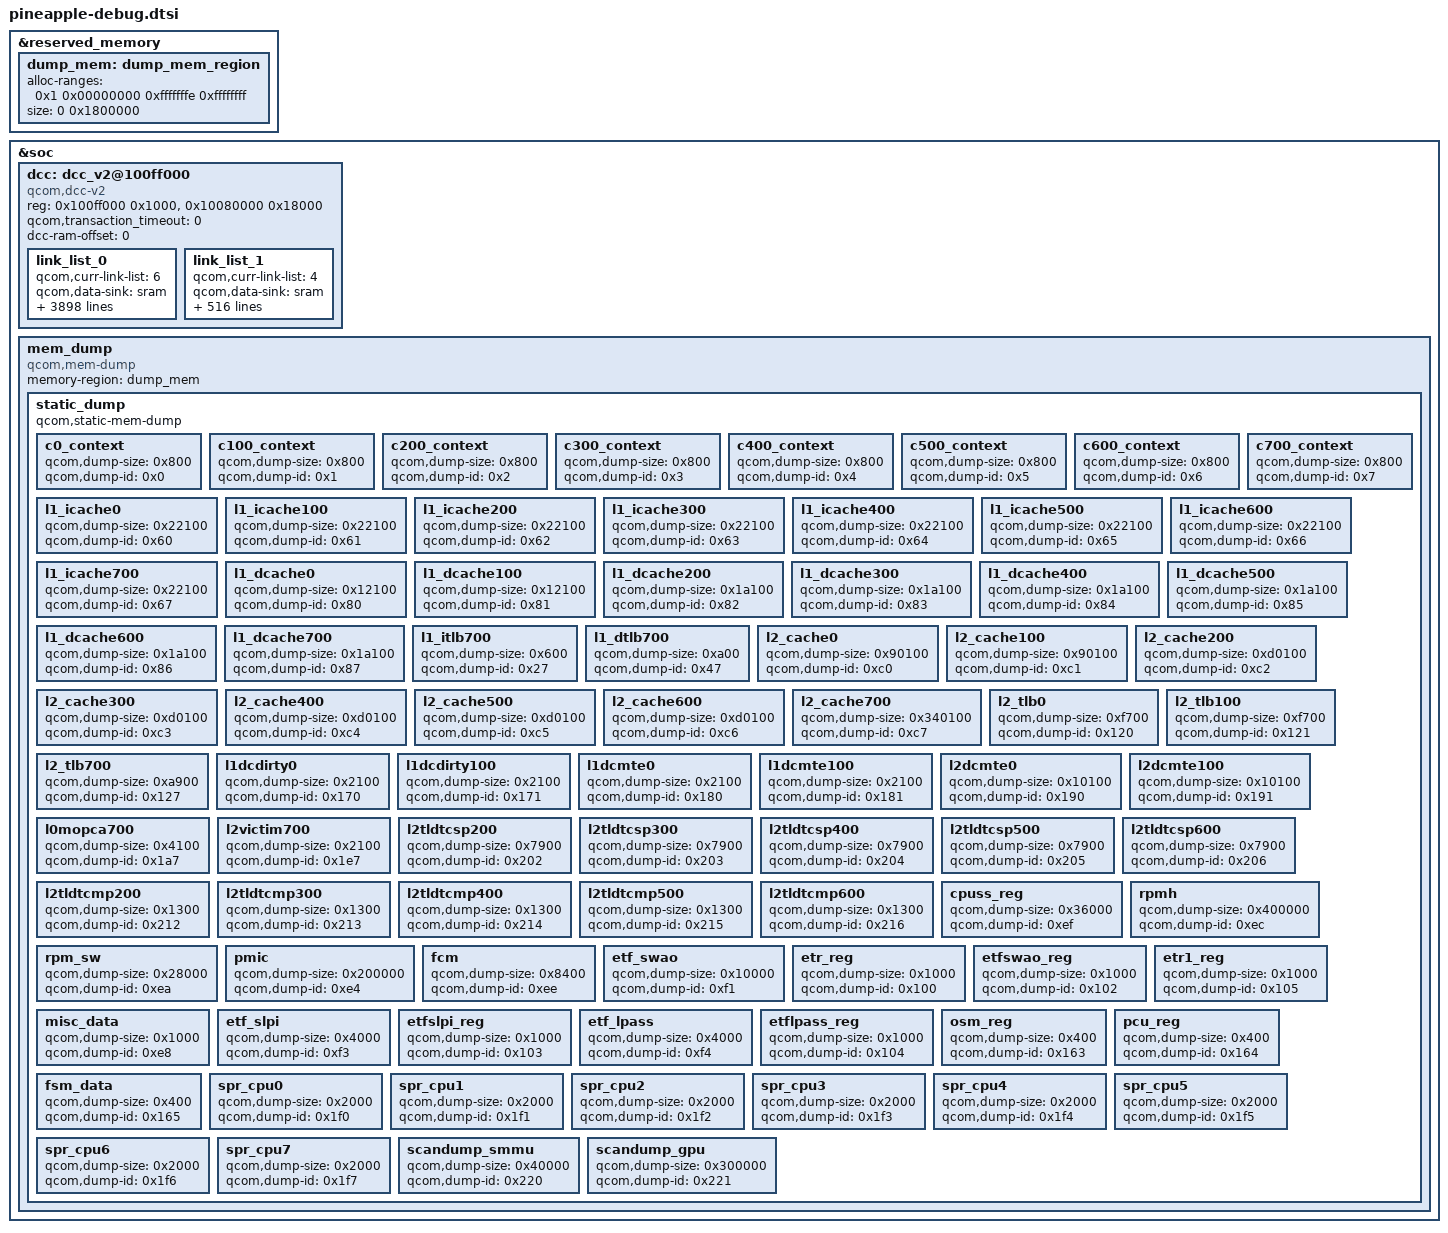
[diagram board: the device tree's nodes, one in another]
// SPDX-License-Identifier: BSD-3-Clause
/*
 * Copyright (c) 2022-2024 Qualcomm Innovation Center, Inc. All rights reserved.
 */

#include <dt-bindings/soc/qcom,dcc_v2.h>

&reserved_memory {
	#address-cells = <2>;
	#size-cells = <2>;
	ranges;

	dump_mem: dump_mem_region {
		alloc-ranges = <0x1 0x00000000 0xfffffffe 0xffffffff>;
		size = <0 0x1800000>;
	};
};

&soc {
	dcc: dcc_v2@100ff000 {
		compatible = "qcom,dcc-v2";
		reg = <0x100ff000 0x1000>,
		      <0x10080000 0x18000>;

		qcom,transaction_timeout = <0>;

		reg-names = "dcc-base", "dcc-ram-base";
		dcc-ram-offset = <0>;

		link_list_0 {
			qcom,curr-link-list = <6>;
			qcom,data-sink = "sram";
			qcom,link-list = <DCC_READ 0x68C0404 2 0>,
				<DCC_READ 0x68C0208 3 0>,
				<DCC_READ 0x68C0228 3 0>,
				<DCC_READ 0x68C0248 3 0>,
				<DCC_READ 0x68C0268 3 0>,
				<DCC_READ 0x68C040C 1 0>,
				<DCC_READ 0x68C0110 2 0>,
				<DCC_READ 0x68C011C 1 0>,
				<DCC_READ 0x7200404 2 0>,
				<DCC_READ 0x7200208 3 0>,
				<DCC_READ 0x7200228 3 0>,
				<DCC_READ 0x7200248 3 0>,
				<DCC_READ 0x7200268 3 0>,
				<DCC_READ 0x720040C 1 0>,
				<DCC_READ 0x7200110 2 0>,
				<DCC_READ 0x720011C 1 0>,
				<DCC_READ 0x7201c30 1 0>,
				<DCC_READ 0x7201ed0 1 0>,
				<DCC_READ 0x7202170 1 0>,
				<DCC_READ 0x7202410 1 0>,
				<DCC_READ 0x72026b0 1 0>,
				<DCC_READ 0x7202950 1 0>,
				<DCC_READ 0x7202bf0 1 0>,
				<DCC_READ 0x7202e90 1 0>,
				<DCC_READ 0x7203130 1 0>,
				<DCC_READ 0x72033d0 1 0>,
				<DCC_READ 0x7203670 1 0>,
				<DCC_READ 0x7201c48 1 0>,
				<DCC_READ 0x7201c60 1 0>,
				<DCC_READ 0x7201c78 1 0>,
				<DCC_READ 0x7201c90 1 0>,
				<DCC_READ 0x7201ca8 1 0>,
				<DCC_READ 0x7201cc0 1 0>,
				<DCC_READ 0x7201cd8 1 0>,
				<DCC_READ 0x7201cf0 1 0>,
				<DCC_READ 0x7201d08 1 0>,
				<DCC_READ 0x7201d20 1 0>,
				<DCC_READ 0x7201d38 1 0>,
				<DCC_READ 0x7201d50 1 0>,
				<DCC_READ 0x7201d68 1 0>,
				<DCC_READ 0x7201d80 1 0>,
				<DCC_READ 0x7201d98 1 0>,
				<DCC_READ 0x7201db0 1 0>,
				<DCC_READ 0x7201ee8 1 0>,
				<DCC_READ 0x7201f00 1 0>,
				<DCC_READ 0x7201f18 1 0>,
				<DCC_READ 0x7201f30 1 0>,
				<DCC_READ 0x7201f48 1 0>,
				<DCC_READ 0x7201f60 1 0>,
				<DCC_READ 0x7201f78 1 0>,
				<DCC_READ 0x7201f90 1 0>,
				<DCC_READ 0x7201fa8 1 0>,
				<DCC_READ 0x7201fc0 1 0>,
				<DCC_READ 0x7201fd8 1 0>,
				<DCC_READ 0x7201ff0 1 0>,
				<DCC_READ 0x7202008 1 0>,
				<DCC_READ 0x7202020 1 0>,
				<DCC_READ 0x7202038 1 0>,
				<DCC_READ 0x7202050 1 0>,
				<DCC_READ 0x7202188 1 0>,
				<DCC_READ 0x72021a0 1 0>,
				<DCC_READ 0x72021b8 1 0>,
				<DCC_READ 0x72021d0 1 0>,
				<DCC_READ 0x72021e8 1 0>,
				<DCC_READ 0x7202200 1 0>,
				<DCC_READ 0x7202218 1 0>,
				<DCC_READ 0x7202230 1 0>,
				<DCC_READ 0x7202248 1 0>,
				<DCC_READ 0x7202260 1 0>,
				<DCC_READ 0x7202278 1 0>,
				<DCC_READ 0x7202290 1 0>,
				<DCC_READ 0x72022a8 1 0>,
				<DCC_READ 0x72022c0 1 0>,
				<DCC_READ 0x72022d8 1 0>,
				<DCC_READ 0x72022f0 1 0>,
				<DCC_READ 0x7202428 1 0>,
				<DCC_READ 0x7202440 1 0>,
				<DCC_READ 0x7202458 1 0>,
				<DCC_READ 0x7202470 1 0>,
				<DCC_READ 0x7202488 1 0>,
				<DCC_READ 0x72024a0 1 0>,
				<DCC_READ 0x72024b8 1 0>,
				<DCC_READ 0x72024d0 1 0>,
				<DCC_READ 0x72024e8 1 0>,
				<DCC_READ 0x7202500 1 0>,
				<DCC_READ 0x7202518 1 0>,
				<DCC_READ 0x7202530 1 0>,
				<DCC_READ 0x7202548 1 0>,
				<DCC_READ 0x7202560 1 0>,
				<DCC_READ 0x7202578 1 0>,
				<DCC_READ 0x7202590 1 0>,
				<DCC_READ 0x72026c8 1 0>,
				<DCC_READ 0x72026e0 1 0>,
				<DCC_READ 0x72026f8 1 0>,
				<DCC_READ 0x7202710 1 0>,
				<DCC_READ 0x7202728 1 0>,
				<DCC_READ 0x7202740 1 0>,
				<DCC_READ 0x7202758 1 0>,
				<DCC_READ 0x7202770 1 0>,
				<DCC_READ 0x7202788 1 0>,
				<DCC_READ 0x72027a0 1 0>,
				<DCC_READ 0x72027b8 1 0>,
				<DCC_READ 0x72027d0 1 0>,
				<DCC_READ 0x72027e8 1 0>,
				<DCC_READ 0x7202800 1 0>,
				<DCC_READ 0x7202818 1 0>,
				<DCC_READ 0x7202830 1 0>,
				<DCC_READ 0x7202968 1 0>,
				<DCC_READ 0x7202980 1 0>,
				<DCC_READ 0x7202998 1 0>,
				<DCC_READ 0x72029b0 1 0>,
				<DCC_READ 0x72029c8 1 0>,
				<DCC_READ 0x72029e0 1 0>,
				<DCC_READ 0x72029f8 1 0>,
				<DCC_READ 0x7202a10 1 0>,
				<DCC_READ 0x7202a28 1 0>,
				<DCC_READ 0x7202a40 1 0>,
				<DCC_READ 0x7202a58 1 0>,
				<DCC_READ 0x7202a70 1 0>,
				<DCC_READ 0x7202a88 1 0>,
				<DCC_READ 0x7202aa0 1 0>,
				<DCC_READ 0x7202ab8 1 0>,
				<DCC_READ 0x7202ad0 1 0>,
				<DCC_READ 0x7202c08 1 0>,
				<DCC_READ 0x7202c20 1 0>,
				<DCC_READ 0x7202c38 1 0>,
				<DCC_READ 0x7202c50 1 0>,
				<DCC_READ 0x7202c68 1 0>,
				<DCC_READ 0x7202c80 1 0>,
				<DCC_READ 0x7202c98 1 0>,
				<DCC_READ 0x7202cb0 1 0>,
				<DCC_READ 0x7202cc8 1 0>,
				<DCC_READ 0x7202ce0 1 0>,
				<DCC_READ 0x7202cf8 1 0>,
				<DCC_READ 0x7202d10 1 0>,
				<DCC_READ 0x7202d28 1 0>,
				<DCC_READ 0x7202d40 1 0>,
				<DCC_READ 0x7202d58 1 0>,
				<DCC_READ 0x7202d70 1 0>,
				<DCC_READ 0x7202ea8 1 0>,
				<DCC_READ 0x7202ec0 1 0>,
				<DCC_READ 0x7202ed8 1 0>,
				<DCC_READ 0x7202ef0 1 0>,
				<DCC_READ 0x7202f08 1 0>,
				<DCC_READ 0x7202f20 1 0>,
				<DCC_READ 0x7202f38 1 0>,
				<DCC_READ 0x7202f50 1 0>,
				<DCC_READ 0x7202f68 1 0>,
				<DCC_READ 0x7202f80 1 0>,
				<DCC_READ 0x7202f98 1 0>,
				<DCC_READ 0x7202fb0 1 0>,
				<DCC_READ 0x7202fc8 1 0>,
				<DCC_READ 0x7202fe0 1 0>,
				<DCC_READ 0x7202ff8 1 0>,
				<DCC_READ 0x7203010 1 0>,
				<DCC_READ 0x7203148 1 0>,
				<DCC_READ 0x7203160 1 0>,
				<DCC_READ 0x7203178 1 0>,
				<DCC_READ 0x7203190 1 0>,
				<DCC_READ 0x72031a8 1 0>,
				<DCC_READ 0x72031c0 1 0>,
				<DCC_READ 0x72031d8 1 0>,
				<DCC_READ 0x72031f0 1 0>,
				<DCC_READ 0x7203208 1 0>,
				<DCC_READ 0x7203220 1 0>,
				<DCC_READ 0x7203238 1 0>,
				<DCC_READ 0x7203250 1 0>,
				<DCC_READ 0x7203268 1 0>,
				<DCC_READ 0x7203280 1 0>,
				<DCC_READ 0x7203298 1 0>,
				<DCC_READ 0x72032b0 1 0>,
				<DCC_READ 0x72033e8 1 0>,
				<DCC_READ 0x7203400 1 0>,
				<DCC_READ 0x7203418 1 0>,
				<DCC_READ 0x7203430 1 0>,
				<DCC_READ 0x7203448 1 0>,
				<DCC_READ 0x7203460 1 0>,
				<DCC_READ 0x7203478 1 0>,
				<DCC_READ 0x7203490 1 0>,
				<DCC_READ 0x72034a8 1 0>,
				<DCC_READ 0x72034c0 1 0>,
				<DCC_READ 0x72034d8 1 0>,
				<DCC_READ 0x72034f0 1 0>,
				<DCC_READ 0x7203508 1 0>,
				<DCC_READ 0x7203520 1 0>,
				<DCC_READ 0x7203538 1 0>,
				<DCC_READ 0x7203550 1 0>,
				<DCC_READ 0x7203688 1 0>,
				<DCC_READ 0x72036a0 1 0>,
				<DCC_READ 0x72036b8 1 0>,
				<DCC_READ 0x72036d0 1 0>,
				<DCC_READ 0x72036e8 1 0>,
				<DCC_READ 0x7203700 1 0>,
				<DCC_READ 0x7203718 1 0>,
				<DCC_READ 0x7203730 1 0>,
				<DCC_READ 0x7203748 1 0>,
				<DCC_READ 0x7203760 1 0>,
				<DCC_READ 0x7203778 1 0>,
				<DCC_READ 0x7203790 1 0>,
				<DCC_READ 0x72037a8 1 0>,
				<DCC_READ 0x72037c0 1 0>,
				<DCC_READ 0x72037d8 1 0>,
				<DCC_READ 0x72037f0 1 0>,
				<DCC_READ 0x323C0404 2 0>,
				<DCC_READ 0x323C0208 3 0>,
				<DCC_READ 0x323C0228 3 0>,
				<DCC_READ 0x323C0248 3 0>,
				<DCC_READ 0x323C0268 3 0>,
				<DCC_READ 0x323C040C 1 0>,
				<DCC_READ 0x323C0110 2 0>,
				<DCC_READ 0x323C011C 1 0>,
				<DCC_READ 0x320A4404 2 0>,
				<DCC_READ 0x320A4208 3 0>,
				<DCC_READ 0x320A4228 3 0>,
				<DCC_READ 0x320A4248 3 0>,
				<DCC_READ 0x320A4268 3 0>,
				<DCC_READ 0x320A440C 1 0>,
				<DCC_READ 0x320A4110 2 0>,
				<DCC_READ 0x320A411C 1 0>,
				<DCC_READ 0x320A4D30 1 0>,
				<DCC_READ 0x320A4Fd0 1 0>,
				<DCC_READ 0x320A5270 1 0>,
				<DCC_READ 0x320A5510 1 0>,
				<DCC_READ 0x320A57B0 1 0>,
				<DCC_READ 0x320A5A50 1 0>,
				<DCC_READ 0x320A5CF0 1 0>,
				<DCC_READ 0x320A5F90 1 0>,
				<DCC_READ 0x320a4d48 1 0>,
				<DCC_READ 0x320a4d60 1 0>,
				<DCC_READ 0x320a4d78 1 0>,
				<DCC_READ 0x320a4d90 1 0>,
				<DCC_READ 0x320a4da8 1 0>,
				<DCC_READ 0x320a4dc0 1 0>,
				<DCC_READ 0x320a4dd8 1 0>,
				<DCC_READ 0x320a4df0 1 0>,
				<DCC_READ 0x320a4e08 1 0>,
				<DCC_READ 0x320a4e20 1 0>,
				<DCC_READ 0x320a4e38 1 0>,
				<DCC_READ 0x320a4e50 1 0>,
				<DCC_READ 0x320a4e68 1 0>,
				<DCC_READ 0x320a4e80 1 0>,
				<DCC_READ 0x320a4e98 1 0>,
				<DCC_READ 0x320a4eb0 1 0>,
				<DCC_READ 0x320a4fe8 1 0>,
				<DCC_READ 0x320a5000 1 0>,
				<DCC_READ 0x320a5018 1 0>,
				<DCC_READ 0x320a5030 1 0>,
				<DCC_READ 0x320a5048 1 0>,
				<DCC_READ 0x320a5060 1 0>,
				<DCC_READ 0x320a5078 1 0>,
				<DCC_READ 0x320a5090 1 0>,
				<DCC_READ 0x320a50a8 1 0>,
				<DCC_READ 0x320a50c0 1 0>,
				<DCC_READ 0x320a50d8 1 0>,
				<DCC_READ 0x320a50f0 1 0>,
				<DCC_READ 0x320a5108 1 0>,
				<DCC_READ 0x320a5120 1 0>,
				<DCC_READ 0x320a5138 1 0>,
				<DCC_READ 0x320a5150 1 0>,
				<DCC_READ 0x320a5288 1 0>,
				<DCC_READ 0x320a52a0 1 0>,
				<DCC_READ 0x320a52b8 1 0>,
				<DCC_READ 0x320a52d0 1 0>,
				<DCC_READ 0x320a52e8 1 0>,
				<DCC_READ 0x320a5300 1 0>,
				<DCC_READ 0x320a5318 1 0>,
				<DCC_READ 0x320a5330 1 0>,
				<DCC_READ 0x320a5348 1 0>,
				<DCC_READ 0x320a5360 1 0>,
				<DCC_READ 0x320a5378 1 0>,
				<DCC_READ 0x320a5390 1 0>,
				<DCC_READ 0x320a53a8 1 0>,
				<DCC_READ 0x320a53c0 1 0>,
				<DCC_READ 0x320a53d8 1 0>,
				<DCC_READ 0x320a53f0 1 0>,
				<DCC_READ 0x320a5528 1 0>,
				<DCC_READ 0x320a5540 1 0>,
				<DCC_READ 0x320a5558 1 0>,
				<DCC_READ 0x320a5570 1 0>,
				<DCC_READ 0x320a5588 1 0>,
				<DCC_READ 0x320a55a0 1 0>,
				<DCC_READ 0x320a55b8 1 0>,
				<DCC_READ 0x320a55d0 1 0>,
				<DCC_READ 0x320a55e8 1 0>,
				<DCC_READ 0x320a5600 1 0>,
				<DCC_READ 0x320a5618 1 0>,
				<DCC_READ 0x320a5630 1 0>,
				<DCC_READ 0x320a5648 1 0>,
				<DCC_READ 0x320a5660 1 0>,
				<DCC_READ 0x320a5678 1 0>,
				<DCC_READ 0x320a5690 1 0>,
				<DCC_READ 0x320a57c8 1 0>,
				<DCC_READ 0x320a57e0 1 0>,
				<DCC_READ 0x320a57f8 1 0>,
				<DCC_READ 0x320a5810 1 0>,
				<DCC_READ 0x320a5828 1 0>,
				<DCC_READ 0x320a5840 1 0>,
				<DCC_READ 0x320a5858 1 0>,
				<DCC_READ 0x320a5870 1 0>,
				<DCC_READ 0x320a5888 1 0>,
				<DCC_READ 0x320a58a0 1 0>,
				<DCC_READ 0x320a58b8 1 0>,
				<DCC_READ 0x320a58d0 1 0>,
				<DCC_READ 0x320a58e8 1 0>,
				<DCC_READ 0x320a5900 1 0>,
				<DCC_READ 0x320a5918 1 0>,
				<DCC_READ 0x320a5930 1 0>,
				<DCC_READ 0x320a5a68 1 0>,
				<DCC_READ 0x320a5a80 1 0>,
				<DCC_READ 0x320a5a98 1 0>,
				<DCC_READ 0x320a5ab0 1 0>,
				<DCC_READ 0x320a5ac8 1 0>,
				<DCC_READ 0x320a5ae0 1 0>,
				<DCC_READ 0x320a5af8 1 0>,
				<DCC_READ 0x320a5b10 1 0>,
				<DCC_READ 0x320a5b28 1 0>,
				<DCC_READ 0x320a5b40 1 0>,
				<DCC_READ 0x320a5b58 1 0>,
				<DCC_READ 0x320a5b70 1 0>,
				<DCC_READ 0x320a5b88 1 0>,
				<DCC_READ 0x320a5ba0 1 0>,
				<DCC_READ 0x320a5bb8 1 0>,
				<DCC_READ 0x320a5bd0 1 0>,
				<DCC_READ 0x320a5d08 1 0>,
				<DCC_READ 0x320a5d20 1 0>,
				<DCC_READ 0x320a5d38 1 0>,
				<DCC_READ 0x320a5d50 1 0>,
				<DCC_READ 0x320a5d68 1 0>,
				<DCC_READ 0x320a5d80 1 0>,
				<DCC_READ 0x320a5d98 1 0>,
				<DCC_READ 0x320a5db0 1 0>,
				<DCC_READ 0x320a5dc8 1 0>,
				<DCC_READ 0x320a5de0 1 0>,
				<DCC_READ 0x320a5df8 1 0>,
				<DCC_READ 0x320a5e10 1 0>,
				<DCC_READ 0x320a5e28 1 0>,
				<DCC_READ 0x320a5e40 1 0>,
				<DCC_READ 0x320a5e58 1 0>,
				<DCC_READ 0x320a5e70 1 0>,
				<DCC_READ 0x320a5fa8 1 0>,
				<DCC_READ 0x320a5fc0 1 0>,
				<DCC_READ 0x320a5fd8 1 0>,
				<DCC_READ 0x320a5ff0 1 0>,
				<DCC_READ 0x320a6008 1 0>,
				<DCC_READ 0x320a6020 1 0>,
				<DCC_READ 0x320a6038 1 0>,
				<DCC_READ 0x320a6050 1 0>,
				<DCC_READ 0x320a6068 1 0>,
				<DCC_READ 0x320a6080 1 0>,
				<DCC_READ 0x320a6098 1 0>,
				<DCC_READ 0x320a60b0 1 0>,
				<DCC_READ 0x320a60c8 1 0>,
				<DCC_READ 0x320a60e0 1 0>,
				<DCC_READ 0x320a60f8 1 0>,
				<DCC_READ 0x4082028 1 0>,
				<DCC_READ 0x4140404 2 0>,
				<DCC_READ 0x4140208 3 0>,
				<DCC_READ 0x4140228 3 0>,
				<DCC_READ 0x4140248 3 0>,
				<DCC_READ 0x4140268 3 0>,
				<DCC_READ 0x414040C 1 0>,
				<DCC_READ 0x4140110 2 0>,
				<DCC_READ 0x414011C 1 0>,
				<DCC_READ 0x4200404 2 0>,
				<DCC_READ 0x4200208 3 0>,
				<DCC_READ 0x4200228 3 0>,
				<DCC_READ 0x4200248 3 0>,
				<DCC_READ 0x4200268 3 0>,
				<DCC_READ 0x420040C 1 0>,
				<DCC_READ 0x4200110 2 0>,
				<DCC_READ 0x420011C 1 0>,
				<DCC_READ 0x4200d30 1 0>,
				<DCC_READ 0x4200fd0 1 0>,
				<DCC_READ 0x4201270 1 0>,
				<DCC_READ 0x4201510 1 0>,
				<DCC_READ 0x42017b0 1 0>,
				<DCC_READ 0x4201a50 1 0>,
				<DCC_READ 0x4201cf0 1 0>,
				<DCC_READ 0x4201f90 1 0>,
				<DCC_READ 0x4202230 1 0>,
				<DCC_READ 0x42024d0 1 0>,
				<DCC_READ 0x4202770 1 0>,
				<DCC_READ 0x4202a10 1 0>,
				<DCC_READ 0x4202cb0 1 0>,
				<DCC_READ 0x4202f50 1 0>,
				<DCC_READ 0x4200d48 1 0>,
				<DCC_READ 0x4200d60 1 0>,
				<DCC_READ 0x4200d78 1 0>,
				<DCC_READ 0x4200d90 1 0>,
				<DCC_READ 0x4200da8 1 0>,
				<DCC_READ 0x4200dc0 1 0>,
				<DCC_READ 0x4200dd8 1 0>,
				<DCC_READ 0x4200df0 1 0>,
				<DCC_READ 0x4200e08 1 0>,
				<DCC_READ 0x4200e20 1 0>,
				<DCC_READ 0x4200e38 1 0>,
				<DCC_READ 0x4200e50 1 0>,
				<DCC_READ 0x4200e68 1 0>,
				<DCC_READ 0x4200e80 1 0>,
				<DCC_READ 0x4200e98 1 0>,
				<DCC_READ 0x4200eb0 1 0>,
				<DCC_READ 0x4200fe8 1 0>,
				<DCC_READ 0x4201000 1 0>,
				<DCC_READ 0x4201018 1 0>,
				<DCC_READ 0x4201030 1 0>,
				<DCC_READ 0x4201048 1 0>,
				<DCC_READ 0x4201060 1 0>,
				<DCC_READ 0x4201078 1 0>,
				<DCC_READ 0x4201090 1 0>,
				<DCC_READ 0x42010a8 1 0>,
				<DCC_READ 0x42010c0 1 0>,
				<DCC_READ 0x42010d8 1 0>,
				<DCC_READ 0x42010f0 1 0>,
				<DCC_READ 0x4201108 1 0>,
				<DCC_READ 0x4201120 1 0>,
				<DCC_READ 0x4201138 1 0>,
				<DCC_READ 0x4201150 1 0>,
				<DCC_READ 0x4201288 1 0>,
				<DCC_READ 0x42012a0 1 0>,
				<DCC_READ 0x42012b8 1 0>,
				<DCC_READ 0x42012d0 1 0>,
				<DCC_READ 0x42012e8 1 0>,
				<DCC_READ 0x4201300 1 0>,
				<DCC_READ 0x4201318 1 0>,
				<DCC_READ 0x4201330 1 0>,
				<DCC_READ 0x4201348 1 0>,
				<DCC_READ 0x4201360 1 0>,
				<DCC_READ 0x4201378 1 0>,
				<DCC_READ 0x4201390 1 0>,
				<DCC_READ 0x42013a8 1 0>,
				<DCC_READ 0x42013c0 1 0>,
				<DCC_READ 0x42013d8 1 0>,
				<DCC_READ 0x42013f0 1 0>,
				<DCC_READ 0x4201528 1 0>,
				<DCC_READ 0x4201540 1 0>,
				<DCC_READ 0x4201558 1 0>,
				<DCC_READ 0x4201570 1 0>,
				<DCC_READ 0x4201588 1 0>,
				<DCC_READ 0x42015a0 1 0>,
				<DCC_READ 0x42015b8 1 0>,
				<DCC_READ 0x42015d0 1 0>,
				<DCC_READ 0x42015e8 1 0>,
				<DCC_READ 0x4201600 1 0>,
				<DCC_READ 0x4201618 1 0>,
				<DCC_READ 0x4201630 1 0>,
				<DCC_READ 0x4201648 1 0>,
				<DCC_READ 0x4201660 1 0>,
				<DCC_READ 0x4201678 1 0>,
				<DCC_READ 0x4201690 1 0>,
				<DCC_READ 0x42017c8 1 0>,
				<DCC_READ 0x42017e0 1 0>,
				<DCC_READ 0x42017f8 1 0>,
				<DCC_READ 0x4201810 1 0>,
				<DCC_READ 0x4201828 1 0>,
				<DCC_READ 0x4201840 1 0>,
				<DCC_READ 0x4201858 1 0>,
				<DCC_READ 0x4201870 1 0>,
				<DCC_READ 0x4201888 1 0>,
				<DCC_READ 0x42018a0 1 0>,
				<DCC_READ 0x42018b8 1 0>,
				<DCC_READ 0x42018d0 1 0>,
				<DCC_READ 0x42018e8 1 0>,
				<DCC_READ 0x4201900 1 0>,
				<DCC_READ 0x4201918 1 0>,
				<DCC_READ 0x4201930 1 0>,
				<DCC_READ 0x4201a68 1 0>,
				<DCC_READ 0x4201a80 1 0>,
				<DCC_READ 0x4201a98 1 0>,
				<DCC_READ 0x4201ab0 1 0>,
				<DCC_READ 0x4201ac8 1 0>,
				<DCC_READ 0x4201ae0 1 0>,
				<DCC_READ 0x4201af8 1 0>,
				<DCC_READ 0x4201b10 1 0>,
				<DCC_READ 0x4201b28 1 0>,
				<DCC_READ 0x4201b40 1 0>,
				<DCC_READ 0x4201b58 1 0>,
				<DCC_READ 0x4201b70 1 0>,
				<DCC_READ 0x4201b88 1 0>,
				<DCC_READ 0x4201ba0 1 0>,
				<DCC_READ 0x4201bb8 1 0>,
				<DCC_READ 0x4201bd0 1 0>,
				<DCC_READ 0x4201d08 1 0>,
				<DCC_READ 0x4201d20 1 0>,
				<DCC_READ 0x4201d38 1 0>,
				<DCC_READ 0x4201d50 1 0>,
				<DCC_READ 0x4201d68 1 0>,
				<DCC_READ 0x4201d80 1 0>,
				<DCC_READ 0x4201d98 1 0>,
				<DCC_READ 0x4201db0 1 0>,
				<DCC_READ 0x4201dc8 1 0>,
				<DCC_READ 0x4201de0 1 0>,
				<DCC_READ 0x4201df8 1 0>,
				<DCC_READ 0x4201e10 1 0>,
				<DCC_READ 0x4201e28 1 0>,
				<DCC_READ 0x4201e40 1 0>,
				<DCC_READ 0x4201e58 1 0>,
				<DCC_READ 0x4201e70 1 0>,
				<DCC_READ 0x4201fa8 1 0>,
				<DCC_READ 0x4201fc0 1 0>,
				<DCC_READ 0x4201fd8 1 0>,
				<DCC_READ 0x4201ff0 1 0>,
				<DCC_READ 0x4202008 1 0>,
				<DCC_READ 0x4202020 1 0>,
				<DCC_READ 0x4202038 1 0>,
				<DCC_READ 0x4202050 1 0>,
				<DCC_READ 0x4202068 1 0>,
				<DCC_READ 0x4202080 1 0>,
				<DCC_READ 0x4202098 1 0>,
				<DCC_READ 0x42020b0 1 0>,
				<DCC_READ 0x42020c8 1 0>,
				<DCC_READ 0x42020e0 1 0>,
				<DCC_READ 0x42020f8 1 0>,
				<DCC_READ 0x4202110 1 0>,
				<DCC_READ 0x4202248 1 0>,
				<DCC_READ 0x4202260 1 0>,
				<DCC_READ 0x4202278 1 0>,
				<DCC_READ 0x4202290 1 0>,
				<DCC_READ 0x42022a8 1 0>,
				<DCC_READ 0x42022c0 1 0>,
				<DCC_READ 0x42022d8 1 0>,
				<DCC_READ 0x42022f0 1 0>,
				<DCC_READ 0x4202308 1 0>,
				<DCC_READ 0x4202320 1 0>,
				<DCC_READ 0x4202338 1 0>,
				<DCC_READ 0x4202350 1 0>,
				<DCC_READ 0x4202368 1 0>,
				<DCC_READ 0x4202380 1 0>,
				<DCC_READ 0x4202398 1 0>,
				<DCC_READ 0x42023b0 1 0>,
				<DCC_READ 0x42024e8 1 0>,
				<DCC_READ 0x4202500 1 0>,
				<DCC_READ 0x4202518 1 0>,
				<DCC_READ 0x4202530 1 0>,
				<DCC_READ 0x4202548 1 0>,
				<DCC_READ 0x4202560 1 0>,
				<DCC_READ 0x4202578 1 0>,
				<DCC_READ 0x4202590 1 0>,
				<DCC_READ 0x42025a8 1 0>,
				<DCC_READ 0x42025c0 1 0>,
				<DCC_READ 0x42025d8 1 0>,
				<DCC_READ 0x42025f0 1 0>,
				<DCC_READ 0x4202608 1 0>,
				<DCC_READ 0x4202620 1 0>,
				<DCC_READ 0x4202638 1 0>,
				<DCC_READ 0x4202650 1 0>,
				<DCC_READ 0x4202788 1 0>,
				<DCC_READ 0x42027a0 1 0>,
				<DCC_READ 0x42027b8 1 0>,
				<DCC_READ 0x42027d0 1 0>,
				<DCC_READ 0x42027e8 1 0>,
				<DCC_READ 0x4202800 1 0>,
				<DCC_READ 0x4202818 1 0>,
				<DCC_READ 0x4202830 1 0>,
				<DCC_READ 0x4202848 1 0>,
				<DCC_READ 0x4202860 1 0>,
				<DCC_READ 0x4202878 1 0>,
				<DCC_READ 0x4202890 1 0>,
				<DCC_READ 0x42028a8 1 0>,
				<DCC_READ 0x42028c0 1 0>,
				<DCC_READ 0x42028d8 1 0>,
				<DCC_READ 0x42028f0 1 0>,
				<DCC_READ 0x4202a28 1 0>,
				<DCC_READ 0x4202a40 1 0>,
				<DCC_READ 0x4202a58 1 0>,
				<DCC_READ 0x4202a70 1 0>,
				<DCC_READ 0x4202a88 1 0>,
				<DCC_READ 0x4202aa0 1 0>,
				<DCC_READ 0x4202ab8 1 0>,
				<DCC_READ 0x4202ad0 1 0>,
				<DCC_READ 0x4202ae8 1 0>,
				<DCC_READ 0x4202b00 1 0>,
				<DCC_READ 0x4202b18 1 0>,
				<DCC_READ 0x4202b30 1 0>,
				<DCC_READ 0x4202b48 1 0>,
				<DCC_READ 0x4202b60 1 0>,
				<DCC_READ 0x4202b78 1 0>,
				<DCC_READ 0x4202b90 1 0>,
				<DCC_READ 0x4202cc8 1 0>,
				<DCC_READ 0x4202ce0 1 0>,
				<DCC_READ 0x4202cf8 1 0>,
				<DCC_READ 0x4202d10 1 0>,
				<DCC_READ 0x4202d28 1 0>,
				<DCC_READ 0x4202d40 1 0>,
				<DCC_READ 0x4202d58 1 0>,
				<DCC_READ 0x4202d70 1 0>,
				<DCC_READ 0x4202d88 1 0>,
				<DCC_READ 0x4202da0 1 0>,
				<DCC_READ 0x4202db8 1 0>,
				<DCC_READ 0x4202dd0 1 0>,
				<DCC_READ 0x4202de8 1 0>,
				<DCC_READ 0x4202e00 1 0>,
				<DCC_READ 0x4202e18 1 0>,
				<DCC_READ 0x4202e30 1 0>,
				<DCC_READ 0x4202f68 1 0>,
				<DCC_READ 0x4202f80 1 0>,
				<DCC_READ 0x4202f98 1 0>,
				<DCC_READ 0x4202fb0 1 0>,
				<DCC_READ 0x4202fc8 1 0>,
				<DCC_READ 0x4202fe0 1 0>,
				<DCC_READ 0x4202ff8 1 0>,
				<DCC_READ 0x4203010 1 0>,
				<DCC_READ 0x4203028 1 0>,
				<DCC_READ 0x4203040 1 0>,
				<DCC_READ 0x4203058 1 0>,
				<DCC_READ 0x4203070 1 0>,
				<DCC_READ 0x4203088 1 0>,
				<DCC_READ 0x42030a0 1 0>,
				<DCC_READ 0x42030b8 1 0>,
				<DCC_READ 0x42030d0 1 0>,
				<DCC_READ 0x6E0A100 1 0>,
				<DCC_READ 0x6E0A0AC 1 0>,
				<DCC_READ 0x6E0A0B0 1 0>,
				<DCC_READ 0x6E21104 1 0>,
				<DCC_READ 0x6E21108 1 0>,
				<DCC_READ 0x6E212AC 1 0>,
				<DCC_READ 0x6E212B0 1 0>,
				<DCC_READ 0x6E21300 1 0>,
				<DCC_READ 0x6E0A000 1 0>,
				<DCC_READ 0x7402048 1 0>,
				<DCC_READ 0x7402040 1 0>,
				<DCC_READ 0x25a01000 6 0>,
				<DCC_READ 0x25a00000 6 0>,
				<DCC_READ 0x25a03000 6 0>,
				<DCC_READ 0x25a04000 6 0>,
				<DCC_READ 0x25a02000 6 0>,
				<DCC_READ 0x25a05000 6 0>,
				<DCC_READ 0x25a06000 6 0>,
				<DCC_READ 0x25a07000 6 0>,
				<DCC_READ 0x25a08000 6 0>,
				<DCC_READ 0x25a09000 6 0>,
				<DCC_READ 0x25a0a000 6 0>,
				<DCC_READ 0x25a0b000 6 0>,
				<DCC_READ 0x25a0c000 6 0>,
				<DCC_READ 0x25a0d000 6 0>,
				<DCC_READ 0x25a0e000 6 0>,
				<DCC_READ 0x25a0f000 6 0>,
				<DCC_READ 0x25a10000 6 0>,
				<DCC_READ 0x25a11000 6 0>,
				<DCC_READ 0x25a12000 6 0>,
				<DCC_READ 0x25a13000 6 0>,
				<DCC_READ 0x25a14000 6 0>,
				<DCC_READ 0x25a15000 6 0>,
				<DCC_READ 0x25a16000 6 0>,
				<DCC_READ 0x25a17000 6 0>,
				<DCC_READ 0x25a18000 6 0>,
				<DCC_READ 0x25a19000 6 0>,
				<DCC_READ 0x25a1a000 6 0>,
				<DCC_READ 0x25a1b000 6 0>,
				<DCC_READ 0x25a1c000 6 0>,
				<DCC_READ 0x25a1d000 6 0>,
				<DCC_READ 0x25a1e000 6 0>,
				<DCC_READ 0x25a1f000 6 0>,
				<DCC_READ 0x25001000 6 0>,
				<DCC_READ 0x25000000 6 0>,
				<DCC_READ 0x25003000 6 0>,
				<DCC_READ 0x25004000 6 0>,
				<DCC_READ 0x25002000 6 0>,
				<DCC_READ 0x25005000 6 0>,
				<DCC_READ 0x25006000 6 0>,
				<DCC_READ 0x25007000 6 0>,
				<DCC_READ 0x25008000 6 0>,
				<DCC_READ 0x25009000 6 0>,
				<DCC_READ 0x2500a000 6 0>,
				<DCC_READ 0x2500b000 6 0>,
				<DCC_READ 0x2500c000 6 0>,
				<DCC_READ 0x2500d000 6 0>,
				<DCC_READ 0x2500e000 6 0>,
				<DCC_READ 0x2500f000 6 0>,
				<DCC_READ 0x25010000 6 0>,
				<DCC_READ 0x25011000 6 0>,
				<DCC_READ 0x25012000 6 0>,
				<DCC_READ 0x25013000 6 0>,
				<DCC_READ 0x25014000 6 0>,
				<DCC_READ 0x25015000 6 0>,
				<DCC_READ 0x25016000 6 0>,
				<DCC_READ 0x25017000 6 0>,
				<DCC_READ 0x25018000 6 0>,
				<DCC_READ 0x25019000 6 0>,
				<DCC_READ 0x2501a000 6 0>,
				<DCC_READ 0x2501b000 6 0>,
				<DCC_READ 0x2501c000 6 0>,
				<DCC_READ 0x2501d000 6 0>,
				<DCC_READ 0x2501e000 6 0>,
				<DCC_READ 0x2501f000 6 0>,
				<DCC_READ 0x25201000 6 0>,
				<DCC_READ 0x25200000 6 0>,
				<DCC_READ 0x25203000 6 0>,
				<DCC_READ 0x25204000 6 0>,
				<DCC_READ 0x25202000 6 0>,
				<DCC_READ 0x25205000 6 0>,
				<DCC_READ 0x25206000 6 0>,
				<DCC_READ 0x25207000 6 0>,
				<DCC_READ 0x25208000 6 0>,
				<DCC_READ 0x25209000 6 0>,
				<DCC_READ 0x2520a000 6 0>,
				<DCC_READ 0x2520b000 6 0>,
				<DCC_READ 0x2520c000 6 0>,
				<DCC_READ 0x2520d000 6 0>,
				<DCC_READ 0x2520e000 6 0>,
				<DCC_READ 0x2520f000 6 0>,
				<DCC_READ 0x25210000 6 0>,
				<DCC_READ 0x25211000 6 0>,
				<DCC_READ 0x25212000 6 0>,
				<DCC_READ 0x25213000 6 0>,
				<DCC_READ 0x25214000 6 0>,
				<DCC_READ 0x25215000 6 0>,
				<DCC_READ 0x25216000 6 0>,
				<DCC_READ 0x25217000 6 0>,
				<DCC_READ 0x25218000 6 0>,
				<DCC_READ 0x25219000 6 0>,
				<DCC_READ 0x2521a000 6 0>,
				<DCC_READ 0x2521b000 6 0>,
				<DCC_READ 0x2521c000 6 0>,
				<DCC_READ 0x2521d000 6 0>,
				<DCC_READ 0x2521e000 6 0>,
				<DCC_READ 0x2521f000 6 0>,
				<DCC_READ 0x25401000 6 0>,
				<DCC_READ 0x25400000 6 0>,
				<DCC_READ 0x25403000 6 0>,
				<DCC_READ 0x25404000 6 0>,
				<DCC_READ 0x25402000 6 0>,
				<DCC_READ 0x25405000 6 0>,
				<DCC_READ 0x25406000 6 0>,
				<DCC_READ 0x25407000 6 0>,
				<DCC_READ 0x25408000 6 0>,
				<DCC_READ 0x25409000 6 0>,
				<DCC_READ 0x2540a000 6 0>,
				<DCC_READ 0x2540b000 6 0>,
				<DCC_READ 0x2540c000 6 0>,
				<DCC_READ 0x2540d000 6 0>,
				<DCC_READ 0x2540e000 6 0>,
				<DCC_READ 0x2540f000 6 0>,
				<DCC_READ 0x25410000 6 0>,
				<DCC_READ 0x25411000 6 0>,
				<DCC_READ 0x25412000 6 0>,
				<DCC_READ 0x25413000 6 0>,
				<DCC_READ 0x25414000 6 0>,
				<DCC_READ 0x25415000 6 0>,
				<DCC_READ 0x25416000 6 0>,
				<DCC_READ 0x25417000 6 0>,
				<DCC_READ 0x25418000 6 0>,
				<DCC_READ 0x25419000 6 0>,
				<DCC_READ 0x2541a000 6 0>,
				<DCC_READ 0x2541b000 6 0>,
				<DCC_READ 0x2541c000 6 0>,
				<DCC_READ 0x2541d000 6 0>,
				<DCC_READ 0x2541e000 6 0>,
				<DCC_READ 0x2541f000 6 0>,
				<DCC_READ 0x25601000 6 0>,
				<DCC_READ 0x25600000 6 0>,
				<DCC_READ 0x25603000 6 0>,
				<DCC_READ 0x25604000 6 0>,
				<DCC_READ 0x25602000 6 0>,
				<DCC_READ 0x25605000 6 0>,
				<DCC_READ 0x25606000 6 0>,
				<DCC_READ 0x25607000 6 0>,
				<DCC_READ 0x25608000 6 0>,
				<DCC_READ 0x25609000 6 0>,
				<DCC_READ 0x2560a000 6 0>,
				<DCC_READ 0x2560b000 6 0>,
				<DCC_READ 0x2560c000 6 0>,
				<DCC_READ 0x2560d000 6 0>,
				<DCC_READ 0x2560e000 6 0>,
				<DCC_READ 0x2560f000 6 0>,
				<DCC_READ 0x25610000 6 0>,
				<DCC_READ 0x25611000 6 0>,
				<DCC_READ 0x25612000 6 0>,
				<DCC_READ 0x25613000 6 0>,
				<DCC_READ 0x25614000 6 0>,
				<DCC_READ 0x25615000 6 0>,
				<DCC_READ 0x25616000 6 0>,
				<DCC_READ 0x25617000 6 0>,
				<DCC_READ 0x25618000 6 0>,
				<DCC_READ 0x25619000 6 0>,
				<DCC_READ 0x2561a000 6 0>,
				<DCC_READ 0x2561b000 6 0>,
				<DCC_READ 0x2561c000 6 0>,
				<DCC_READ 0x2561d000 6 0>,
				<DCC_READ 0x2561e000 6 0>,
				<DCC_READ 0x2561f000 6 0>,
				<DCC_READ 0x25822870 4 0>,
				<DCC_READ 0x25A22870 4 0>,
				<DCC_READ 0x25823000 3 0>,
				<DCC_READ 0x2582320C 21 0>,
				<DCC_READ 0x25A23000 3 0>,
				<DCC_READ 0x25A2320C 21 0>,
				<DCC_READ 0x25023000 3 0>,
				<DCC_READ 0x2502320C 21 0>,
				<DCC_READ 0x25223000 3 0>,
				<DCC_READ 0x2522320C 21 0>,
				<DCC_READ 0x25423000 3 0>,
				<DCC_READ 0x2542320C 21 0>,
				<DCC_READ 0x25623000 3 0>,
				<DCC_READ 0x2562320C 21 0>,
				<DCC_READ 0x2587601C 3 0>,
				<DCC_READ 0x25A7601C 3 0>,
				<DCC_READ 0x2587603C 2 0>,
				<DCC_READ 0x25A7603C 2 0>,
				<DCC_READ 0x25876058 2 0>,
				<DCC_READ 0x25A76058 2 0>,
				<DCC_READ 0x25021000 64 0>,
				<DCC_READ 0x25421000 64 0>,
				<DCC_READ 0x25221000 64 0>,
				<DCC_READ 0x25621000 64 0>,
				<DCC_READ 0x1780005C 1 0>,
				<DCC_READ 0x1781005C 1 0>,
				<DCC_READ 0x1782005C 1 0>,
				<DCC_READ 0x1783005C 1 0>,
				<DCC_READ 0x1784005C 1 0>,
				<DCC_READ 0x1785005C 1 0>,
				<DCC_READ 0x1786005C 1 0>,
				<DCC_READ 0x1787005C 1 0>,
				<DCC_READ 0x1740003C 1 0>,
				<DCC_READ 0x17600238 1 0>,
				<DCC_READ 0x17600240 11 0>,
				<DCC_READ 0x17600530 1 0>,
				<DCC_READ 0x1760051C 1 0>,
				<DCC_READ 0x17600524 1 0>,
				<DCC_READ 0x1760052C 1 0>,
				<DCC_READ 0x17600518 1 0>,
				<DCC_READ 0x17600520 1 0>,
				<DCC_READ 0x17600528 1 0>,
				<DCC_READ 0x17600404 3 0>,
				<DCC_READ 0x1760041C 3 0>,
				<DCC_READ 0x17600434 1 0>,
				<DCC_READ 0x1760043C 1 0>,
				<DCC_READ 0x17600440 1 0>,
				<DCC_READ 0x17400438 1 0>,
				<DCC_READ 0x17600044 1 0>,
				<DCC_READ 0x17600500 1 0>,
				<DCC_READ 0x17600504 5 0>,
				<DCC_READ 0x17900908 1 0>,
				<DCC_READ 0x17900C18 1 0>,
				<DCC_READ 0x17901908 1 0>,
				<DCC_READ 0x17901C18 1 0>,
				<DCC_READ 0x17902908 1 0>,
				<DCC_READ 0x17902C18 1 0>,
				<DCC_READ 0x17B90810 1 0>,
				<DCC_READ 0x17B90C50 1 0>,
				<DCC_READ 0x17B90814 1 0>,
				<DCC_READ 0x17B90C54 1 0>,
				<DCC_READ 0x17B90818 1 0>,
				<DCC_READ 0x17B90C58 1 0>,
				<DCC_READ 0x17B93A04 2 0>,
				<DCC_READ 0x17B94810 1 0>,
				<DCC_READ 0x17B94814 1 0>,
				<DCC_READ 0x17B94818 1 0>,
				<DCC_READ 0x17B97A04 1 0>,
				<DCC_READ 0x17BA0810 1 0>,
				<DCC_READ 0x17BA0C50 1 0>,
				<DCC_READ 0x17BA0814 1 0>,
				<DCC_READ 0x17BA0C54 1 0>,
				<DCC_READ 0x17BA0818 1 0>,
				<DCC_READ 0x17BA0C58 1 0>,
				<DCC_READ 0x17BA3A04 2 0>,
				<DCC_READ 0x17B93000 80 0>,
				<DCC_READ 0x17B97000 40 0>,
				<DCC_READ 0x17BA3000 80 0>,
				<DCC_READ 0x0C201244 1 0>,
				<DCC_READ 0x0C202244 1 0>,
				<DCC_READ 0x17B02000 1 0>,
				<DCC_READ 0x17B00000 1 0>,
				<DCC_READ 0x17A94030 1 0>,
				<DCC_READ 0x17A9408C 1 0>,
				<DCC_WRITE 0x17A9409C 0x78 0>,
				<DCC_WRITE 0x17A9409C 0x0 0>,
				<DCC_WRITE 0x17A94048 0x1 0>,
				<DCC_WRITE 0x17A94090 0x0 0>,
				<DCC_WRITE 0x17A94090 0x25 0>,
				<DCC_READ 0x17A94098 1 0>,
				<DCC_WRITE 0x17A94048 0x1D 0>,
				<DCC_WRITE 0x17A94090 0x0 0>,
				<DCC_WRITE 0x17A94090 0x25 0>,
				<DCC_READ 0x17A94098 1 0>,
				<DCC_READ 0x17A90030 1 0>,
				<DCC_READ 0x17A9008C 1 0>,
				<DCC_WRITE 0x17A9009C 0x78 0>,
				<DCC_WRITE 0x17A9009C 0x0 0>,
				<DCC_WRITE 0x17A90048 0x1 0>,
				<DCC_WRITE 0x17A90090 0x0 0>,
				<DCC_WRITE 0x17A90090 0x25 0>,
				<DCC_READ 0x17A90098 1 0>,
				<DCC_WRITE 0x17A90048 0x1D 0>,
				<DCC_WRITE 0x17A90090 0x0 0>,
				<DCC_WRITE 0x17A90090 0x25 0>,
				<DCC_READ 0x17A90098 1 0>,
				<DCC_READ 0x17A92030 1 0>,
				<DCC_READ 0x17A9208C 1 0>,
				<DCC_WRITE 0x17A9209C 0x78 0>,
				<DCC_WRITE 0x17A9209C 0x0 0>,
				<DCC_WRITE 0x17A92048 0x1 0>,
				<DCC_WRITE 0x17A92090 0x0 0>,
				<DCC_WRITE 0x17A92090 0x25 0>,
				<DCC_READ 0x17A92098 1 0>,
				<DCC_WRITE 0x17A92048 0x1D 0>,
				<DCC_WRITE 0x17A92090 0x0 0>,
				<DCC_WRITE 0x17A92090 0x25 0>,
				<DCC_READ 0x17A92098 1 0>,
				<DCC_READ 0x17A96030 1 0>,
				<DCC_READ 0x17A9608C 1 0>,
				<DCC_WRITE 0x17A9609C 0x78 0>,
				<DCC_WRITE 0x17A9609C 0x0 0>,
				<DCC_WRITE 0x17A96048 0x1 0>,
				<DCC_WRITE 0x17A96090 0x0 0>,
				<DCC_WRITE 0x17A96090 0x25 0>,
				<DCC_READ 0x17A96098 1 0>,
				<DCC_WRITE 0x17A96048 0x1D 0>,
				<DCC_WRITE 0x17A96090 0x0 0>,
				<DCC_WRITE 0x17A96090 0x25 0>,
				<DCC_READ 0x17A96098 1 0>,
				<DCC_READ 0x17D98024 1 0>,
				<DCC_READ 0x13822000 1 1>,
				<DCC_READ 0x221C20A4 1 0>,
				<DCC_READ 0x01FC8000 1 0>,
				<DCC_READ 0x17400038 1 0>,
				<DCC_READ 0x17D91020 1 0>,
				<DCC_READ 0x17D92020 1 0>,
				<DCC_READ 0x17D93020 1 0>,
				<DCC_READ 0x17D94020 1 0>,
				<DCC_READ 0x17D90020 1 0>,
				<DCC_READ 0x17D9134C 1 0>,
				<DCC_READ 0x17D9234C 1 0>,
				<DCC_READ 0x17D9334C 1 0>,
				<DCC_READ 0x17D9434C 1 0>,
				<DCC_READ 0x17D9034C 1 0>,
				<DCC_READ 0x17D91300 1 0>,
				<DCC_READ 0x17D92300 1 0>,
				<DCC_READ 0x17D93300 1 0>,
				<DCC_READ 0x17D94300 1 0>,
				<DCC_READ 0x17D90300 1 0>,
				<DCC_READ 0x24183040 1 0>,
				<DCC_READ 0x24183048 1 0>,
				<DCC_READ 0x24102010 1 0>,
				<DCC_READ 0x24102020 6 0>,
				<DCC_READ 0x24102410 1 0>,
				<DCC_READ 0x24102420 6 0>,
				<DCC_READ 0x24142010 1 0>,
				<DCC_READ 0x24142020 6 0>,
				<DCC_READ 0x24142410 1 0>,
				<DCC_READ 0x24142420 6 0>,
				<DCC_READ 0x24182010 1 0>,
				<DCC_READ 0x24182020 6 0>,
				<DCC_READ 0x24182410 1 0>,
				<DCC_READ 0x24182420 6 0>,
				<DCC_READ 0x24100810 1 0>,
				<DCC_READ 0x24100838 1 0>,
				<DCC_READ 0x24100830 2 0>,
				<DCC_READ 0x24100830 2 0>,
				<DCC_READ 0x24100830 2 0>,
				<DCC_READ 0x24100830 2 0>,
				<DCC_READ 0x24100838 1 0>,
				<DCC_READ 0x24100830 2 0>,
				<DCC_READ 0x24100830 2 0>,
				<DCC_READ 0x24100830 2 0>,
				<DCC_READ 0x24100830 2 0>,
				<DCC_READ 0x24100838 1 0>,
				<DCC_READ 0x24100830 2 0>,
				<DCC_READ 0x24100830 2 0>,
				<DCC_READ 0x24100830 2 0>,
				<DCC_READ 0x24100830 2 0>,
				<DCC_READ 0x24100838 1 0>,
				<DCC_READ 0x24100830 2 0>,
				<DCC_READ 0x24100830 2 0>,
				<DCC_READ 0x24100830 2 0>,
				<DCC_READ 0x24100830 2 0>,
				<DCC_READ 0x24100808 2 0>,
				<DCC_READ 0x24100C10 1 0>,
				<DCC_READ 0x24100C38 1 0>,
				<DCC_READ 0x24100C30 2 0>,
				<DCC_READ 0x24100C30 2 0>,
				<DCC_READ 0x24100C30 2 0>,
				<DCC_READ 0x24100C30 2 0>,
				<DCC_READ 0x24100C38 1 0>,
				<DCC_READ 0x24100C30 2 0>,
				<DCC_READ 0x24100C30 2 0>,
				<DCC_READ 0x24100C30 2 0>,
				<DCC_READ 0x24100C30 2 0>,
				<DCC_READ 0x24100C38 1 0>,
				<DCC_READ 0x24100C30 2 0>,
				<DCC_READ 0x24100C30 2 0>,
				<DCC_READ 0x24100C30 2 0>,
				<DCC_READ 0x24100C30 2 0>,
				<DCC_READ 0x24100C38 1 0>,
				<DCC_READ 0x24100C30 2 0>,
				<DCC_READ 0x24100C30 2 0>,
				<DCC_READ 0x24100C30 2 0>,
				<DCC_READ 0x24100C30 2 0>,
				<DCC_READ 0x24100C08 2 0>,
				<DCC_READ 0x24140810 1 0>,
				<DCC_READ 0x24140838 1 0>,
				<DCC_READ 0x24140830 2 0>,
				<DCC_READ 0x24140830 2 0>,
				<DCC_READ 0x24140830 2 0>,
				<DCC_READ 0x24140830 2 0>,
				<DCC_READ 0x24140838 1 0>,
				<DCC_READ 0x24140830 2 0>,
				<DCC_READ 0x24140830 2 0>,
				<DCC_READ 0x24140830 2 0>,
				<DCC_READ 0x24140830 2 0>,
				<DCC_READ 0x24140838 1 0>,
				<DCC_READ 0x24140830 2 0>,
				<DCC_READ 0x24140830 2 0>,
				<DCC_READ 0x24140830 2 0>,
				<DCC_READ 0x24140830 2 0>,
				<DCC_READ 0x24140838 1 0>,
				<DCC_READ 0x24140830 2 0>,
				<DCC_READ 0x24140830 2 0>,
				<DCC_READ 0x24140830 2 0>,
				<DCC_READ 0x24140830 2 0>,
				<DCC_READ 0x24140808 2 0>,
				<DCC_READ 0x24140C10 1 0>,
				<DCC_READ 0x24140C38 1 0>,
				<DCC_READ 0x24140C30 2 0>,
				<DCC_READ 0x24140C30 2 0>,
				<DCC_READ 0x24140C30 2 0>,
				<DCC_READ 0x24140C30 2 0>,
				<DCC_READ 0x24140C38 1 0>,
				<DCC_READ 0x24140C30 2 0>,
				<DCC_READ 0x24140C30 2 0>,
				<DCC_READ 0x24140C30 2 0>,
				<DCC_READ 0x24140C30 2 0>,
				<DCC_READ 0x24140C38 1 0>,
				<DCC_READ 0x24140C30 2 0>,
				<DCC_READ 0x24140C30 2 0>,
				<DCC_READ 0x24140C30 2 0>,
				<DCC_READ 0x24140C30 2 0>,
				<DCC_READ 0x24140C38 1 0>,
				<DCC_READ 0x24140C30 2 0>,
				<DCC_READ 0x24140C30 2 0>,
				<DCC_READ 0x24140C30 2 0>,
				<DCC_READ 0x24140C30 2 0>,
				<DCC_READ 0x24140C08 2 0>,
				<DCC_READ 0x24180010 1 0>,
				<DCC_READ 0x24180038 1 0>,
				<DCC_READ 0x24180030 2 0>,
				<DCC_READ 0x24180030 2 0>,
				<DCC_READ 0x24180030 2 0>,
				<DCC_READ 0x24180030 2 0>,
				<DCC_READ 0x24180038 1 0>,
				<DCC_READ 0x24180030 2 0>,
				<DCC_READ 0x24180030 2 0>,
				<DCC_READ 0x24180030 2 0>,
				<DCC_READ 0x24180030 2 0>,
				<DCC_READ 0x24180038 1 0>,
				<DCC_READ 0x24180030 2 0>,
				<DCC_READ 0x24180030 2 0>,
				<DCC_READ 0x24180030 2 0>,
				<DCC_READ 0x24180030 2 0>,
				<DCC_READ 0x24180038 1 0>,
				<DCC_READ 0x24180030 2 0>,
				<DCC_READ 0x24180030 2 0>,
				<DCC_READ 0x24180030 2 0>,
				<DCC_READ 0x24180030 2 0>,
				<DCC_READ 0x24180008 2 0>,
				<DCC_READ 0x24180410 1 0>,
				<DCC_READ 0x24180438 1 0>,
				<DCC_READ 0x24180430 2 0>,
				<DCC_READ 0x24180430 2 0>,
				<DCC_READ 0x24180430 2 0>,
				<DCC_READ 0x24180430 2 0>,
				<DCC_READ 0x24180438 1 0>,
				<DCC_READ 0x24180430 2 0>,
				<DCC_READ 0x24180430 2 0>,
				<DCC_READ 0x24180430 2 0>,
				<DCC_READ 0x24180430 2 0>,
				<DCC_READ 0x24180438 1 0>,
				<DCC_READ 0x24180430 2 0>,
				<DCC_READ 0x24180430 2 0>,
				<DCC_READ 0x24180430 2 0>,
				<DCC_READ 0x24180430 2 0>,
				<DCC_READ 0x24180438 1 0>,
				<DCC_READ 0x24180430 2 0>,
				<DCC_READ 0x24180430 2 0>,
				<DCC_READ 0x24180430 2 0>,
				<DCC_READ 0x24180430 2 0>,
				<DCC_READ 0x24180408 2 0>,
				<DCC_READ 0x24101018 1 0>,
				<DCC_READ 0x24101008 1 0>,
				<DCC_READ 0x24101010 2 0>,
				<DCC_READ 0x24101010 2 0>,
				<DCC_READ 0x24101010 2 0>,
				<DCC_READ 0x24101010 2 0>,
				<DCC_READ 0x24101098 1 0>,
				<DCC_READ 0x24101088 1 0>,
				<DCC_READ 0x24101090 2 0>,
				<DCC_READ 0x24101090 2 0>,
				<DCC_READ 0x24101090 2 0>,
				<DCC_READ 0x24101090 2 0>,
				<DCC_READ 0x24101090 2 0>,
				<DCC_READ 0x24141018 1 0>,
				<DCC_READ 0x24141008 1 0>,
				<DCC_READ 0x24141010 2 0>,
				<DCC_READ 0x24141010 2 0>,
				<DCC_READ 0x24141010 2 0>,
				<DCC_READ 0x24141010 2 0>,
				<DCC_READ 0x24141098 1 0>,
				<DCC_READ 0x24141088 1 0>,
				<DCC_READ 0x24141090 2 0>,
				<DCC_READ 0x24141090 2 0>,
				<DCC_READ 0x24141090 2 0>,
				<DCC_READ 0x24141090 2 0>,
				<DCC_READ 0x24141090 2 0>,
				<DCC_READ 0x24181018 1 0>,
				<DCC_READ 0x24181008 1 0>,
				<DCC_READ 0x24181010 2 0>,
				<DCC_READ 0x24181010 2 0>,
				<DCC_READ 0x24181010 2 0>,
				<DCC_READ 0x24181098 1 0>,
				<DCC_READ 0x24181088 1 0>,
				<DCC_READ 0x24181090 2 0>,
				<DCC_READ 0x24181090 2 0>,
				<DCC_READ 0x24181090 2 0>,
				<DCC_READ 0x24181090 2 0>,
				<DCC_READ 0x24181090 2 0>,
				<DCC_READ 0x24181090 2 0>,
				<DCC_READ 0x24181090 2 0>,
				<DCC_READ 0x24181090 2 0>,
				<DCC_READ 0x24181090 2 0>,
				<DCC_READ 0x24181090 2 0>,
				<DCC_READ 0x24181090 2 0>,
				<DCC_READ 0x24181090 2 0>,
				<DCC_READ 0x17800010 1 0>,
				<DCC_READ 0x17800024 1 0>,
				<DCC_READ 0x17800038 1 0>,
				<DCC_READ 0x1780003C 1 0>,
				<DCC_READ 0x17800040 1 0>,
				<DCC_READ 0x17800044 1 0>,
				<DCC_READ 0x17800048 1 0>,
				<DCC_READ 0x1780004C 1 0>,
				<DCC_READ 0x17800058 1 0>,
				<DCC_READ 0x1780005C 1 0>,
				<DCC_READ 0x17800060 1 0>,
				<DCC_READ 0x17800064 1 0>,
				<DCC_READ 0x1780006C 1 0>,
				<DCC_READ 0x178000F0 1 0>,
				<DCC_READ 0x178000F4 1 0>,
				<DCC_READ 0x17810010 1 0>,
				<DCC_READ 0x17810024 1 0>,
				<DCC_READ 0x17810038 1 0>,
				<DCC_READ 0x1781003C 1 0>,
				<DCC_READ 0x17810040 1 0>,
				<DCC_READ 0x17810044 1 0>,
				<DCC_READ 0x17810048 1 0>,
				<DCC_READ 0x1781004C 1 0>,
				<DCC_READ 0x17810058 1 0>,
				<DCC_READ 0x1781005C 1 0>,
				<DCC_READ 0x17810060 1 0>,
				<DCC_READ 0x17810064 1 0>,
				<DCC_READ 0x1781006C 1 0>,
				<DCC_READ 0x178100F0 1 0>,
				<DCC_READ 0x178100F4 1 0>,
				<DCC_READ 0x17820010 1 0>,
				<DCC_READ 0x17820024 1 0>,
				<DCC_READ 0x17820038 1 0>,
				<DCC_READ 0x1782003C 1 0>,
				<DCC_READ 0x17820040 1 0>,
				<DCC_READ 0x17820044 1 0>,
				<DCC_READ 0x17820048 1 0>,
				<DCC_READ 0x1782004C 1 0>,
				<DCC_READ 0x17820058 1 0>,
				<DCC_READ 0x1782005C 1 0>,
				<DCC_READ 0x17820060 1 0>,
				<DCC_READ 0x17820064 1 0>,
				<DCC_READ 0x178200F0 1 0>,
				<DCC_READ 0x178200F4 1 0>,
				<DCC_READ 0x17830010 1 0>,
				<DCC_READ 0x17830024 1 0>,
				<DCC_READ 0x17830038 1 0>,
				<DCC_READ 0x1783003C 1 0>,
				<DCC_READ 0x17830040 1 0>,
				<DCC_READ 0x17830044 1 0>,
				<DCC_READ 0x17830048 1 0>,
				<DCC_READ 0x1783004C 1 0>,
				<DCC_READ 0x17830058 1 0>,
				<DCC_READ 0x1783005C 1 0>,
				<DCC_READ 0x17830060 1 0>,
				<DCC_READ 0x17830064 1 0>,
				<DCC_READ 0x178300F0 1 0>,
				<DCC_READ 0x178300F4 1 0>,
				<DCC_READ 0x17840010 1 0>,
				<DCC_READ 0x17840024 1 0>,
				<DCC_READ 0x17840038 1 0>,
				<DCC_READ 0x1784003C 1 0>,
				<DCC_READ 0x17840040 1 0>,
				<DCC_READ 0x17840044 1 0>,
				<DCC_READ 0x17840048 1 0>,
				<DCC_READ 0x1784004C 1 0>,
				<DCC_READ 0x17840058 1 0>,
				<DCC_READ 0x1784005C 1 0>,
				<DCC_READ 0x17840060 1 0>,
				<DCC_READ 0x17840064 1 0>,
				<DCC_READ 0x178400F0 1 0>,
				<DCC_READ 0x178400F4 1 0>,
				<DCC_READ 0x17850010 1 0>,
				<DCC_READ 0x17850024 1 0>,
				<DCC_READ 0x17850038 1 0>,
				<DCC_READ 0x1785003C 1 0>,
				<DCC_READ 0x17850040 1 0>,
				<DCC_READ 0x17850044 1 0>,
				<DCC_READ 0x17850048 1 0>,
				<DCC_READ 0x1785004C 1 0>,
				<DCC_READ 0x17850058 1 0>,
				<DCC_READ 0x1785005C 1 0>,
				<DCC_READ 0x17850060 1 0>,
				<DCC_READ 0x17850064 1 0>,
				<DCC_READ 0x178500F0 1 0>,
				<DCC_READ 0x178500F4 1 0>,
				<DCC_READ 0x17860010 1 0>,
				<DCC_READ 0x17860024 1 0>,
				<DCC_READ 0x17860038 1 0>,
				<DCC_READ 0x1786003C 1 0>,
				<DCC_READ 0x17860040 1 0>,
				<DCC_READ 0x17860044 1 0>,
				<DCC_READ 0x17860048 1 0>,
				<DCC_READ 0x1786004C 1 0>,
				<DCC_READ 0x17860058 1 0>,
				<DCC_READ 0x1786005C 1 0>,
				<DCC_READ 0x17860060 1 0>,
				<DCC_READ 0x17860064 1 0>,
				<DCC_READ 0x178600F0 1 0>,
				<DCC_READ 0x178600F4 1 0>,
				<DCC_READ 0x17870010 1 0>,
				<DCC_READ 0x17870024 1 0>,
				<DCC_READ 0x17870038 1 0>,
				<DCC_READ 0x1787003C 1 0>,
				<DCC_READ 0x17870040 1 0>,
				<DCC_READ 0x17870044 1 0>,
				<DCC_READ 0x17870048 1 0>,
				<DCC_READ 0x1787004C 1 0>,
				<DCC_READ 0x17870058 1 0>,
				<DCC_READ 0x1787005C 1 0>,
				<DCC_READ 0x17870060 1 0>,
				<DCC_READ 0x17870064 1 0>,
				<DCC_READ 0x178700F0 1 0>,
				<DCC_READ 0x178700F4 1 0>,
				<DCC_READ 0x178A0010 1 0>,
				<DCC_READ 0x178A0024 1 0>,
				<DCC_READ 0x178A0038 1 0>,
				<DCC_READ 0x178A003C 1 0>,
				<DCC_READ 0x178A0040 1 0>,
				<DCC_READ 0x178A0044 1 0>,
				<DCC_READ 0x178A0048 1 0>,
				<DCC_READ 0x178A004C 1 0>,
				<DCC_READ 0x178A006C 1 0>,
				<DCC_READ 0x178A0070 1 0>,
				<DCC_READ 0x178A0074 1 0>,
				<DCC_READ 0x178A0078 1 0>,
				<DCC_READ 0x178A007C 1 0>,
				<DCC_READ 0x178A0084 1 0>,
				<DCC_READ 0x178A00F4 1 0>,
				<DCC_READ 0x178A00F8 1 0>,
				<DCC_READ 0x178A00FC 1 0>,
				<DCC_READ 0x178A0100 1 0>,
				<DCC_READ 0x178A0104 1 0>,
				<DCC_READ 0x178A0118 1 0>,
				<DCC_READ 0x178A011C 1 0>,
				<DCC_READ 0x178A0120 1 0>,
				<DCC_READ 0x178A0124 1 0>,
				<DCC_READ 0x178A0128 1 0>,
				<DCC_READ 0x178A012C 1 0>,
				<DCC_READ 0x178A0130 1 0>,
				<DCC_READ 0x178A0134 1 0>,
				<DCC_READ 0x178A0138 1 0>,
				<DCC_READ 0x178A0158 1 0>,
				<DCC_READ 0x178A015C 1 0>,
				<DCC_READ 0x178A0160 1 0>,
				<DCC_READ 0x178A0164 1 0>,
				<DCC_READ 0x178A0168 1 0>,
				<DCC_READ 0x178A0170 1 0>,
				<DCC_READ 0x178A0174 1 0>,
				<DCC_READ 0x178A0188 1 0>,
				<DCC_READ 0x178A018C 1 0>,
				<DCC_READ 0x178A0190 1 0>,
				<DCC_READ 0x178A0194 1 0>,
				<DCC_READ 0x178A0198 1 0>,
				<DCC_READ 0x178A01AC 1 0>,
				<DCC_READ 0x178A01B0 1 0>,
				<DCC_READ 0x178A01B4 1 0>,
				<DCC_READ 0x178A01B8 1 0>,
				<DCC_READ 0x178A01BC 1 0>,
				<DCC_READ 0x178A01C0 1 0>,
				<DCC_READ 0x178A01C8 1 0>,
				<DCC_READ 0x17880010 1 0>,
				<DCC_READ 0x17880024 1 0>,
				<DCC_READ 0x17880038 1 0>,
				<DCC_READ 0x1788003C 1 0>,
				<DCC_READ 0x17880040 1 0>,
				<DCC_READ 0x17880044 1 0>,
				<DCC_READ 0x17880048 1 0>,
				<DCC_READ 0x1788004C 1 0>,
				<DCC_READ 0x17890010 1 0>,
				<DCC_READ 0x17890024 1 0>,
				<DCC_READ 0x17890038 1 0>,
				<DCC_READ 0x1789003C 1 0>,
				<DCC_READ 0x17890040 1 0>,
				<DCC_READ 0x17890044 1 0>,
				<DCC_READ 0x17890048 1 0>,
				<DCC_READ 0x1789004C 1 0>,
				<DCC_READ 0x178A0290 1 0>,
				<DCC_READ 0x178A0204 1 0>,
				<DCC_READ 0x178A0244 1 0>,
				<DCC_READ 0x17E30000 1 0>,
				<DCC_READ 0x17E30008 1 0>,
				<DCC_READ 0x17E30010 1 0>,
				<DCC_READ 0x17E80000 1 0>,
				<DCC_READ 0x17E80008 1 0>,
				<DCC_READ 0x17E80010 1 0>,
				<DCC_READ 0x17F80000 1 0>,
				<DCC_READ 0x17F80008 1 0>,
				<DCC_READ 0x17F80010 1 0>,
				<DCC_READ 0x18080000 1 0>,
				<DCC_READ 0x18080008 1 0>,
				<DCC_READ 0x18080010 1 0>,
				<DCC_READ 0x18180000 1 0>,
				<DCC_READ 0x18180008 1 0>,
				<DCC_READ 0x18180010 1 0>,
				<DCC_READ 0x18280000 1 0>,
				<DCC_READ 0x18280008 1 0>,
				<DCC_READ 0x18280010 1 0>,
				<DCC_READ 0x18380000 1 0>,
				<DCC_READ 0x18380008 1 0>,
				<DCC_READ 0x18380010 1 0>,
				<DCC_READ 0x18480000 1 0>,
				<DCC_READ 0x18480008 1 0>,
				<DCC_READ 0x18480010 1 0>,
				<DCC_READ 0x18580000 1 0>,
				<DCC_READ 0x18580008 1 0>,
				<DCC_READ 0x18580010 1 0>,
				<DCC_READ 0x2407701c 1 0>,
				<DCC_READ 0x24077030 1 0>,
				<DCC_READ 0x2408005c 1 0>,
				<DCC_READ 0x240800c8 1 0>,
				<DCC_READ 0x240800d4 1 0>,
				<DCC_READ 0x240800e0 1 0>,
				<DCC_READ 0x240800ec 1 0>,
				<DCC_READ 0x240800f8 1 0>,
				<DCC_READ 0x240801b4 1 0>,
				<DCC_READ 0x240a8120 1 0>,
				<DCC_READ 0x240a8124 1 0>,
				<DCC_READ 0x240a8128 1 0>,
				<DCC_READ 0x240a812c 1 0>,
				<DCC_READ 0x240a8130 1 0>,
				<DCC_READ 0x240a8144 1 0>,
				<DCC_READ 0x240a8148 1 0>,
				<DCC_READ 0x240a81d0 1 0>,
				<DCC_READ 0x240a81d4 1 0>,
				<DCC_READ 0x240a81d8 1 0>,
				<DCC_READ 0x240a81dc 1 0>,
				<DCC_READ 0x240a81f0 1 0>,
				<DCC_READ 0x240a81fc 1 0>,
				<DCC_READ 0x240a8208 1 0>,
				<DCC_READ 0x240a8214 1 0>,
				<DCC_READ 0x240a8264 1 0>,
				<DCC_READ 0x240a8284 1 0>,
				<DCC_READ 0x240a82fc 1 0>,
				<DCC_READ 0x240a8860 1 0>,
				<DCC_READ 0x240a8864 1 0>,
				<DCC_READ 0x240a8868 1 0>,
				<DCC_READ 0x240ba28c 1 0>,
				<DCC_READ 0x240ba294 1 0>,
				<DCC_READ 0x240ba29c 1 0>,
				<DCC_READ 0x24185100 1 0>,
				<DCC_READ 0x24185104 1 0>,
				<DCC_READ 0x24185108 1 0>,
				<DCC_READ 0x2418510c 1 0>,
				<DCC_READ 0x24187100 1 0>,
				<DCC_READ 0x2418c100 1 0>,
				<DCC_READ 0x24401e64 1 0>,
				<DCC_READ 0x24401ea0 1 0>,
				<DCC_READ 0x24403e64 1 0>,
				<DCC_READ 0x24403ea0 1 0>,
				<DCC_READ 0x2440527c 1 0>,
				<DCC_READ 0x24405290 1 0>,
				<DCC_READ 0x244054ec 1 0>,
				<DCC_READ 0x244054f4 1 0>,
				<DCC_READ 0x24405514 1 0>,
				<DCC_READ 0x2440551c 1 0>,
				<DCC_READ 0x24405524 1 0>,
				<DCC_READ 0x24405548 1 0>,
				<DCC_READ 0x24405550 1 0>,
				<DCC_READ 0x24405558 1 0>,
				<DCC_READ 0x244055b8 1 0>,
				<DCC_READ 0x244055c0 1 0>,
				<DCC_READ 0x244055ec 1 0>,
				<DCC_READ 0x24405870 1 0>,
				<DCC_READ 0x244058a0 1 0>,
				<DCC_READ 0x244058a8 1 0>,
				<DCC_READ 0x244058b0 1 0>,
				<DCC_READ 0x244058b8 1 0>,
				<DCC_READ 0x244058d8 1 0>,
				<DCC_READ 0x244058dc 1 0>,
				<DCC_READ 0x244058f4 1 0>,
				<DCC_READ 0x244058fc 1 0>,
				<DCC_READ 0x24405920 1 0>,
				<DCC_READ 0x24405928 1 0>,
				<DCC_READ 0x24405944 1 0>,
				<DCC_READ 0x24406604 1 0>,
				<DCC_READ 0x2440660c 1 0>,
				<DCC_READ 0x24440310 1 0>,
				<DCC_READ 0x24440400 1 0>,
				<DCC_READ 0x24440404 1 0>,
				<DCC_READ 0x24440410 1 0>,
				<DCC_READ 0x24440414 1 0>,
				<DCC_READ 0x24440418 1 0>,
				<DCC_READ 0x24440428 1 0>,
				<DCC_READ 0x24440430 1 0>,
				<DCC_READ 0x24440440 1 0>,
				<DCC_READ 0x24440448 1 0>,
				<DCC_READ 0x244404a0 1 0>,
				<DCC_READ 0x244404b0 1 0>,
				<DCC_READ 0x244404b4 1 0>,
				<DCC_READ 0x244404b8 1 0>,
				<DCC_READ 0x244404d0 1 0>,
				<DCC_READ 0x244404d4 1 0>,
				<DCC_READ 0x2444341c 1 0>,
				<DCC_READ 0x24445804 1 0>,
				<DCC_READ 0x2444590c 1 0>,
				<DCC_READ 0x24445a14 1 0>,
				<DCC_READ 0x24445c1c 1 0>,
				<DCC_READ 0x24445c38 1 0>,
				<DCC_READ 0x24449100 1 0>,
				<DCC_READ 0x24449110 1 0>,
				<DCC_READ 0x24449120 1 0>,
				<DCC_READ 0x24449180 1 0>,
				<DCC_READ 0x24449184 1 0>,
				<DCC_READ 0x24460618 1 0>,
				<DCC_READ 0x24460684 1 0>,
				<DCC_READ 0x2446068c 1 0>,
				<DCC_READ 0x24481e64 1 0>,
				<DCC_READ 0x24481ea0 1 0>,
				<DCC_READ 0x24483e64 1 0>,
				<DCC_READ 0x24483ea0 1 0>,
				<DCC_READ 0x2448527c 1 0>,
				<DCC_READ 0x24485290 1 0>,
				<DCC_READ 0x244854ec 1 0>,
				<DCC_READ 0x244854f4 1 0>,
				<DCC_READ 0x24485514 1 0>,
				<DCC_READ 0x2448551c 1 0>,
				<DCC_READ 0x24485524 1 0>,
				<DCC_READ 0x24485548 1 0>,
				<DCC_READ 0x24485550 1 0>,
				<DCC_READ 0x24485558 1 0>,
				<DCC_READ 0x244855b8 1 0>,
				<DCC_READ 0x244855c0 1 0>,
				<DCC_READ 0x244855ec 1 0>,
				<DCC_READ 0x24485870 1 0>,
				<DCC_READ 0x244858a0 1 0>,
				<DCC_READ 0x244858a8 1 0>,
				<DCC_READ 0x244858b0 1 0>,
				<DCC_READ 0x244858b8 1 0>,
				<DCC_READ 0x244858d8 1 0>,
				<DCC_READ 0x244858dc 1 0>,
				<DCC_READ 0x244858f4 1 0>,
				<DCC_READ 0x244858fc 1 0>,
				<DCC_READ 0x24485920 1 0>,
				<DCC_READ 0x24485928 1 0>,
				<DCC_READ 0x24485944 1 0>,
				<DCC_READ 0x24486604 1 0>,
				<DCC_READ 0x2448660c 1 0>,
				<DCC_READ 0x244c0310 1 0>,
				<DCC_READ 0x244c0400 1 0>,
				<DCC_READ 0x244c0404 1 0>,
				<DCC_READ 0x244c0410 1 0>,
				<DCC_READ 0x244c0414 1 0>,
				<DCC_READ 0x244c0418 1 0>,
				<DCC_READ 0x244c0428 1 0>,
				<DCC_READ 0x244c0430 1 0>,
				<DCC_READ 0x244c0440 1 0>,
				<DCC_READ 0x244c0448 1 0>,
				<DCC_READ 0x244c04a0 1 0>,
				<DCC_READ 0x244c04b0 1 0>,
				<DCC_READ 0x244c04b4 1 0>,
				<DCC_READ 0x244c04b8 1 0>,
				<DCC_READ 0x244c04d0 1 0>,
				<DCC_READ 0x244c04d4 1 0>,
				<DCC_READ 0x244c341c 1 0>,
				<DCC_READ 0x244c5804 1 0>,
				<DCC_READ 0x244c590c 1 0>,
				<DCC_READ 0x244c5a14 1 0>,
				<DCC_READ 0x244c5c1c 1 0>,
				<DCC_READ 0x244c5c38 1 0>,
				<DCC_READ 0x244c9100 1 0>,
				<DCC_READ 0x244c9110 1 0>,
				<DCC_READ 0x244c9120 1 0>,
				<DCC_READ 0x244c9180 1 0>,
				<DCC_READ 0x244c9184 1 0>,
				<DCC_READ 0x244e0618 1 0>,
				<DCC_READ 0x244e0684 1 0>,
				<DCC_READ 0x244e068c 1 0>,
				<DCC_READ 0x24601e64 1 0>,
				<DCC_READ 0x24601ea0 1 0>,
				<DCC_READ 0x24603e64 1 0>,
				<DCC_READ 0x24603ea0 1 0>,
				<DCC_READ 0x2460527c 1 0>,
				<DCC_READ 0x24605290 1 0>,
				<DCC_READ 0x246054ec 1 0>,
				<DCC_READ 0x246054f4 1 0>,
				<DCC_READ 0x24605514 1 0>,
				<DCC_READ 0x2460551c 1 0>,
				<DCC_READ 0x24605524 1 0>,
				<DCC_READ 0x24605548 1 0>,
				<DCC_READ 0x24605550 1 0>,
				<DCC_READ 0x24605558 1 0>,
				<DCC_READ 0x246055b8 1 0>,
				<DCC_READ 0x246055c0 1 0>,
				<DCC_READ 0x246055ec 1 0>,
				<DCC_READ 0x24605870 1 0>,
				<DCC_READ 0x246058a0 1 0>,
				<DCC_READ 0x246058a8 1 0>,
				<DCC_READ 0x246058b0 1 0>,
				<DCC_READ 0x246058b8 1 0>,
				<DCC_READ 0x246058d8 1 0>,
				<DCC_READ 0x246058dc 1 0>,
				<DCC_READ 0x246058f4 1 0>,
				<DCC_READ 0x246058fc 1 0>,
				<DCC_READ 0x24605920 1 0>,
				<DCC_READ 0x24605928 1 0>,
				<DCC_READ 0x24605944 1 0>,
				<DCC_READ 0x24606604 1 0>,
				<DCC_READ 0x2460660c 1 0>,
				<DCC_READ 0x24640310 1 0>,
				<DCC_READ 0x24640400 1 0>,
				<DCC_READ 0x24640404 1 0>,
				<DCC_READ 0x24640410 1 0>,
				<DCC_READ 0x24640414 1 0>,
				<DCC_READ 0x24640418 1 0>,
				<DCC_READ 0x24640428 1 0>,
				<DCC_READ 0x24640430 1 0>,
				<DCC_READ 0x24640440 1 0>,
				<DCC_READ 0x24640448 1 0>,
				<DCC_READ 0x246404a0 1 0>,
				<DCC_READ 0x246404b0 1 0>,
				<DCC_READ 0x246404b4 1 0>,
				<DCC_READ 0x246404b8 1 0>,
				<DCC_READ 0x246404d0 1 0>,
				<DCC_READ 0x246404d4 1 0>,
				<DCC_READ 0x2464341c 1 0>,
				<DCC_READ 0x24645804 1 0>,
				<DCC_READ 0x2464590c 1 0>,
				<DCC_READ 0x24645a14 1 0>,
				<DCC_READ 0x24645c1c 1 0>,
				<DCC_READ 0x24645c38 1 0>,
				<DCC_READ 0x24649100 1 0>,
				<DCC_READ 0x24649110 1 0>,
				<DCC_READ 0x24649120 1 0>,
				<DCC_READ 0x24649180 1 0>,
				<DCC_READ 0x24649184 1 0>,
				<DCC_READ 0x24660618 1 0>,
				<DCC_READ 0x24660684 1 0>,
				<DCC_READ 0x2466068c 1 0>,
				<DCC_READ 0x24681e64 1 0>,
				<DCC_READ 0x24681ea0 1 0>,
				<DCC_READ 0x24683e64 1 0>,
				<DCC_READ 0x24683ea0 1 0>,
				<DCC_READ 0x2468527c 1 0>,
				<DCC_READ 0x24685290 1 0>,
				<DCC_READ 0x246854ec 1 0>,
				<DCC_READ 0x246854f4 1 0>,
				<DCC_READ 0x24685514 1 0>,
				<DCC_READ 0x2468551c 1 0>,
				<DCC_READ 0x24685524 1 0>,
				<DCC_READ 0x24685548 1 0>,
				<DCC_READ 0x24685550 1 0>,
				<DCC_READ 0x24685558 1 0>,
				<DCC_READ 0x246855b8 1 0>,
				<DCC_READ 0x246855c0 1 0>,
				<DCC_READ 0x246855ec 1 0>,
				<DCC_READ 0x24685870 1 0>,
				<DCC_READ 0x246858a0 1 0>,
				<DCC_READ 0x246858a8 1 0>,
				<DCC_READ 0x246858b0 1 0>,
				<DCC_READ 0x246858b8 1 0>,
				<DCC_READ 0x246858d8 1 0>,
				<DCC_READ 0x246858dc 1 0>,
				<DCC_READ 0x246858f4 1 0>,
				<DCC_READ 0x246858fc 1 0>,
				<DCC_READ 0x24685920 1 0>,
				<DCC_READ 0x24685928 1 0>,
				<DCC_READ 0x24685944 1 0>,
				<DCC_READ 0x24686604 1 0>,
				<DCC_READ 0x2468660c 1 0>,
				<DCC_READ 0x246c0310 1 0>,
				<DCC_READ 0x246c0400 1 0>,
				<DCC_READ 0x246c0404 1 0>,
				<DCC_READ 0x246c0410 1 0>,
				<DCC_READ 0x246c0414 1 0>,
				<DCC_READ 0x246c0418 1 0>,
				<DCC_READ 0x246c0428 1 0>,
				<DCC_READ 0x246c0430 1 0>,
				<DCC_READ 0x246c0440 1 0>,
				<DCC_READ 0x246c0448 1 0>,
				<DCC_READ 0x246c04a0 1 0>,
				<DCC_READ 0x246c04b0 1 0>,
				<DCC_READ 0x246c04b4 1 0>,
				<DCC_READ 0x246c04b8 1 0>,
				<DCC_READ 0x246c04d0 1 0>,
				<DCC_READ 0x246c04d4 1 0>,
				<DCC_READ 0x246c341c 1 0>,
				<DCC_READ 0x246c5804 1 0>,
				<DCC_READ 0x246c590c 1 0>,
				<DCC_READ 0x246c5a14 1 0>,
				<DCC_READ 0x246c5c1c 1 0>,
				<DCC_READ 0x246c5c38 1 0>,
				<DCC_READ 0x246c9100 1 0>,
				<DCC_READ 0x246c9110 1 0>,
				<DCC_READ 0x246c9120 1 0>,
				<DCC_READ 0x246c9180 1 0>,
				<DCC_READ 0x246c9184 1 0>,
				<DCC_READ 0x246e0618 1 0>,
				<DCC_READ 0x246e0684 1 0>,
				<DCC_READ 0x246e068c 1 0>,
				<DCC_READ 0x24840310 1 0>,
				<DCC_READ 0x24840400 1 0>,
				<DCC_READ 0x24840404 1 0>,
				<DCC_READ 0x24840410 1 0>,
				<DCC_READ 0x24840414 1 0>,
				<DCC_READ 0x24840418 1 0>,
				<DCC_READ 0x24840428 1 0>,
				<DCC_READ 0x24840430 1 0>,
				<DCC_READ 0x24840440 1 0>,
				<DCC_READ 0x24840448 1 0>,
				<DCC_READ 0x248404a0 1 0>,
				<DCC_READ 0x248404b0 1 0>,
				<DCC_READ 0x248404b4 1 0>,
				<DCC_READ 0x248404b8 1 0>,
				<DCC_READ 0x248404d0 1 0>,
				<DCC_READ 0x248404d4 1 0>,
				<DCC_READ 0x2484341c 1 0>,
				<DCC_READ 0x24845804 1 0>,
				<DCC_READ 0x2484590c 1 0>,
				<DCC_READ 0x24845a14 1 0>,
				<DCC_READ 0x24845c1c 1 0>,
				<DCC_READ 0x24845c38 1 0>,
				<DCC_READ 0x24849100 1 0>,
				<DCC_READ 0x24849110 1 0>,
				<DCC_READ 0x24849120 1 0>,
				<DCC_READ 0x24849180 1 0>,
				<DCC_READ 0x24849184 1 0>,
				<DCC_READ 0x24860618 1 0>,
				<DCC_READ 0x24860684 1 0>,
				<DCC_READ 0x2486068c 1 0>,
				<DCC_READ 0x248c0310 1 0>,
				<DCC_READ 0x248c0400 1 0>,
				<DCC_READ 0x248c0404 1 0>,
				<DCC_READ 0x248c0410 1 0>,
				<DCC_READ 0x248c0414 1 0>,
				<DCC_READ 0x248c0418 1 0>,
				<DCC_READ 0x248c0428 1 0>,
				<DCC_READ 0x248c0430 1 0>,
				<DCC_READ 0x248c0440 1 0>,
				<DCC_READ 0x248c0448 1 0>,
				<DCC_READ 0x248c04a0 1 0>,
				<DCC_READ 0x248c04b0 1 0>,
				<DCC_READ 0x248c04b4 1 0>,
				<DCC_READ 0x248c04b8 1 0>,
				<DCC_READ 0x248c04d0 1 0>,
				<DCC_READ 0x248c04d4 1 0>,
				<DCC_READ 0x248c341c 1 0>,
				<DCC_READ 0x248c5804 1 0>,
				<DCC_READ 0x248c590c 1 0>,
				<DCC_READ 0x248c5a14 1 0>,
				<DCC_READ 0x248c5c1c 1 0>,
				<DCC_READ 0x248c5c38 1 0>,
				<DCC_READ 0x248c9100 1 0>,
				<DCC_READ 0x248c9110 1 0>,
				<DCC_READ 0x248c9120 1 0>,
				<DCC_READ 0x248c9180 1 0>,
				<DCC_READ 0x248c9184 1 0>,
				<DCC_READ 0x248e0618 1 0>,
				<DCC_READ 0x248e0684 1 0>,
				<DCC_READ 0x248e068c 1 0>,
				<DCC_READ 0x25020348 1 0>,
				<DCC_READ 0x25020480 1 0>,
				<DCC_READ 0x25022400 1 0>,
				<DCC_READ 0x25023220 1 0>,
				<DCC_READ 0x25023224 1 0>,
				<DCC_READ 0x25023228 1 0>,
				<DCC_READ 0x2502322c 1 0>,
				<DCC_READ 0x25023258 1 0>,
				<DCC_READ 0x2502325c 1 0>,
				<DCC_READ 0x25023308 1 0>,
				<DCC_READ 0x25023318 1 0>,
				<DCC_READ 0x25038100 1 0>,
				<DCC_READ 0x2503c030 1 0>,
				<DCC_READ 0x25042044 1 0>,
				<DCC_READ 0x25042048 1 0>,
				<DCC_READ 0x2504204c 1 0>,
				<DCC_READ 0x250420b0 1 0>,
				<DCC_READ 0x25042104 1 0>,
				<DCC_READ 0x25042114 1 0>,
				<DCC_READ 0x25048004 1 0>,
				<DCC_READ 0x25048008 1 0>,
				<DCC_READ 0x2504800c 1 0>,
				<DCC_READ 0x25048010 1 0>,
				<DCC_READ 0x25048014 1 0>,
				<DCC_READ 0x2504c030 1 0>,
				<DCC_READ 0x25050020 1 0>,
				<DCC_READ 0x2506004c 1 0>,
				<DCC_READ 0x25060050 1 0>,
				<DCC_READ 0x25060054 1 0>,
				<DCC_READ 0x25060058 1 0>,
				<DCC_READ 0x2506005c 1 0>,
				<DCC_READ 0x25060060 1 0>,
				<DCC_READ 0x25060064 1 0>,
				<DCC_READ 0x25060068 1 0>,
				<DCC_READ 0x25220348 1 0>,
				<DCC_READ 0x25220480 1 0>,
				<DCC_READ 0x25222400 1 0>,
				<DCC_READ 0x25223220 1 0>,
				<DCC_READ 0x25223224 1 0>,
				<DCC_READ 0x25223228 1 0>,
				<DCC_READ 0x2522322c 1 0>,
				<DCC_READ 0x25223258 1 0>,
				<DCC_READ 0x2522325c 1 0>,
				<DCC_READ 0x25223308 1 0>,
				<DCC_READ 0x25223318 1 0>,
				<DCC_READ 0x25238100 1 0>,
				<DCC_READ 0x2523c030 1 0>,
				<DCC_READ 0x25242044 1 0>,
				<DCC_READ 0x25242048 1 0>,
				<DCC_READ 0x2524204c 1 0>,
				<DCC_READ 0x252420b0 1 0>,
				<DCC_READ 0x25242104 1 0>,
				<DCC_READ 0x25242114 1 0>,
				<DCC_READ 0x25248004 1 0>,
				<DCC_READ 0x25248008 1 0>,
				<DCC_READ 0x2524800c 1 0>,
				<DCC_READ 0x25248010 1 0>,
				<DCC_READ 0x25248014 1 0>,
				<DCC_READ 0x2524c030 1 0>,
				<DCC_READ 0x25250020 1 0>,
				<DCC_READ 0x2526004c 1 0>,
				<DCC_READ 0x25260050 1 0>,
				<DCC_READ 0x25260054 1 0>,
				<DCC_READ 0x25260058 1 0>,
				<DCC_READ 0x2526005c 1 0>,
				<DCC_READ 0x25260060 1 0>,
				<DCC_READ 0x25260064 1 0>,
				<DCC_READ 0x25260068 1 0>,
				<DCC_READ 0x25420348 1 0>,
				<DCC_READ 0x25420480 1 0>,
				<DCC_READ 0x25422400 1 0>,
				<DCC_READ 0x25423220 1 0>,
				<DCC_READ 0x25423224 1 0>,
				<DCC_READ 0x25423228 1 0>,
				<DCC_READ 0x2542322c 1 0>,
				<DCC_READ 0x25423258 1 0>,
				<DCC_READ 0x2542325c 1 0>,
				<DCC_READ 0x25423308 1 0>,
				<DCC_READ 0x25423318 1 0>,
				<DCC_READ 0x25438100 1 0>,
				<DCC_READ 0x2543c030 1 0>,
				<DCC_READ 0x25442044 1 0>,
				<DCC_READ 0x25442048 1 0>,
				<DCC_READ 0x2544204c 1 0>,
				<DCC_READ 0x254420b0 1 0>,
				<DCC_READ 0x25442104 1 0>,
				<DCC_READ 0x25442114 1 0>,
				<DCC_READ 0x25448004 1 0>,
				<DCC_READ 0x25448008 1 0>,
				<DCC_READ 0x2544800c 1 0>,
				<DCC_READ 0x25448010 1 0>,
				<DCC_READ 0x25448014 1 0>,
				<DCC_READ 0x2544c030 1 0>,
				<DCC_READ 0x25450020 1 0>,
				<DCC_READ 0x2546004c 1 0>,
				<DCC_READ 0x25460050 1 0>,
				<DCC_READ 0x25460054 1 0>,
				<DCC_READ 0x25460058 1 0>,
				<DCC_READ 0x2546005c 1 0>,
				<DCC_READ 0x25460060 1 0>,
				<DCC_READ 0x25460064 1 0>,
				<DCC_READ 0x25460068 1 0>,
				<DCC_READ 0x25620348 1 0>,
				<DCC_READ 0x25620480 1 0>,
				<DCC_READ 0x25622400 1 0>,
				<DCC_READ 0x25623220 1 0>,
				<DCC_READ 0x25623224 1 0>,
				<DCC_READ 0x25623228 1 0>,
				<DCC_READ 0x2562322c 1 0>,
				<DCC_READ 0x25623258 1 0>,
				<DCC_READ 0x2562325c 1 0>,
				<DCC_READ 0x25623308 1 0>,
				<DCC_READ 0x25623318 1 0>,
				<DCC_READ 0x25638100 1 0>,
				<DCC_READ 0x2563c030 1 0>,
				<DCC_READ 0x25642044 1 0>,
				<DCC_READ 0x25642048 1 0>,
				<DCC_READ 0x2564204c 1 0>,
				<DCC_READ 0x256420b0 1 0>,
				<DCC_READ 0x25642104 1 0>,
				<DCC_READ 0x25642114 1 0>,
				<DCC_READ 0x25648004 1 0>,
				<DCC_READ 0x25648008 1 0>,
				<DCC_READ 0x2564800c 1 0>,
				<DCC_READ 0x25648010 1 0>,
				<DCC_READ 0x25648014 1 0>,
				<DCC_READ 0x2564c030 1 0>,
				<DCC_READ 0x25650020 1 0>,
				<DCC_READ 0x2566004c 1 0>,
				<DCC_READ 0x25660050 1 0>,
				<DCC_READ 0x25660054 1 0>,
				<DCC_READ 0x25660058 1 0>,
				<DCC_READ 0x2566005c 1 0>,
				<DCC_READ 0x25660060 1 0>,
				<DCC_READ 0x25660064 1 0>,
				<DCC_READ 0x25660068 1 0>,
				<DCC_READ 0x25820348 1 0>,
				<DCC_READ 0x25820480 1 0>,
				<DCC_READ 0x25822400 1 0>,
				<DCC_READ 0x25823220 1 0>,
				<DCC_READ 0x25823224 1 0>,
				<DCC_READ 0x25823228 1 0>,
				<DCC_READ 0x2582322c 1 0>,
				<DCC_READ 0x25823258 1 0>,
				<DCC_READ 0x2582325c 1 0>,
				<DCC_READ 0x25823308 1 0>,
				<DCC_READ 0x25823318 1 0>,
				<DCC_READ 0x25838100 1 0>,
				<DCC_READ 0x2583c030 1 0>,
				<DCC_READ 0x25842044 1 0>,
				<DCC_READ 0x25842048 1 0>,
				<DCC_READ 0x2584204c 1 0>,
				<DCC_READ 0x258420b0 1 0>,
				<DCC_READ 0x25842104 1 0>,
				<DCC_READ 0x25842114 1 0>,
				<DCC_READ 0x25848004 1 0>,
				<DCC_READ 0x25848008 1 0>,
				<DCC_READ 0x2584800c 1 0>,
				<DCC_READ 0x25848010 1 0>,
				<DCC_READ 0x25848014 1 0>,
				<DCC_READ 0x2584c030 1 0>,
				<DCC_READ 0x25850020 1 0>,
				<DCC_READ 0x2586004c 1 0>,
				<DCC_READ 0x25860050 1 0>,
				<DCC_READ 0x25860054 1 0>,
				<DCC_READ 0x25860058 1 0>,
				<DCC_READ 0x2586005c 1 0>,
				<DCC_READ 0x25860060 1 0>,
				<DCC_READ 0x25860064 1 0>,
				<DCC_READ 0x25860068 1 0>,
				<DCC_READ 0x25a20348 1 0>,
				<DCC_READ 0x25a20480 1 0>,
				<DCC_READ 0x25a22400 1 0>,
				<DCC_READ 0x25a23220 1 0>,
				<DCC_READ 0x25a23224 1 0>,
				<DCC_READ 0x25a23228 1 0>,
				<DCC_READ 0x25a2322c 1 0>,
				<DCC_READ 0x25a23258 1 0>,
				<DCC_READ 0x25a2325c 1 0>,
				<DCC_READ 0x25a23308 1 0>,
				<DCC_READ 0x25a23318 1 0>,
				<DCC_READ 0x25a38100 1 0>,
				<DCC_READ 0x25a3c030 1 0>,
				<DCC_READ 0x25a42044 1 0>,
				<DCC_READ 0x25a42048 1 0>,
				<DCC_READ 0x25a4204c 1 0>,
				<DCC_READ 0x25a420b0 1 0>,
				<DCC_READ 0x25a42104 1 0>,
				<DCC_READ 0x25a42114 1 0>,
				<DCC_READ 0x25a48004 1 0>,
				<DCC_READ 0x25a48008 1 0>,
				<DCC_READ 0x25a4800c 1 0>,
				<DCC_READ 0x25a48010 1 0>,
				<DCC_READ 0x25a48014 1 0>,
				<DCC_READ 0x25a4c030 1 0>,
				<DCC_READ 0x25a50020 1 0>,
				<DCC_READ 0x25a6004c 1 0>,
				<DCC_READ 0x25a60050 1 0>,
				<DCC_READ 0x25a60054 1 0>,
				<DCC_READ 0x25a60058 1 0>,
				<DCC_READ 0x25a6005c 1 0>,
				<DCC_READ 0x25a60060 1 0>,
				<DCC_READ 0x25a60064 1 0>,
				<DCC_READ 0x25a60068 1 0>,
				<DCC_READ 0x25a01004 1 0>,
				<DCC_READ 0x25a00004 1 0>,
				<DCC_READ 0x25a03004 1 0>,
				<DCC_READ 0x25a04004 1 0>,
				<DCC_READ 0x25a02004 1 0>,
				<DCC_READ 0x25a05004 1 0>,
				<DCC_READ 0x25a06004 1 0>,
				<DCC_READ 0x25a07004 1 0>,
				<DCC_READ 0x25a08004 1 0>,
				<DCC_READ 0x25a09004 1 0>,
				<DCC_READ 0x25a0a004 1 0>,
				<DCC_READ 0x25a0b004 1 0>,
				<DCC_READ 0x25a0c004 1 0>,
				<DCC_READ 0x25a0d004 1 0>,
				<DCC_READ 0x25a0e004 1 0>,
				<DCC_READ 0x25a0f004 1 0>,
				<DCC_READ 0x25a10004 1 0>,
				<DCC_READ 0x25a11004 1 0>,
				<DCC_READ 0x25a12004 1 0>,
				<DCC_READ 0x25a13004 1 0>,
				<DCC_READ 0x25a14004 1 0>,
				<DCC_READ 0x25a15004 1 0>,
				<DCC_READ 0x25a16004 1 0>,
				<DCC_READ 0x25a17004 1 0>,
				<DCC_READ 0x25a18004 1 0>,
				<DCC_READ 0x25a19004 1 0>,
				<DCC_READ 0x25a1a004 1 0>,
				<DCC_READ 0x25a1b004 1 0>,
				<DCC_READ 0x25a1c004 1 0>,
				<DCC_READ 0x25a1d004 1 0>,
				<DCC_READ 0x25a1e004 1 0>,
				<DCC_READ 0x25a1f004 1 0>,
				<DCC_READ 0x25001004 1 0>,
				<DCC_READ 0x25000004 1 0>,
				<DCC_READ 0x25003004 1 0>,
				<DCC_READ 0x25004004 1 0>,
				<DCC_READ 0x25002004 1 0>,
				<DCC_READ 0x25005004 1 0>,
				<DCC_READ 0x25006004 1 0>,
				<DCC_READ 0x25007004 1 0>,
				<DCC_READ 0x25008004 1 0>,
				<DCC_READ 0x25009004 1 0>,
				<DCC_READ 0x2500a004 1 0>,
				<DCC_READ 0x2500b004 1 0>,
				<DCC_READ 0x2500c004 1 0>,
				<DCC_READ 0x2500d004 1 0>,
				<DCC_READ 0x2500e004 1 0>,
				<DCC_READ 0x2500f004 1 0>,
				<DCC_READ 0x25010004 1 0>,
				<DCC_READ 0x25011004 1 0>,
				<DCC_READ 0x25012004 1 0>,
				<DCC_READ 0x25013004 1 0>,
				<DCC_READ 0x25014004 1 0>,
				<DCC_READ 0x25015004 1 0>,
				<DCC_READ 0x25016004 1 0>,
				<DCC_READ 0x25017004 1 0>,
				<DCC_READ 0x25018004 1 0>,
				<DCC_READ 0x25019004 1 0>,
				<DCC_READ 0x2501a004 1 0>,
				<DCC_READ 0x2501b004 1 0>,
				<DCC_READ 0x2501c004 1 0>,
				<DCC_READ 0x2501d004 1 0>,
				<DCC_READ 0x2501e004 1 0>,
				<DCC_READ 0x2501f004 1 0>,
				<DCC_READ 0x25201004 1 0>,
				<DCC_READ 0x25200004 1 0>,
				<DCC_READ 0x25203004 1 0>,
				<DCC_READ 0x25204004 1 0>,
				<DCC_READ 0x25202004 1 0>,
				<DCC_READ 0x25205004 1 0>,
				<DCC_READ 0x25206004 1 0>,
				<DCC_READ 0x25207004 1 0>,
				<DCC_READ 0x25208004 1 0>,
				<DCC_READ 0x25209004 1 0>,
				<DCC_READ 0x2520a004 1 0>,
				<DCC_READ 0x2520b004 1 0>,
				<DCC_READ 0x2520c004 1 0>,
				<DCC_READ 0x2520d004 1 0>,
				<DCC_READ 0x2520e004 1 0>,
				<DCC_READ 0x2520f004 1 0>,
				<DCC_READ 0x25210004 1 0>,
				<DCC_READ 0x25211004 1 0>,
				<DCC_READ 0x25212004 1 0>,
				<DCC_READ 0x25213004 1 0>,
				<DCC_READ 0x25214004 1 0>,
				<DCC_READ 0x25215004 1 0>,
				<DCC_READ 0x25216004 1 0>,
				<DCC_READ 0x25217004 1 0>,
				<DCC_READ 0x25218004 1 0>,
				<DCC_READ 0x25219004 1 0>,
				<DCC_READ 0x2521a004 1 0>,
				<DCC_READ 0x2521b004 1 0>,
				<DCC_READ 0x2521c004 1 0>,
				<DCC_READ 0x2521d004 1 0>,
				<DCC_READ 0x2521e004 1 0>,
				<DCC_READ 0x2521f004 1 0>,
				<DCC_READ 0x25401004 1 0>,
				<DCC_READ 0x25400004 1 0>,
				<DCC_READ 0x25403004 1 0>,
				<DCC_READ 0x25404004 1 0>,
				<DCC_READ 0x25402004 1 0>,
				<DCC_READ 0x25405004 1 0>,
				<DCC_READ 0x25406004 1 0>,
				<DCC_READ 0x25407004 1 0>,
				<DCC_READ 0x25408004 1 0>,
				<DCC_READ 0x25409004 1 0>,
				<DCC_READ 0x2540a004 1 0>,
				<DCC_READ 0x2540b004 1 0>,
				<DCC_READ 0x2540c004 1 0>,
				<DCC_READ 0x2540d004 1 0>,
				<DCC_READ 0x2540e004 1 0>,
				<DCC_READ 0x2540f004 1 0>,
				<DCC_READ 0x25410004 1 0>,
				<DCC_READ 0x25411004 1 0>,
				<DCC_READ 0x25412004 1 0>,
				<DCC_READ 0x25413004 1 0>,
				<DCC_READ 0x25414004 1 0>,
				<DCC_READ 0x25415004 1 0>,
				<DCC_READ 0x25416004 1 0>,
				<DCC_READ 0x25417004 1 0>,
				<DCC_READ 0x25418004 1 0>,
				<DCC_READ 0x25419004 1 0>,
				<DCC_READ 0x2541a004 1 0>,
				<DCC_READ 0x2541b004 1 0>,
				<DCC_READ 0x2541c004 1 0>,
				<DCC_READ 0x2541d004 1 0>,
				<DCC_READ 0x2541e004 1 0>,
				<DCC_READ 0x2541f004 1 0>,
				<DCC_READ 0x25601004 1 0>,
				<DCC_READ 0x25600004 1 0>,
				<DCC_READ 0x25603004 1 0>,
				<DCC_READ 0x25604004 1 0>,
				<DCC_READ 0x25602004 1 0>,
				<DCC_READ 0x25605004 1 0>,
				<DCC_READ 0x25606004 1 0>,
				<DCC_READ 0x25607004 1 0>,
				<DCC_READ 0x25608004 1 0>,
				<DCC_READ 0x25609004 1 0>,
				<DCC_READ 0x2560a004 1 0>,
				<DCC_READ 0x2560b004 1 0>,
				<DCC_READ 0x2560c004 1 0>,
				<DCC_READ 0x2560d004 1 0>,
				<DCC_READ 0x2560e004 1 0>,
				<DCC_READ 0x2560f004 1 0>,
				<DCC_READ 0x25610004 1 0>,
				<DCC_READ 0x25611004 1 0>,
				<DCC_READ 0x25612004 1 0>,
				<DCC_READ 0x25613004 1 0>,
				<DCC_READ 0x25614004 1 0>,
				<DCC_READ 0x25615004 1 0>,
				<DCC_READ 0x25616004 1 0>,
				<DCC_READ 0x25617004 1 0>,
				<DCC_READ 0x25618004 1 0>,
				<DCC_READ 0x25619004 1 0>,
				<DCC_READ 0x2561a004 1 0>,
				<DCC_READ 0x2561b004 1 0>,
				<DCC_READ 0x2561c004 1 0>,
				<DCC_READ 0x2561d004 1 0>,
				<DCC_READ 0x2561e004 1 0>,
				<DCC_READ 0x2561f004 1 0>,
				<DCC_READ 0x250a002c 1 0>,
				<DCC_READ 0x250a009c 1 0>,
				<DCC_READ 0x250a00a0 1 0>,
				<DCC_READ 0x250a00a8 1 0>,
				<DCC_READ 0x250a00ac 1 0>,
				<DCC_READ 0x250a00b0 1 0>,
				<DCC_READ 0x250a00b8 1 0>,
				<DCC_READ 0x250a00c0 1 0>,
				<DCC_READ 0x250a00c4 1 0>,
				<DCC_READ 0x250a00cc 1 0>,
				<DCC_READ 0x250a00d0 1 0>,
				<DCC_READ 0x250a00d4 1 0>,
				<DCC_READ 0x250a00d8 1 0>,
				<DCC_READ 0x250a00e0 1 0>,
				<DCC_READ 0x250a00e8 1 0>,
				<DCC_READ 0x250a00f0 1 0>,
				<DCC_READ 0x250a00f0 1 0>,
				<DCC_READ 0x250a0100 1 0>,
				<DCC_READ 0x250a0108 1 0>,
				<DCC_READ 0x250a0110 1 0>,
				<DCC_READ 0x250a0118 1 0>,
				<DCC_READ 0x250a0120 1 0>,
				<DCC_READ 0x250a0128 1 0>,
				<DCC_READ 0x250a1010 1 0>,
				<DCC_READ 0x250a1070 1 0>,
				<DCC_READ 0x250a3004 1 0>,
				<DCC_READ 0x254a002c 1 0>,
				<DCC_READ 0x254a009c 1 0>,
				<DCC_READ 0x254a00a0 1 0>,
				<DCC_READ 0x254a00a8 1 0>,
				<DCC_READ 0x254a00ac 1 0>,
				<DCC_READ 0x254a00b0 1 0>,
				<DCC_READ 0x254a00b8 1 0>,
				<DCC_READ 0x254a00c0 1 0>,
				<DCC_READ 0x254a00c4 1 0>,
				<DCC_READ 0x254a00cc 1 0>,
				<DCC_READ 0x254a00d0 1 0>,
				<DCC_READ 0x254a00d4 1 0>,
				<DCC_READ 0x254a00d8 1 0>,
				<DCC_READ 0x254a00e0 1 0>,
				<DCC_READ 0x254a00e8 1 0>,
				<DCC_READ 0x254a00f0 1 0>,
				<DCC_READ 0x254a00f0 1 0>,
				<DCC_READ 0x254a0100 1 0>,
				<DCC_READ 0x254a0108 1 0>,
				<DCC_READ 0x254a0110 1 0>,
				<DCC_READ 0x254a0118 1 0>,
				<DCC_READ 0x254a0120 1 0>,
				<DCC_READ 0x254a0128 1 0>,
				<DCC_READ 0x254a1010 1 0>,
				<DCC_READ 0x254a1070 1 0>,
				<DCC_READ 0x254a3004 1 0>,
				<DCC_READ 0x252a002c 1 0>,
				<DCC_READ 0x252a009c 1 0>,
				<DCC_READ 0x252a00a0 1 0>,
				<DCC_READ 0x252a00a8 1 0>,
				<DCC_READ 0x252a00ac 1 0>,
				<DCC_READ 0x252a00b0 1 0>,
				<DCC_READ 0x252a00b8 1 0>,
				<DCC_READ 0x252a00c0 1 0>,
				<DCC_READ 0x252a00c4 1 0>,
				<DCC_READ 0x252a00cc 1 0>,
				<DCC_READ 0x252a00d0 1 0>,
				<DCC_READ 0x252a00d4 1 0>,
				<DCC_READ 0x252a00d8 1 0>,
				<DCC_READ 0x252a00e0 1 0>,
				<DCC_READ 0x252a00e8 1 0>,
				<DCC_READ 0x252a00f0 1 0>,
				<DCC_READ 0x252a00f0 1 0>,
				<DCC_READ 0x252a0100 1 0>,
				<DCC_READ 0x252a0108 1 0>,
				<DCC_READ 0x252a0110 1 0>,
				<DCC_READ 0x252a0118 1 0>,
				<DCC_READ 0x252a0120 1 0>,
				<DCC_READ 0x252a0128 1 0>,
				<DCC_READ 0x252a1010 1 0>,
				<DCC_READ 0x252a1070 1 0>,
				<DCC_READ 0x252a3004 1 0>,
				<DCC_READ 0x256a002c 1 0>,
				<DCC_READ 0x256a009c 1 0>,
				<DCC_READ 0x256a00a0 1 0>,
				<DCC_READ 0x256a00a8 1 0>,
				<DCC_READ 0x256a00ac 1 0>,
				<DCC_READ 0x256a00b0 1 0>,
				<DCC_READ 0x256a00b8 1 0>,
				<DCC_READ 0x256a00c0 1 0>,
				<DCC_READ 0x256a00c4 1 0>,
				<DCC_READ 0x256a00cc 1 0>,
				<DCC_READ 0x256a00d0 1 0>,
				<DCC_READ 0x256a00d4 1 0>,
				<DCC_READ 0x256a00d8 1 0>,
				<DCC_READ 0x256a00e0 1 0>,
				<DCC_READ 0x256a00e8 1 0>,
				<DCC_READ 0x256a00f0 1 0>,
				<DCC_READ 0x256a00f0 1 0>,
				<DCC_READ 0x256a0100 1 0>,
				<DCC_READ 0x256a0108 1 0>,
				<DCC_READ 0x256a0110 1 0>,
				<DCC_READ 0x256a0118 1 0>,
				<DCC_READ 0x256a0120 1 0>,
				<DCC_READ 0x256a0128 1 0>,
				<DCC_READ 0x256a1010 1 0>,
				<DCC_READ 0x256a1070 1 0>,
				<DCC_READ 0x256a3004 1 0>,
				<DCC_READ 0x2507601C 1 0>,
				<DCC_READ 0x25076020 1 0>,
				<DCC_READ 0x25076024 1 0>,
				<DCC_READ 0x25076028 1 0>,
				<DCC_READ 0x25076034 1 0>,
				<DCC_READ 0x25076038 1 0>,
				<DCC_READ 0x2507603C 1 0>,
				<DCC_READ 0x25076040 1 0>,
				<DCC_READ 0x25076058 1 0>,
				<DCC_READ 0x25076060 1 0>,
				<DCC_READ 0x25076064 1 0>,
				<DCC_READ 0x25076200 1 0>,
				<DCC_READ 0x25077020 1 0>,
				<DCC_READ 0x25077030 1 0>,
				<DCC_READ 0x25077034 1 0>,
				<DCC_READ 0x25077038 1 0>,
				<DCC_READ 0x2507703c 1 0>,
				<DCC_READ 0x25077040 1 0>,
				<DCC_READ 0x25077044 1 0>,
				<DCC_READ 0x25077048 1 0>,
				<DCC_READ 0x2507704c 1 0>,
				<DCC_READ 0x25077050 1 0>,
				<DCC_READ 0x25077054 1 0>,
				<DCC_READ 0x25077058 1 0>,
				<DCC_READ 0x2507705c 1 0>,
				<DCC_READ 0x25077060 1 0>,
				<DCC_READ 0x25077064 1 0>,
				<DCC_READ 0x25077068 1 0>,
				<DCC_READ 0x2507706c 1 0>,
				<DCC_READ 0x25077070 1 0>,
				<DCC_READ 0x25077074 1 0>,
				<DCC_READ 0x25077078 1 0>,
				<DCC_READ 0x2507707c 1 0>,
				<DCC_READ 0x25077084 1 0>,
				<DCC_READ 0x25077090 1 0>,
				<DCC_READ 0x25077094 1 0>,
				<DCC_READ 0x25077098 1 0>,
				<DCC_READ 0x2507709C 1 0>,
				<DCC_READ 0x250770a0 1 0>,
				<DCC_READ 0x25077218 1 0>,
				<DCC_READ 0x2507721c 1 0>,
				<DCC_READ 0x25077220 1 0>,
				<DCC_READ 0x25077224 1 0>,
				<DCC_READ 0x25077228 1 0>,
				<DCC_READ 0x2507722c 1 0>,
				<DCC_READ 0x25077230 1 0>,
				<DCC_READ 0x25077234 1 0>,
				<DCC_READ 0x2547601C 1 0>,
				<DCC_READ 0x25476020 1 0>,
				<DCC_READ 0x25476024 1 0>,
				<DCC_READ 0x25476028 1 0>,
				<DCC_READ 0x25476034 1 0>,
				<DCC_READ 0x25476038 1 0>,
				<DCC_READ 0x2547603C 1 0>,
				<DCC_READ 0x25476040 1 0>,
				<DCC_READ 0x25476058 1 0>,
				<DCC_READ 0x25476060 1 0>,
				<DCC_READ 0x25476064 1 0>,
				<DCC_READ 0x25476200 1 0>,
				<DCC_READ 0x25477020 1 0>,
				<DCC_READ 0x25477030 1 0>,
				<DCC_READ 0x25477034 1 0>,
				<DCC_READ 0x25477038 1 0>,
				<DCC_READ 0x2547703c 1 0>,
				<DCC_READ 0x25477040 1 0>,
				<DCC_READ 0x25477044 1 0>,
				<DCC_READ 0x25477048 1 0>,
				<DCC_READ 0x2547704c 1 0>,
				<DCC_READ 0x25477050 1 0>,
				<DCC_READ 0x25477054 1 0>,
				<DCC_READ 0x25477058 1 0>,
				<DCC_READ 0x2547705c 1 0>,
				<DCC_READ 0x25477060 1 0>,
				<DCC_READ 0x25477064 1 0>,
				<DCC_READ 0x25477068 1 0>,
				<DCC_READ 0x2547706c 1 0>,
				<DCC_READ 0x25477070 1 0>,
				<DCC_READ 0x25477074 1 0>,
				<DCC_READ 0x25477078 1 0>,
				<DCC_READ 0x2547707c 1 0>,
				<DCC_READ 0x25477084 1 0>,
				<DCC_READ 0x25477090 1 0>,
				<DCC_READ 0x25477094 1 0>,
				<DCC_READ 0x25477098 1 0>,
				<DCC_READ 0x2547709C 1 0>,
				<DCC_READ 0x254770a0 1 0>,
				<DCC_READ 0x25477218 1 0>,
				<DCC_READ 0x2547721c 1 0>,
				<DCC_READ 0x25477220 1 0>,
				<DCC_READ 0x25477224 1 0>,
				<DCC_READ 0x25477228 1 0>,
				<DCC_READ 0x2547722c 1 0>,
				<DCC_READ 0x25477230 1 0>,
				<DCC_READ 0x25477234 1 0>,
				<DCC_READ 0x2527601C 1 0>,
				<DCC_READ 0x25276020 1 0>,
				<DCC_READ 0x25276024 1 0>,
				<DCC_READ 0x25276028 1 0>,
				<DCC_READ 0x25276034 1 0>,
				<DCC_READ 0x25276038 1 0>,
				<DCC_READ 0x2527603C 1 0>,
				<DCC_READ 0x25276040 1 0>,
				<DCC_READ 0x25276058 1 0>,
				<DCC_READ 0x25276060 1 0>,
				<DCC_READ 0x25276064 1 0>,
				<DCC_READ 0x25276200 1 0>,
				<DCC_READ 0x25277020 1 0>,
				<DCC_READ 0x25277030 1 0>,
				<DCC_READ 0x25277034 1 0>,
				<DCC_READ 0x25277038 1 0>,
				<DCC_READ 0x2527703c 1 0>,
				<DCC_READ 0x25277040 1 0>,
				<DCC_READ 0x25277044 1 0>,
				<DCC_READ 0x25277048 1 0>,
				<DCC_READ 0x2527704c 1 0>,
				<DCC_READ 0x25277050 1 0>,
				<DCC_READ 0x25277054 1 0>,
				<DCC_READ 0x25277058 1 0>,
				<DCC_READ 0x2527705c 1 0>,
				<DCC_READ 0x25277060 1 0>,
				<DCC_READ 0x25277064 1 0>,
				<DCC_READ 0x25277068 1 0>,
				<DCC_READ 0x2527706c 1 0>,
				<DCC_READ 0x25277070 1 0>,
				<DCC_READ 0x25277074 1 0>,
				<DCC_READ 0x25277078 1 0>,
				<DCC_READ 0x2527707c 1 0>,
				<DCC_READ 0x25277084 1 0>,
				<DCC_READ 0x25277090 1 0>,
				<DCC_READ 0x25277094 1 0>,
				<DCC_READ 0x25277098 1 0>,
				<DCC_READ 0x2527709C 1 0>,
				<DCC_READ 0x252770a0 1 0>,
				<DCC_READ 0x25277218 1 0>,
				<DCC_READ 0x2527721c 1 0>,
				<DCC_READ 0x25277220 1 0>,
				<DCC_READ 0x25277224 1 0>,
				<DCC_READ 0x25277228 1 0>,
				<DCC_READ 0x2527722c 1 0>,
				<DCC_READ 0x25277230 1 0>,
				<DCC_READ 0x25277234 1 0>,
				<DCC_READ 0x2567601C 1 0>,
				<DCC_READ 0x25676020 1 0>,
				<DCC_READ 0x25676024 1 0>,
				<DCC_READ 0x25676028 1 0>,
				<DCC_READ 0x25676034 1 0>,
				<DCC_READ 0x25676038 1 0>,
				<DCC_READ 0x2567603C 1 0>,
				<DCC_READ 0x25676040 1 0>,
				<DCC_READ 0x25676058 1 0>,
				<DCC_READ 0x25676060 1 0>,
				<DCC_READ 0x25676064 1 0>,
				<DCC_READ 0x25676200 1 0>,
				<DCC_READ 0x25677020 1 0>,
				<DCC_READ 0x25677030 1 0>,
				<DCC_READ 0x25677034 1 0>,
				<DCC_READ 0x25677038 1 0>,
				<DCC_READ 0x2567703c 1 0>,
				<DCC_READ 0x25677040 1 0>,
				<DCC_READ 0x25677044 1 0>,
				<DCC_READ 0x25677048 1 0>,
				<DCC_READ 0x2567704c 1 0>,
				<DCC_READ 0x25677050 1 0>,
				<DCC_READ 0x25677054 1 0>,
				<DCC_READ 0x25677058 1 0>,
				<DCC_READ 0x2567705c 1 0>,
				<DCC_READ 0x25677060 1 0>,
				<DCC_READ 0x25677064 1 0>,
				<DCC_READ 0x25677068 1 0>,
				<DCC_READ 0x2567706c 1 0>,
				<DCC_READ 0x25677070 1 0>,
				<DCC_READ 0x25677074 1 0>,
				<DCC_READ 0x25677078 1 0>,
				<DCC_READ 0x2567707c 1 0>,
				<DCC_READ 0x25677084 1 0>,
				<DCC_READ 0x25677090 1 0>,
				<DCC_READ 0x25677094 1 0>,
				<DCC_READ 0x25677098 1 0>,
				<DCC_READ 0x2567709C 1 0>,
				<DCC_READ 0x256770a0 1 0>,
				<DCC_READ 0x25677218 1 0>,
				<DCC_READ 0x2567721c 1 0>,
				<DCC_READ 0x25677220 1 0>,
				<DCC_READ 0x25677224 1 0>,
				<DCC_READ 0x25677228 1 0>,
				<DCC_READ 0x2567722c 1 0>,
				<DCC_READ 0x25677230 1 0>,
				<DCC_READ 0x25677234 1 0>,
				<DCC_READ 0x250a6008 1 0>,
				<DCC_READ 0x250a600c 1 0>,
				<DCC_READ 0x250a6010 1 0>,
				<DCC_READ 0x250a7008 1 0>,
				<DCC_READ 0x250a700c 1 0>,
				<DCC_READ 0x250a7010 1 0>,
				<DCC_READ 0x254a6008 1 0>,
				<DCC_READ 0x254a600c 1 0>,
				<DCC_READ 0x254a6010 1 0>,
				<DCC_READ 0x254a7008 1 0>,
				<DCC_READ 0x254a700c 1 0>,
				<DCC_READ 0x254a7010 1 0>,
				<DCC_READ 0x252a6008 1 0>,
				<DCC_READ 0x252a600c 1 0>,
				<DCC_READ 0x252a6010 1 0>,
				<DCC_READ 0x252a7008 1 0>,
				<DCC_READ 0x252a700c 1 0>,
				<DCC_READ 0x252a7010 1 0>,
				<DCC_READ 0x256a6008 1 0>,
				<DCC_READ 0x256a600c 1 0>,
				<DCC_READ 0x256a6010 1 0>,
				<DCC_READ 0x256a7008 1 0>,
				<DCC_READ 0x256a700c 1 0>,
				<DCC_READ 0x256a7010 1 0>,
				<DCC_READ 0x2507718c 1 0>,
				<DCC_READ 0x250771b0 1 0>,
				<DCC_READ 0x25077204 1 0>,
				<DCC_READ 0x25077208 1 0>,
				<DCC_READ 0x2507720c 1 0>,
				<DCC_READ 0x25077210 1 0>,
				<DCC_READ 0x25077214 1 0>,
				<DCC_READ 0x25023210 1 0>,
				<DCC_READ 0x25025010 1 0>,
				<DCC_READ 0x25025000 1 0>,
				<DCC_READ 0x25040064 1 0>,
				<DCC_READ 0x25040070 1 0>,
				<DCC_READ 0x25040074 1 0>,
				<DCC_READ 0x25040078 1 0>,
				<DCC_READ 0x2504007c 1 0>,
				<DCC_READ 0x25040080 1 0>,
				<DCC_READ 0x2504002c 1 0>,
				<DCC_READ 0x25040030 1 0>,
				<DCC_READ 0x25040034 1 0>,
				<DCC_READ 0x25040038 1 0>,
				<DCC_READ 0x25040048 1 0>,
				<DCC_READ 0x2504004c 1 0>,
				<DCC_READ 0x25040050 1 0>,
				<DCC_READ 0x25040054 1 0>,
				<DCC_READ 0x25040058 1 0>,
				<DCC_READ 0x25040060 1 0>,
				<DCC_READ 0x2547718c 1 0>,
				<DCC_READ 0x254771b0 1 0>,
				<DCC_READ 0x25477204 1 0>,
				<DCC_READ 0x25477208 1 0>,
				<DCC_READ 0x2547720c 1 0>,
				<DCC_READ 0x25477210 1 0>,
				<DCC_READ 0x25477214 1 0>,
				<DCC_READ 0x25423210 1 0>,
				<DCC_READ 0x25425010 1 0>,
				<DCC_READ 0x25425000 1 0>,
				<DCC_READ 0x25440064 1 0>,
				<DCC_READ 0x25440070 1 0>,
				<DCC_READ 0x25440074 1 0>,
				<DCC_READ 0x25440078 1 0>,
				<DCC_READ 0x2544007c 1 0>,
				<DCC_READ 0x25440080 1 0>,
				<DCC_READ 0x2544002c 1 0>,
				<DCC_READ 0x25440030 1 0>,
				<DCC_READ 0x25440034 1 0>,
				<DCC_READ 0x25440038 1 0>,
				<DCC_READ 0x25440048 1 0>,
				<DCC_READ 0x2544004c 1 0>,
				<DCC_READ 0x25440050 1 0>,
				<DCC_READ 0x25440054 1 0>,
				<DCC_READ 0x25440058 1 0>,
				<DCC_READ 0x25440060 1 0>,
				<DCC_READ 0x2527718c 1 0>,
				<DCC_READ 0x252771b0 1 0>,
				<DCC_READ 0x25277204 1 0>,
				<DCC_READ 0x25277208 1 0>,
				<DCC_READ 0x2527720c 1 0>,
				<DCC_READ 0x25277210 1 0>,
				<DCC_READ 0x25277214 1 0>,
				<DCC_READ 0x25223210 1 0>,
				<DCC_READ 0x25225010 1 0>,
				<DCC_READ 0x25225000 1 0>,
				<DCC_READ 0x25240064 1 0>,
				<DCC_READ 0x25240070 1 0>,
				<DCC_READ 0x25240074 1 0>,
				<DCC_READ 0x25240078 1 0>,
				<DCC_READ 0x2524007c 1 0>,
				<DCC_READ 0x25240080 1 0>,
				<DCC_READ 0x2524002c 1 0>,
				<DCC_READ 0x25240030 1 0>,
				<DCC_READ 0x25240034 1 0>,
				<DCC_READ 0x25240038 1 0>,
				<DCC_READ 0x25240048 1 0>,
				<DCC_READ 0x2524004c 1 0>,
				<DCC_READ 0x25240050 1 0>,
				<DCC_READ 0x25240054 1 0>,
				<DCC_READ 0x25240058 1 0>,
				<DCC_READ 0x25240060 1 0>,
				<DCC_READ 0x2567718c 1 0>,
				<DCC_READ 0x256771b0 1 0>,
				<DCC_READ 0x25677204 1 0>,
				<DCC_READ 0x25677208 1 0>,
				<DCC_READ 0x2567720c 1 0>,
				<DCC_READ 0x25677210 1 0>,
				<DCC_READ 0x25677214 1 0>,
				<DCC_READ 0x25623210 1 0>,
				<DCC_READ 0x25625010 1 0>,
				<DCC_READ 0x25625000 1 0>,
				<DCC_READ 0x25640064 1 0>,
				<DCC_READ 0x25640070 1 0>,
				<DCC_READ 0x25640074 1 0>,
				<DCC_READ 0x25640078 1 0>,
				<DCC_READ 0x2564007c 1 0>,
				<DCC_READ 0x25640080 1 0>,
				<DCC_READ 0x2564002c 1 0>,
				<DCC_READ 0x25640030 1 0>,
				<DCC_READ 0x25640034 1 0>,
				<DCC_READ 0x25640038 1 0>,
				<DCC_READ 0x25640048 1 0>,
				<DCC_READ 0x2564004c 1 0>,
				<DCC_READ 0x25640050 1 0>,
				<DCC_READ 0x25640054 1 0>,
				<DCC_READ 0x25640058 1 0>,
				<DCC_READ 0x25640060 1 0>,
				<DCC_READ 0x250a9004 1 0>,
				<DCC_READ 0x250a9010 1 0>,
				<DCC_READ 0x250a9014 1 0>,
				<DCC_READ 0x250a9018 1 0>,
				<DCC_READ 0x250a9020 1 0>,
				<DCC_READ 0x250a9024 1 0>,
				<DCC_READ 0x250a9028 1 0>,
				<DCC_READ 0x250a9030 1 0>,
				<DCC_READ 0x250a9034 1 0>,
				<DCC_READ 0x250a9038 1 0>,
				<DCC_READ 0x250a9040 1 0>,
				<DCC_READ 0x250a9044 1 0>,
				<DCC_READ 0x250a9048 1 0>,
				<DCC_READ 0x250a9050 1 0>,
				<DCC_READ 0x250a9054 1 0>,
				<DCC_READ 0x250a9058 1 0>,
				<DCC_READ 0x250aa004 1 0>,
				<DCC_READ 0x250aa010 1 0>,
				<DCC_READ 0x250aa014 1 0>,
				<DCC_READ 0x250aa018 1 0>,
				<DCC_READ 0x250aa020 1 0>,
				<DCC_READ 0x250aa024 1 0>,
				<DCC_READ 0x250aa028 1 0>,
				<DCC_READ 0x250aa030 1 0>,
				<DCC_READ 0x250aa034 1 0>,
				<DCC_READ 0x250aa038 1 0>,
				<DCC_READ 0x250aa040 1 0>,
				<DCC_READ 0x250aa044 1 0>,
				<DCC_READ 0x250aa048 1 0>,
				<DCC_READ 0x250aa050 1 0>,
				<DCC_READ 0x250aa054 1 0>,
				<DCC_READ 0x250aa058 1 0>,
				<DCC_READ 0x250b001c 1 0>,
				<DCC_READ 0x250b101c 1 0>,
				<DCC_READ 0x250b201c 1 0>,
				<DCC_READ 0x250b301c 1 0>,
				<DCC_READ 0x250b401c 1 0>,
				<DCC_READ 0x250b501c 1 0>,
				<DCC_READ 0x250b601c 1 0>,
				<DCC_READ 0x250b701c 1 0>,
				<DCC_READ 0x250b801c 1 0>,
				<DCC_READ 0x250b901c 1 0>,
				<DCC_READ 0x250ba01c 1 0>,
				<DCC_READ 0x250bb01c 1 0>,
				<DCC_READ 0x250bc01c 1 0>,
				<DCC_READ 0x250bd01c 1 0>,
				<DCC_READ 0x250be01c 1 0>,
				<DCC_READ 0x250bf01c 1 0>,
				<DCC_READ 0x254a9004 1 0>,
				<DCC_READ 0x254a9010 1 0>,
				<DCC_READ 0x254a9014 1 0>,
				<DCC_READ 0x254a9018 1 0>,
				<DCC_READ 0x254a9020 1 0>,
				<DCC_READ 0x254a9024 1 0>,
				<DCC_READ 0x254a9028 1 0>,
				<DCC_READ 0x254a9030 1 0>,
				<DCC_READ 0x254a9034 1 0>,
				<DCC_READ 0x254a9038 1 0>,
				<DCC_READ 0x254a9040 1 0>,
				<DCC_READ 0x254a9044 1 0>,
				<DCC_READ 0x254a9048 1 0>,
				<DCC_READ 0x254a9050 1 0>,
				<DCC_READ 0x254a9054 1 0>,
				<DCC_READ 0x254a9058 1 0>,
				<DCC_READ 0x254aa004 1 0>,
				<DCC_READ 0x254aa010 1 0>,
				<DCC_READ 0x254aa014 1 0>,
				<DCC_READ 0x254aa018 1 0>,
				<DCC_READ 0x254aa020 1 0>,
				<DCC_READ 0x254aa024 1 0>,
				<DCC_READ 0x254aa028 1 0>,
				<DCC_READ 0x254aa030 1 0>,
				<DCC_READ 0x254aa034 1 0>,
				<DCC_READ 0x254aa038 1 0>,
				<DCC_READ 0x254aa040 1 0>,
				<DCC_READ 0x254aa044 1 0>,
				<DCC_READ 0x254aa048 1 0>,
				<DCC_READ 0x254aa050 1 0>,
				<DCC_READ 0x254aa054 1 0>,
				<DCC_READ 0x254aa058 1 0>,
				<DCC_READ 0x254b001c 1 0>,
				<DCC_READ 0x254b101c 1 0>,
				<DCC_READ 0x254b201c 1 0>,
				<DCC_READ 0x254b301c 1 0>,
				<DCC_READ 0x254b401c 1 0>,
				<DCC_READ 0x254b501c 1 0>,
				<DCC_READ 0x254b601c 1 0>,
				<DCC_READ 0x254b701c 1 0>,
				<DCC_READ 0x254b801c 1 0>,
				<DCC_READ 0x254b901c 1 0>,
				<DCC_READ 0x254ba01c 1 0>,
				<DCC_READ 0x254bb01c 1 0>,
				<DCC_READ 0x254bc01c 1 0>,
				<DCC_READ 0x254bd01c 1 0>,
				<DCC_READ 0x254be01c 1 0>,
				<DCC_READ 0x254bf01c 1 0>,
				<DCC_READ 0x252a9004 1 0>,
				<DCC_READ 0x252a9010 1 0>,
				<DCC_READ 0x252a9014 1 0>,
				<DCC_READ 0x252a9018 1 0>,
				<DCC_READ 0x252a9020 1 0>,
				<DCC_READ 0x252a9024 1 0>,
				<DCC_READ 0x252a9028 1 0>,
				<DCC_READ 0x252a9030 1 0>,
				<DCC_READ 0x252a9034 1 0>,
				<DCC_READ 0x252a9038 1 0>,
				<DCC_READ 0x252a9040 1 0>,
				<DCC_READ 0x252a9044 1 0>,
				<DCC_READ 0x252a9048 1 0>,
				<DCC_READ 0x252a9050 1 0>,
				<DCC_READ 0x252a9054 1 0>,
				<DCC_READ 0x252a9058 1 0>,
				<DCC_READ 0x252aa004 1 0>,
				<DCC_READ 0x252aa010 1 0>,
				<DCC_READ 0x252aa014 1 0>,
				<DCC_READ 0x252aa018 1 0>,
				<DCC_READ 0x252aa020 1 0>,
				<DCC_READ 0x252aa024 1 0>,
				<DCC_READ 0x252aa028 1 0>,
				<DCC_READ 0x252aa030 1 0>,
				<DCC_READ 0x252aa034 1 0>,
				<DCC_READ 0x252aa038 1 0>,
				<DCC_READ 0x252aa040 1 0>,
				<DCC_READ 0x252aa044 1 0>,
				<DCC_READ 0x252aa048 1 0>,
				<DCC_READ 0x252aa050 1 0>,
				<DCC_READ 0x252aa054 1 0>,
				<DCC_READ 0x252aa058 1 0>,
				<DCC_READ 0x252b001c 1 0>,
				<DCC_READ 0x252b101c 1 0>,
				<DCC_READ 0x252b201c 1 0>,
				<DCC_READ 0x252b301c 1 0>,
				<DCC_READ 0x252b401c 1 0>,
				<DCC_READ 0x252b501c 1 0>,
				<DCC_READ 0x252b601c 1 0>,
				<DCC_READ 0x252b701c 1 0>,
				<DCC_READ 0x252b801c 1 0>,
				<DCC_READ 0x252b901c 1 0>,
				<DCC_READ 0x252ba01c 1 0>,
				<DCC_READ 0x252bb01c 1 0>,
				<DCC_READ 0x252bc01c 1 0>,
				<DCC_READ 0x252bd01c 1 0>,
				<DCC_READ 0x252be01c 1 0>,
				<DCC_READ 0x252bf01c 1 0>,
				<DCC_READ 0x256a9004 1 0>,
				<DCC_READ 0x256a9010 1 0>,
				<DCC_READ 0x256a9014 1 0>,
				<DCC_READ 0x256a9018 1 0>,
				<DCC_READ 0x256a9020 1 0>,
				<DCC_READ 0x256a9024 1 0>,
				<DCC_READ 0x256a9028 1 0>,
				<DCC_READ 0x256a9030 1 0>,
				<DCC_READ 0x256a9034 1 0>,
				<DCC_READ 0x256a9038 1 0>,
				<DCC_READ 0x256a9040 1 0>,
				<DCC_READ 0x256a9044 1 0>,
				<DCC_READ 0x256a9048 1 0>,
				<DCC_READ 0x256a9050 1 0>,
				<DCC_READ 0x256a9054 1 0>,
				<DCC_READ 0x256a9058 1 0>,
				<DCC_READ 0x256aa004 1 0>,
				<DCC_READ 0x256aa010 1 0>,
				<DCC_READ 0x256aa014 1 0>,
				<DCC_READ 0x256aa018 1 0>,
				<DCC_READ 0x256aa020 1 0>,
				<DCC_READ 0x256aa024 1 0>,
				<DCC_READ 0x256aa028 1 0>,
				<DCC_READ 0x256aa030 1 0>,
				<DCC_READ 0x256aa034 1 0>,
				<DCC_READ 0x256aa038 1 0>,
				<DCC_READ 0x256aa040 1 0>,
				<DCC_READ 0x256aa044 1 0>,
				<DCC_READ 0x256aa048 1 0>,
				<DCC_READ 0x256aa050 1 0>,
				<DCC_READ 0x256aa054 1 0>,
				<DCC_READ 0x256aa058 1 0>,
				<DCC_READ 0x256b001c 1 0>,
				<DCC_READ 0x256b101c 1 0>,
				<DCC_READ 0x256b201c 1 0>,
				<DCC_READ 0x256b301c 1 0>,
				<DCC_READ 0x256b401c 1 0>,
				<DCC_READ 0x256b501c 1 0>,
				<DCC_READ 0x256b601c 1 0>,
				<DCC_READ 0x256b701c 1 0>,
				<DCC_READ 0x256b801c 1 0>,
				<DCC_READ 0x256b901c 1 0>,
				<DCC_READ 0x256ba01c 1 0>,
				<DCC_READ 0x256bb01c 1 0>,
				<DCC_READ 0x256bc01c 1 0>,
				<DCC_READ 0x256bd01c 1 0>,
				<DCC_READ 0x256be01c 1 0>,
				<DCC_READ 0x256bf01c 1 0>,
				<DCC_READ 0x258a4040 1 0>,
				<DCC_READ 0x258a4044 1 0>,
				<DCC_READ 0x258a4048 1 0>,
				<DCC_READ 0x258a404c 1 0>,
				<DCC_READ 0x258a4050 1 0>,
				<DCC_READ 0x258a4054 1 0>,
				<DCC_READ 0x258a4058 1 0>,
				<DCC_READ 0x258a405c 1 0>,
				<DCC_READ 0x258a4060 1 0>,
				<DCC_READ 0x258a4064 1 0>,
				<DCC_READ 0x258a4068 1 0>,
				<DCC_READ 0x258a406c 1 0>,
				<DCC_READ 0x258a4070 1 0>,
				<DCC_READ 0x258a4074 1 0>,
				<DCC_READ 0x258a4078 1 0>,
				<DCC_READ 0x258a407c 1 0>,
				<DCC_READ 0x258a4080 1 0>,
				<DCC_READ 0x258a4084 1 0>,
				<DCC_READ 0x258a4088 1 0>,
				<DCC_READ 0x258a408c 1 0>,
				<DCC_READ 0x258a4090 1 0>,
				<DCC_READ 0x258a4094 1 0>,
				<DCC_READ 0x258a4098 1 0>,
				<DCC_READ 0x258a409c 1 0>,
				<DCC_READ 0x258a40a0 1 0>,
				<DCC_READ 0x258a40a4 1 0>,
				<DCC_READ 0x258a40a8 1 0>,
				<DCC_READ 0x258a40ac 1 0>,
				<DCC_READ 0x258a40b0 1 0>,
				<DCC_READ 0x258a40b4 1 0>,
				<DCC_READ 0x258a40b8 1 0>,
				<DCC_READ 0x258a40bc 1 0>,
				<DCC_READ 0x258a40c0 1 0>,
				<DCC_READ 0x258a40c4 1 0>,
				<DCC_READ 0x258a40c8 1 0>,
				<DCC_READ 0x258a40cc 1 0>,
				<DCC_READ 0x258a40d0 1 0>,
				<DCC_READ 0x258a40d4 1 0>,
				<DCC_READ 0x258a40d8 1 0>,
				<DCC_READ 0x258a40dc 1 0>,
				<DCC_READ 0x258a40e0 1 0>,
				<DCC_READ 0x258a40e4 1 0>,
				<DCC_READ 0x258a40e8 1 0>,
				<DCC_READ 0x258a40ec 1 0>,
				<DCC_READ 0x258a40f0 1 0>,
				<DCC_READ 0x258a40f4 1 0>,
				<DCC_READ 0x258a40f8 1 0>,
				<DCC_READ 0x258a40fc 1 0>,
				<DCC_READ 0x258b0000 1 0>,
				<DCC_READ 0x258b1000 1 0>,
				<DCC_READ 0x258b2000 1 0>,
				<DCC_READ 0x258b3000 1 0>,
				<DCC_READ 0x258b4000 1 0>,
				<DCC_READ 0x258b5000 1 0>,
				<DCC_READ 0x258b6000 1 0>,
				<DCC_READ 0x258b7000 1 0>,
				<DCC_READ 0x258b8000 1 0>,
				<DCC_READ 0x258b9000 1 0>,
				<DCC_READ 0x258ba000 1 0>,
				<DCC_READ 0x258bb000 1 0>,
				<DCC_READ 0x258bc000 1 0>,
				<DCC_READ 0x258bd000 1 0>,
				<DCC_READ 0x258be000 1 0>,
				<DCC_READ 0x258bf000 1 0>,
				<DCC_READ 0x258b005c 1 0>,
				<DCC_READ 0x258b105c 1 0>,
				<DCC_READ 0x258b205c 1 0>,
				<DCC_READ 0x258b305c 1 0>,
				<DCC_READ 0x258b405c 1 0>,
				<DCC_READ 0x258b505c 1 0>,
				<DCC_READ 0x258b605c 1 0>,
				<DCC_READ 0x258b705c 1 0>,
				<DCC_READ 0x258b805c 1 0>,
				<DCC_READ 0x258b905c 1 0>,
				<DCC_READ 0x258ba05c 1 0>,
				<DCC_READ 0x258bb05c 1 0>,
				<DCC_READ 0x258bc05c 1 0>,
				<DCC_READ 0x258bd05c 1 0>,
				<DCC_READ 0x258be05c 1 0>,
				<DCC_READ 0x258bf05c 1 0>,
				<DCC_READ 0x32302028 1 0>,
				<DCC_READ 0x320A4404 2 0>,
				<DCC_READ 0x323C0404 2 0>,
				<DCC_READ 0x03D94000 1 0>,
				<DCC_READ 0x03D94004 1 0>,
				<DCC_READ 0x03D94008 1 0>,
				<DCC_READ 0x03D95000 1 0>,
				<DCC_READ 0x03D95004 1 0>,
				<DCC_READ 0x03D95008 1 0>,
				<DCC_READ 0x03D9500C 1 0>,
				<DCC_READ 0x03D95010 1 0>,
				<DCC_READ 0x03D96000 1 0>,
				<DCC_READ 0x03D96004 1 0>,
				<DCC_READ 0x03D96008 1 0>,
				<DCC_READ 0x03D9600C 1 0>,
				<DCC_READ 0x03D96010 1 0>,
				<DCC_READ 0x03D97000 1 0>,
				<DCC_READ 0x03D97004 1 0>,
				<DCC_READ 0x03D97008 1 0>,
				<DCC_READ 0x03D9700C 1 0>,
				<DCC_READ 0x03D97010 1 0>,
				<DCC_READ 0x03D98000 1 0>,
				<DCC_READ 0x03D98004 1 0>,
				<DCC_READ 0x03D98008 1 0>,
				<DCC_READ 0x03D9800C 1 0>,
				<DCC_READ 0x03D98010 1 0>,
				<DCC_READ 0x03D99000 1 0>,
				<DCC_READ 0x03D99004 1 0>,
				<DCC_READ 0x03D99008 1 0>,
				<DCC_READ 0x03D9900C 1 0>,
				<DCC_READ 0x03D99010 1 0>,
				<DCC_READ 0x03D99014 1 0>,
				<DCC_READ 0x03D99050 1 0>,
				<DCC_READ 0x03D99054 1 0>,
				<DCC_READ 0x03D99058 1 0>,
				<DCC_READ 0x03D9905C 1 0>,
				<DCC_READ 0x03D99060 1 0>,
				<DCC_READ 0x03D99064 1 0>,
				<DCC_READ 0x03D99068 1 0>,
				<DCC_READ 0x03D9906C 1 0>,
				<DCC_READ 0x03D99070 1 0>,
				<DCC_READ 0x03D99074 1 0>,
				<DCC_READ 0x03D990A8 1 0>,
				<DCC_READ 0x03D990AC 1 0>,
				<DCC_READ 0x03D990B0 1 0>,
				<DCC_READ 0x03D990B4 1 0>,
				<DCC_READ 0x03D990B8 1 0>,
				<DCC_READ 0x03D990BC 1 0>,
				<DCC_READ 0x03D990C0 1 0>,
				<DCC_READ 0x03D990C8 1 0>,
				<DCC_READ 0x03D990CC 1 0>,
				<DCC_READ 0x03D990D0 1 0>,
				<DCC_READ 0x03D99104 1 0>,
				<DCC_READ 0x03D99108 1 0>,
				<DCC_READ 0x03D9910C 1 0>,
				<DCC_READ 0x03D99110 1 0>,
				<DCC_READ 0x03D99114 1 0>,
				<DCC_READ 0x03D99118 1 0>,
				<DCC_READ 0x03D9911C 1 0>,
				<DCC_READ 0x03D99120 1 0>,
				<DCC_READ 0x03D99124 1 0>,
				<DCC_READ 0x03D99128 1 0>,
				<DCC_READ 0x03D9912C 1 0>,
				<DCC_READ 0x03D99134 1 0>,
				<DCC_READ 0x03D99138 1 0>,
				<DCC_READ 0x03D9913C 1 0>,
				<DCC_READ 0x03D99140 1 0>,
				<DCC_READ 0x03D99144 1 0>,
				<DCC_READ 0x03D99148 1 0>,
				<DCC_READ 0x03D9914C 1 0>,
				<DCC_READ 0x03D99150 1 0>,
				<DCC_READ 0x03D99154 1 0>,
				<DCC_READ 0x03D99158 1 0>,
				<DCC_READ 0x03D9915C 1 0>,
				<DCC_READ 0x03D99160 1 0>,
				<DCC_READ 0x03D99164 1 0>,
				<DCC_READ 0x03D99168 1 0>,
				<DCC_READ 0x03D9916C 1 0>,
				<DCC_READ 0x03D99170 1 0>,
				<DCC_READ 0x03D99174 1 0>,
				<DCC_READ 0x03D99178 1 0>,
				<DCC_READ 0x03D9917C 1 0>,
				<DCC_READ 0x03D99180 1 0>,
				<DCC_READ 0x03D99184 1 0>,
				<DCC_READ 0x03D99188 1 0>,
				<DCC_READ 0x03D9918C 1 0>,
				<DCC_READ 0x03D99198 1 0>,
				<DCC_READ 0x03D9919C 1 0>,
				<DCC_READ 0x03D991A0 1 0>,
				<DCC_READ 0x03D991E0 1 0>,
				<DCC_READ 0x03D991E4 1 0>,
				<DCC_READ 0x03D991E8 1 0>,
				<DCC_READ 0x03D99224 1 0>,
				<DCC_READ 0x03D99228 1 0>,
				<DCC_READ 0x03D99270 1 0>,
				<DCC_READ 0x03D99274 1 0>,
				<DCC_READ 0x03D99278 1 0>,
				<DCC_READ 0x03D99280 1 0>,
				<DCC_READ 0x03D99284 1 0>,
				<DCC_READ 0x03D99288 1 0>,
				<DCC_READ 0x03D9928C 1 0>,
				<DCC_READ 0x03D99290 1 0>,
				<DCC_READ 0x03D99294 1 0>,
				<DCC_READ 0x03D99298 1 0>,
				<DCC_READ 0x03D99314 1 0>,
				<DCC_READ 0x03D99318 1 0>,
				<DCC_READ 0x03D9931C 1 0>,
				<DCC_READ 0x03D99358 1 0>,
				<DCC_READ 0x03D9935C 1 0>,
				<DCC_READ 0x03D99360 1 0>,
				<DCC_READ 0x03D993A0 1 0>,
				<DCC_READ 0x03D993A4 1 0>,
				<DCC_READ 0x03D993E4 1 0>,
				<DCC_READ 0x03D993E8 1 0>,
				<DCC_READ 0x03D993EC 1 0>,
				<DCC_READ 0x03D993F0 1 0>,
				<DCC_READ 0x03D9942C 1 0>,
				<DCC_READ 0x03D99470 1 0>,
				<DCC_READ 0x03D99474 1 0>,
				<DCC_READ 0x03D99478 1 0>,
				<DCC_READ 0x03D99500 1 0>,
				<DCC_READ 0x03D99504 1 0>,
				<DCC_READ 0x03D99508 1 0>,
				<DCC_READ 0x03D9950C 1 0>,
				<DCC_READ 0x03D99510 1 0>,
				<DCC_READ 0x03D99514 1 0>,
				<DCC_READ 0x03D99518 1 0>,
				<DCC_READ 0x03D9951C 1 0>,
				<DCC_READ 0x03D99520 1 0>,
				<DCC_READ 0x03D99524 1 0>,
				<DCC_READ 0x03D99528 1 0>,
				<DCC_READ 0x03D9952C 1 0>,
				<DCC_READ 0x03D99530 1 0>,
				<DCC_READ 0x03D99534 1 0>,
				<DCC_READ 0x03D99538 1 0>,
				<DCC_READ 0x03D99550 1 0>,
				<DCC_READ 0x03D99554 1 0>,
				<DCC_READ 0x03D99558 1 0>,
				<DCC_READ 0x03D9955C 1 0>,
				<DCC_READ 0x03D99560 1 0>,
				<DCC_READ 0x03D99564 1 0>,
				<DCC_READ 0x03D99568 1 0>,
				<DCC_READ 0x03D9956C 1 0>,
				<DCC_READ 0x03D99570 1 0>,
				<DCC_READ 0x03D99574 1 0>,
				<DCC_READ 0x03D99578 1 0>,
				<DCC_READ 0x03D9957C 1 0>,
				<DCC_READ 0x03D99580 1 0>,
				<DCC_READ 0x03D99584 1 0>,
				<DCC_READ 0x03D99588 1 0>,
				<DCC_READ 0x03D9958C 1 0>,
				<DCC_READ 0x03D99590 1 0>,
				<DCC_READ 0x03D99594 1 0>,
				<DCC_READ 0x03D99598 1 0>,
				<DCC_READ 0x03D9959C 1 0>,
				<DCC_READ 0x03D995A0 1 0>,
				<DCC_READ 0x03D995A4 1 0>,
				<DCC_READ 0x03D995A8 1 0>,
				<DCC_READ 0x03D995AC 1 0>,
				<DCC_READ 0x03D995B0 1 0>,
				<DCC_READ 0x03D995B4 1 0>,
				<DCC_READ 0x03D995B8 1 0>,
				<DCC_READ 0x03D995BC 1 0>,
				<DCC_READ 0x03D995C0 1 0>,
				<DCC_READ 0x03D995C4 1 0>,
				<DCC_READ 0x03D995C8 1 0>,
				<DCC_READ 0x03D995CC 1 0>,
				<DCC_READ 0x03D995D8 1 0>,
				<DCC_READ 0x03D995DC 1 0>,
				<DCC_READ 0x03D995E0 1 0>,
				<DCC_READ 0x03D995E4 1 0>,
				<DCC_READ 0x03D995E8 1 0>,
				<DCC_READ 0x03D40000 1 0>,
				<DCC_READ 0x03D40004 1 0>,
				<DCC_READ 0x03D40008 1 0>,
				<DCC_READ 0x03D4000C 1 0>,
				<DCC_READ 0x03D41000 1 0>,
				<DCC_READ 0x03D41004 1 0>,
				<DCC_READ 0x03D41008 1 0>,
				<DCC_READ 0x03D4100C 1 0>,
				<DCC_READ 0x03D42000 1 0>,
				<DCC_READ 0x03D42004 1 0>,
				<DCC_READ 0x03D42008 1 0>,
				<DCC_READ 0x03D4200C 1 0>,
				<DCC_READ 0x03D43000 1 0>,
				<DCC_READ 0x03D43004 1 0>,
				<DCC_READ 0x03D43008 1 0>,
				<DCC_READ 0x03D4300C 1 0>,
				<DCC_READ 0x03D44000 1 0>,
				<DCC_READ 0x03D44004 1 0>,
				<DCC_READ 0x03D44008 1 0>,
				<DCC_READ 0x03D4400C 1 0>,
				<DCC_READ 0x03D45000 1 0>,
				<DCC_READ 0x03D45004 1 0>,
				<DCC_READ 0x03D45008 1 0>,
				<DCC_READ 0x03D4500C 1 0>,
				<DCC_READ 0x03D46000 1 0>,
				<DCC_READ 0x03D46004 1 0>,
				<DCC_READ 0x03D46008 1 0>,
				<DCC_READ 0x03D4600C 1 0>,
				<DCC_READ 0x03D47000 1 0>,
				<DCC_READ 0x03D47004 1 0>,
				<DCC_READ 0x03D47008 1 0>,
				<DCC_READ 0x03D4700C 1 0>,
				<DCC_READ 0x03D48000 1 0>,
				<DCC_READ 0x03D49000 1 0>,
				<DCC_READ 0x03D4A000 1 0>,
				<DCC_READ 0x03D4B000 1 0>,
				<DCC_READ 0x03D4C000 1 0>,
				<DCC_READ 0x03D4D000 1 0>,
				<DCC_READ 0x03D4E000 1 0>,
				<DCC_READ 0x03D4F000 1 0>,
				<DCC_READ 0x03D8E000 1 0>,
				<DCC_READ 0x03D8E004 1 0>,
				<DCC_READ 0x03D8E008 1 0>,
				<DCC_READ 0x03D8E00C 1 0>,
				<DCC_READ 0x03D8E010 1 0>,
				<DCC_READ 0x03D8E014 1 0>,
				<DCC_READ 0x03D8E018 1 0>,
				<DCC_READ 0x03D8E01C 1 0>,
				<DCC_READ 0x03D8E020 1 0>,
				<DCC_READ 0x03D8E024 1 0>,
				<DCC_READ 0x03D8E028 1 0>,
				<DCC_READ 0x03D8E02C 1 0>,
				<DCC_READ 0x03D8E030 1 0>,
				<DCC_READ 0x03D8E034 1 0>,
				<DCC_READ 0x03D8E038 1 0>,
				<DCC_READ 0x03D8E03C 1 0>,
				<DCC_READ 0x03D8E040 1 0>,
				<DCC_READ 0x03D8E044 1 0>,
				<DCC_READ 0x03D8E048 1 0>,
				<DCC_READ 0x03D8E04C 1 0>,
				<DCC_READ 0x03D8E050 1 0>,
				<DCC_READ 0x03D8E054 1 0>,
				<DCC_READ 0x03D8E058 1 0>,
				<DCC_READ 0x03D8E05C 1 0>,
				<DCC_READ 0x03D8E060 1 0>,
				<DCC_READ 0x03D8E064 1 0>,
				<DCC_READ 0x03D8E068 1 0>,
				<DCC_READ 0x03D8E06C 1 0>,
				<DCC_READ 0x03D8E070 1 0>,
				<DCC_READ 0x03D8E074 1 0>,
				<DCC_READ 0x03D8E078 1 0>,
				<DCC_READ 0x03D8E07C 1 0>,
				<DCC_READ 0x03D8E080 1 0>,
				<DCC_READ 0x03D8E084 1 0>,
				<DCC_READ 0x03D8E088 1 0>,
				<DCC_READ 0x03D8E090 1 0>,
				<DCC_READ 0x03D8E094 1 0>,
				<DCC_READ 0x03D8E098 1 0>,
				<DCC_READ 0x03D8E0A0 1 0>,
				<DCC_READ 0x03D8E0A4 1 0>,
				<DCC_READ 0x03D8E0A8 1 0>,
				<DCC_READ 0x03D8E0B0 1 0>,
				<DCC_READ 0x03D8E0B4 1 0>,
				<DCC_READ 0x03D8E0B8 1 0>,
				<DCC_READ 0x03D8E0C0 1 0>,
				<DCC_READ 0x03D8E0C4 1 0>,
				<DCC_READ 0x03D8E0C8 1 0>,
				<DCC_READ 0x03D8E0D0 1 0>,
				<DCC_READ 0x03D8E0D4 1 0>,
				<DCC_READ 0x03D8E0D8 1 0>,
				<DCC_READ 0x03D8E0E0 1 0>,
				<DCC_READ 0x03D8E0E4 1 0>,
				<DCC_READ 0x03D8E0E8 1 0>,
				<DCC_READ 0x03D8E0F0 1 0>,
				<DCC_READ 0x03D8E0F4 1 0>,
				<DCC_READ 0x03D8E0F8 1 0>,
				<DCC_READ 0x03D8E100 1 0>,
				<DCC_READ 0x03D8E104 1 0>,
				<DCC_READ 0x03D8E108 1 0>,
				<DCC_READ 0x03D8E10C 1 0>,
				<DCC_READ 0x03D8E110 1 0>,
				<DCC_READ 0x03D8E114 1 0>,
				<DCC_READ 0x03D8E118 1 0>,
				<DCC_READ 0x03D8E11C 1 0>,
				<DCC_READ 0x03D8EC00 1 0>,
				<DCC_READ 0x03D8EC04 1 0>,
				<DCC_READ 0x03D8EC08 1 0>,
				<DCC_READ 0x03D8EC0C 1 0>,
				<DCC_READ 0x03D8EC10 1 0>,
				<DCC_READ 0x03D8EC14 1 0>,
				<DCC_READ 0x03D8EC18 1 0>,
				<DCC_READ 0x03D8EC1C 1 0>,
				<DCC_READ 0x03D8EC20 1 0>,
				<DCC_READ 0x03D8EC24 1 0>,
				<DCC_READ 0x03D8EC28 1 0>,
				<DCC_READ 0x03D8EC2C 1 0>,
				<DCC_READ 0x03D8EC30 1 0>,
				<DCC_READ 0x03D8EC34 1 0>,
				<DCC_READ 0x03D8EC38 1 0>,
				<DCC_READ 0x03D8EC40 1 0>,
				<DCC_READ 0x03D8EC44 1 0>,
				<DCC_READ 0x03D8EC48 1 0>,
				<DCC_READ 0x03D8EC4C 1 0>,
				<DCC_READ 0x03D8EC50 1 0>,
				<DCC_READ 0x03D8EC54 1 0>,
				<DCC_READ 0x03D8EC58 1 0>,
				<DCC_READ 0x03D8ECA0 1 0>,
				<DCC_READ 0x03D8ECC0 1 0>,
				<DCC_READ 0x03D8EFF0 1 0>,
				<DCC_READ 0x03D8EFF4 1 0>,
				<DCC_READ 0x03D8F000 1 0>,
				<DCC_READ 0x03D7D000 1 0>,
				<DCC_READ 0x03D7D004 1 0>,
				<DCC_READ 0x03D7D008 1 0>,
				<DCC_READ 0x03D7D00C 1 0>,
				<DCC_READ 0x03D7D010 1 0>,
				<DCC_READ 0x03D7D014 1 0>,
				<DCC_READ 0x03D7D018 1 0>,
				<DCC_READ 0x03D7D01C 1 0>,
				<DCC_READ 0x03D7D020 1 0>,
				<DCC_READ 0x03D7D024 1 0>,
				<DCC_READ 0x03D7D028 1 0>,
				<DCC_READ 0x03D7D02C 1 0>,
				<DCC_READ 0x03D7D03C 1 0>,
				<DCC_READ 0x03D7D040 1 0>,
				<DCC_READ 0x03D7D044 1 0>,
				<DCC_READ 0x03D7D048 1 0>,
				<DCC_READ 0x03D7D400 1 0>,
				<DCC_READ 0x03D7D41C 1 0>,
				<DCC_READ 0x03D7D420 1 0>,
				<DCC_READ 0x03D7D424 1 0>,
				<DCC_READ 0x03D7D428 1 0>,
				<DCC_READ 0x03D7D42C 1 0>,
				<DCC_READ 0x03D7DC00 1 0>,
				<DCC_READ 0x03D7DC04 1 0>,
				<DCC_READ 0x03D7DC10 1 0>,
				<DCC_READ 0x03D7DC14 1 0>,
				<DCC_READ 0x03D7DC18 1 0>,
				<DCC_READ 0x03D7DC20 1 0>,
				<DCC_READ 0x03D7DC24 1 0>,
				<DCC_READ 0x03D7DC30 1 0>,
				<DCC_READ 0x03D7DC34 1 0>,
				<DCC_READ 0x03D7DC40 1 0>,
				<DCC_READ 0x03D7DC44 1 0>,
				<DCC_READ 0x03D7DC4C 1 0>,
				<DCC_READ 0x03D7DC50 1 0>,
				<DCC_READ 0x03D7DC54 1 0>,
				<DCC_READ 0x03D7DC58 1 0>,
				<DCC_READ 0x03D7DC60 1 0>,
				<DCC_READ 0x03D7DC64 1 0>,
				<DCC_READ 0x03D7DC68 1 0>,
				<DCC_READ 0x03D7DC6C 1 0>,
				<DCC_READ 0x03D7DC70 1 0>,
				<DCC_READ 0x03D7DC74 1 0>,
				<DCC_READ 0x03D7DC80 1 0>,
				<DCC_READ 0x03D7DC84 1 0>,
				<DCC_READ 0x03D7DC88 1 0>,
				<DCC_READ 0x03D7DC8C 1 0>,
				<DCC_READ 0x03D7DC90 1 0>,
				<DCC_READ 0x03D7DCA4 1 0>,
				<DCC_READ 0x03D7DCC0 1 0>,
				<DCC_READ 0x03D7DCC4 1 0>,
				<DCC_READ 0x03D7DCC8 1 0>,
				<DCC_READ 0x03D7DCCC 1 0>,
				<DCC_READ 0x03D7DCD0 1 0>,
				<DCC_READ 0x03D7DCD4 1 0>,
				<DCC_READ 0x03D7DCD8 1 0>,
				<DCC_READ 0x03D7DCDC 1 0>,
				<DCC_READ 0x03D7DCE0 1 0>,
				<DCC_READ 0x03D7DCE4 1 0>,
				<DCC_READ 0x03D7DCE8 1 0>,
				<DCC_READ 0x03D7DCEC 1 0>,
				<DCC_READ 0x03D7DCF0 1 0>,
				<DCC_READ 0x03D7DCF4 1 0>,
				<DCC_READ 0x03D7DCF8 1 0>,
				<DCC_READ 0x03D7DCFC 1 0>,
				<DCC_READ 0x03D7DD00 1 0>,
				<DCC_READ 0x03D7DD04 1 0>,
				<DCC_READ 0x03D7DD08 1 0>,
				<DCC_READ 0x03D7DD0C 1 0>,
				<DCC_READ 0x03D7DD10 1 0>,
				<DCC_READ 0x03D7DD14 1 0>,
				<DCC_READ 0x03D7DD18 1 0>,
				<DCC_READ 0x03D7DD1C 1 0>,
				<DCC_READ 0x03D7DD40 1 0>,
				<DCC_READ 0x03D7DD44 1 0>,
				<DCC_READ 0x03D7DD48 1 0>,
				<DCC_READ 0x03D7DD4C 1 0>,
				<DCC_READ 0x03D7DD50 1 0>,
				<DCC_READ 0x03D7DD54 1 0>,
				<DCC_READ 0x03D7DD58 1 0>,
				<DCC_READ 0x03D7DD60 1 0>,
				<DCC_READ 0x03D7DD64 1 0>,
				<DCC_READ 0x03D7DD70 1 0>,
				<DCC_READ 0x03D7DD80 1 0>,
				<DCC_READ 0x03D7DD84 1 0>,
				<DCC_READ 0x03D7DD90 1 0>,
				<DCC_READ 0x03D7DD94 1 0>,
				<DCC_READ 0x03D7DD98 1 0>,
				<DCC_READ 0x03D7DD9C 1 0>,
				<DCC_READ 0x03D7DDA0 1 0>,
				<DCC_READ 0x03D7DDA4 1 0>,
				<DCC_READ 0x03D7DDA8 1 0>,
				<DCC_READ 0x03D7DDAC 1 0>,
				<DCC_READ 0x03D7DDC0 1 0>,
				<DCC_READ 0x03D7DDC4 1 0>,
				<DCC_READ 0x03D7DDC8 1 0>,
				<DCC_READ 0x03D7DDCC 1 0>,
				<DCC_READ 0x03D7DDD0 1 0>,
				<DCC_READ 0x03D7DDD4 1 0>,
				<DCC_READ 0x03D7DE00 1 0>,
				<DCC_READ 0x03D7DE04 1 0>,
				<DCC_READ 0x03D7DE08 1 0>,
				<DCC_READ 0x03D7DE0C 1 0>,
				<DCC_READ 0x03D7DE10 1 0>,
				<DCC_READ 0x03D7DE14 1 0>,
				<DCC_READ 0x03D7DE40 1 0>,
				<DCC_READ 0x03D7DE44 1 0>,
				<DCC_READ 0x03D7DE48 1 0>,
				<DCC_READ 0x03D7DE4C 1 0>,
				<DCC_READ 0x03D7DE50 1 0>,
				<DCC_READ 0x03D7DE54 1 0>,
				<DCC_READ 0x03D7DE58 1 0>,
				<DCC_READ 0x03D7DE5C 1 0>,
				<DCC_READ 0x03D7DE60 1 0>,
				<DCC_READ 0x03D7DE80 1 0>,
				<DCC_READ 0x03D7DE84 1 0>,
				<DCC_READ 0x03D7DE88 1 0>,
				<DCC_READ 0x03D7DE8C 1 0>,
				<DCC_READ 0x03D7DE90 1 0>,
				<DCC_READ 0x03D7DE94 1 0>,
				<DCC_READ 0x03D7DE98 1 0>,
				<DCC_READ 0x03D7DE9C 1 0>,
				<DCC_READ 0x03D7DEA0 1 0>,
				<DCC_READ 0x03D7DEC0 1 0>,
				<DCC_READ 0x03D7DEC4 1 0>,
				<DCC_READ 0x03D7DEC8 1 0>,
				<DCC_READ 0x03D7DECC 1 0>,
				<DCC_READ 0x03D7E000 1 0>,
				<DCC_READ 0x03D7E004 1 0>,
				<DCC_READ 0x03D7E008 1 0>,
				<DCC_READ 0x03D7E00C 1 0>,
				<DCC_READ 0x03D7E010 1 0>,
				<DCC_READ 0x03D7E01C 1 0>,
				<DCC_READ 0x03D7E020 1 0>,
				<DCC_READ 0x03D7E02C 1 0>,
				<DCC_READ 0x03D7E030 1 0>,
				<DCC_READ 0x03D7E03C 1 0>,
				<DCC_READ 0x03D7E040 1 0>,
				<DCC_READ 0x03D7E044 1 0>,
				<DCC_READ 0x03D7E048 1 0>,
				<DCC_READ 0x03D7E04C 1 0>,
				<DCC_READ 0x03D7E050 1 0>,
				<DCC_READ 0x03D7E054 1 0>,
				<DCC_READ 0x03D7E058 1 0>,
				<DCC_READ 0x03D7E05C 1 0>,
				<DCC_READ 0x03D7E060 1 0>,
				<DCC_READ 0x03D7E064 1 0>,
				<DCC_READ 0x03D7E068 1 0>,
				<DCC_READ 0x03D7E06C 1 0>,
				<DCC_READ 0x03D7E070 1 0>,
				<DCC_READ 0x03D7E090 1 0>,
				<DCC_READ 0x03D7E094 1 0>,
				<DCC_READ 0x03D7E098 1 0>,
				<DCC_READ 0x03D7E09C 1 0>,
				<DCC_READ 0x03D7E0A0 1 0>,
				<DCC_READ 0x03D7E0A4 1 0>,
				<DCC_READ 0x03D7E0A8 1 0>,
				<DCC_READ 0x03D7E0B4 1 0>,
				<DCC_READ 0x03D7E0B8 1 0>,
				<DCC_READ 0x03D7E0BC 1 0>,
				<DCC_READ 0x03D7E0C0 1 0>,
				<DCC_READ 0x03D7E100 1 0>,
				<DCC_READ 0x03D7E104 1 0>,
				<DCC_READ 0x03D7E108 1 0>,
				<DCC_READ 0x03D7E10C 1 0>,
				<DCC_READ 0x03D7E110 1 0>,
				<DCC_READ 0x03D7E114 1 0>,
				<DCC_READ 0x03D7E118 1 0>,
				<DCC_READ 0x03D7E11C 1 0>,
				<DCC_READ 0x03D7E120 1 0>,
				<DCC_READ 0x03D7E124 1 0>,
				<DCC_READ 0x03D7E128 1 0>,
				<DCC_READ 0x03D7E12C 1 0>,
				<DCC_READ 0x03D7E130 1 0>,
				<DCC_READ 0x03D7E134 1 0>,
				<DCC_READ 0x03D7E138 1 0>,
				<DCC_READ 0x03D7E13C 1 0>,
				<DCC_READ 0x03D7E140 1 0>,
				<DCC_READ 0x03D7E144 1 0>,
				<DCC_READ 0x03D7E148 1 0>,
				<DCC_READ 0x03D7E14C 1 0>,
				<DCC_READ 0x03D7E180 1 0>,
				<DCC_READ 0x03D7E188 1 0>,
				<DCC_READ 0x03D7E18C 1 0>,
				<DCC_READ 0x03D7E190 1 0>,
				<DCC_READ 0x03D7E194 1 0>,
				<DCC_READ 0x03D7E198 1 0>,
				<DCC_READ 0x03D7E1A0 1 0>,
				<DCC_READ 0x03D7E1A4 1 0>,
				<DCC_READ 0x03D7E1C0 1 0>,
				<DCC_READ 0x03D7E1C4 1 0>,
				<DCC_READ 0x03D7E1C8 1 0>,
				<DCC_READ 0x03D7E1CC 1 0>,
				<DCC_READ 0x03D7E1D0 1 0>,
				<DCC_READ 0x03D7E1D4 1 0>,
				<DCC_READ 0x03D7E1D8 1 0>,
				<DCC_READ 0x03D7E1DC 1 0>,
				<DCC_READ 0x03D7E1E0 1 0>,
				<DCC_READ 0x03D7E1E4 1 0>,
				<DCC_READ 0x03D7E1FC 1 0>,
				<DCC_READ 0x03D7E200 1 0>,
				<DCC_READ 0x03D7E204 1 0>,
				<DCC_READ 0x03D7E240 1 0>,
				<DCC_READ 0x03D7E244 1 0>,
				<DCC_READ 0x03D7E248 1 0>,
				<DCC_READ 0x03D7E24C 1 0>,
				<DCC_READ 0x03D7E250 1 0>,
				<DCC_READ 0x03D7E254 1 0>,
				<DCC_READ 0x03D7E258 1 0>,
				<DCC_READ 0x03D7E280 1 0>,
				<DCC_READ 0x03D7E284 1 0>,
				<DCC_READ 0x03D7E288 1 0>,
				<DCC_READ 0x03D7E290 1 0>,
				<DCC_READ 0x03D7E294 1 0>,
				<DCC_READ 0x03D7E298 1 0>,
				<DCC_READ 0x03D7E29C 1 0>,
				<DCC_READ 0x03D7E2A0 1 0>,
				<DCC_READ 0x03D7E2A4 1 0>,
				<DCC_READ 0x03D7E2A8 1 0>,
				<DCC_READ 0x03D7E2AC 1 0>,
				<DCC_READ 0x03D7E2B0 1 0>,
				<DCC_READ 0x03D7E2B4 1 0>,
				<DCC_READ 0x03D7E2B8 1 0>,
				<DCC_READ 0x03D7E2BC 1 0>,
				<DCC_READ 0x03D7E2E0 1 0>,
				<DCC_READ 0x03D7E2E4 1 0>,
				<DCC_READ 0x03D7E300 1 0>,
				<DCC_READ 0x03D7E304 1 0>,
				<DCC_READ 0x03D7E30C 1 0>,
				<DCC_READ 0x03D7E310 1 0>,
				<DCC_READ 0x03D7E340 1 0>,
				<DCC_READ 0x03D7E3B0 1 0>,
				<DCC_READ 0x03D7E3C0 1 0>,
				<DCC_READ 0x03D7E3C4 1 0>,
				<DCC_READ 0x03D7E440 1 0>,
				<DCC_READ 0x03D7E444 1 0>,
				<DCC_READ 0x03D7E448 1 0>,
				<DCC_READ 0x03D7E44C 1 0>,
				<DCC_READ 0x03D7E450 1 0>,
				<DCC_READ 0x03D7E454 1 0>,
				<DCC_READ 0x03D7E458 1 0>,
				<DCC_READ 0x03D7E45C 1 0>,
				<DCC_READ 0x03D7E480 1 0>,
				<DCC_READ 0x03D7E484 1 0>,
				<DCC_READ 0x03D7E488 1 0>,
				<DCC_READ 0x03D7E490 1 0>,
				<DCC_READ 0x03D7E494 1 0>,
				<DCC_READ 0x03D7E498 1 0>,
				<DCC_READ 0x03D7E4A0 1 0>,
				<DCC_READ 0x03D7E4A4 1 0>,
				<DCC_READ 0x03D7E4A8 1 0>,
				<DCC_READ 0x03D7E4B0 1 0>,
				<DCC_READ 0x03D7E4B4 1 0>,
				<DCC_READ 0x03D7E4B8 1 0>,
				<DCC_READ 0x03D7E508 1 0>,
				<DCC_READ 0x03D7E50C 1 0>,
				<DCC_READ 0x03D7E510 1 0>,
				<DCC_READ 0x03D7E520 1 0>,
				<DCC_READ 0x03D7E524 1 0>,
				<DCC_READ 0x03D7E528 1 0>,
				<DCC_READ 0x03D7E53C 1 0>,
				<DCC_READ 0x03D7E540 1 0>,
				<DCC_READ 0x03D7E544 1 0>,
				<DCC_READ 0x03D7E550 1 0>,
				<DCC_READ 0x03D7E554 1 0>,
				<DCC_READ 0x03D7E574 1 0>,
				<DCC_READ 0x03D7E588 1 0>,
				<DCC_READ 0x03D7E58C 1 0>,
				<DCC_READ 0x03D7E590 1 0>,
				<DCC_READ 0x03D7E594 1 0>,
				<DCC_READ 0x03D7E598 1 0>,
				<DCC_READ 0x03D7E59C 1 0>,
				<DCC_READ 0x03D7E5A0 1 0>,
				<DCC_READ 0x03D7E5A4 1 0>,
				<DCC_READ 0x03D7E5A8 1 0>,
				<DCC_READ 0x03D7E5AC 1 0>,
				<DCC_READ 0x03D7E5C0 1 0>,
				<DCC_READ 0x03D7E5C4 1 0>,
				<DCC_READ 0x03D7E5CC 1 0>,
				<DCC_READ 0x03D7E5D0 1 0>,
				<DCC_READ 0x03D7E5D4 1 0>,
				<DCC_READ 0x03D7E5D8 1 0>,
				<DCC_READ 0x03D7E5DC 1 0>,
				<DCC_READ 0x03D7E5F0 1 0>,
				<DCC_READ 0x03D7E600 1 0>,
				<DCC_READ 0x03D7E604 1 0>,
				<DCC_READ 0x03D7E610 1 0>,
				<DCC_READ 0x03D7E614 1 0>,
				<DCC_READ 0x03D7E618 1 0>,
				<DCC_READ 0x03D7E640 1 0>,
				<DCC_READ 0x03D7E644 1 0>,
				<DCC_READ 0x03D7E648 1 0>,
				<DCC_READ 0x03D7E64C 1 0>,
				<DCC_READ 0x03D7E650 1 0>,
				<DCC_READ 0x03D7E654 1 0>,
				<DCC_READ 0x03D7E658 1 0>,
				<DCC_READ 0x03D7E65C 1 0>,
				<DCC_READ 0x03D7E660 1 0>,
				<DCC_READ 0x03D7E664 1 0>,
				<DCC_READ 0x03D7E668 1 0>,
				<DCC_READ 0x03D7E66C 1 0>,
				<DCC_READ 0x03D7E670 1 0>,
				<DCC_READ 0x03D7E674 1 0>,
				<DCC_READ 0x03D7E678 1 0>,
				<DCC_READ 0x03D7E714 1 0>,
				<DCC_READ 0x03D7E718 1 0>,
				<DCC_READ 0x03D7E71C 1 0>,
				<DCC_READ 0x03D7E720 1 0>,
				<DCC_READ 0x03D7E724 1 0>,
				<DCC_READ 0x03D7E728 1 0>,
				<DCC_READ 0x03D7E72C 1 0>,
				<DCC_READ 0x03D7E730 1 0>,
				<DCC_READ 0x03D7E734 1 0>,
				<DCC_READ 0x03D7E738 1 0>,
				<DCC_READ 0x03D7E73C 1 0>,
				<DCC_READ 0x03D7E740 1 0>,
				<DCC_READ 0x03D7E744 1 0>,
				<DCC_READ 0x03D7E748 1 0>,
				<DCC_READ 0x03D7E74C 1 0>,
				<DCC_READ 0x03D7E750 1 0>,
				<DCC_READ 0x03D7E7C0 1 0>,
				<DCC_READ 0x03D7E7C4 1 0>,
				<DCC_READ 0x03D7E7E0 1 0>,
				<DCC_READ 0x03D7E7E4 1 0>,
				<DCC_READ 0x03D7E7E8 1 0>,
				<DCC_READ 0x03D7E7F0 1 0>,
				<DCC_READ 0x03D7E800 1 0>,
				<DCC_READ 0x03D7E804 1 0>,
				<DCC_READ 0x03D7E808 1 0>,
				<DCC_READ 0x03D7E80C 1 0>,
				<DCC_READ 0x03D80000 1 0>,
				<DCC_READ 0x03D80004 1 0>,
				<DCC_READ 0x03D80008 1 0>,
				<DCC_READ 0x03D8000C 1 0>,
				<DCC_READ 0x03D80010 1 0>,
				<DCC_READ 0x03D80014 1 0>,
				<DCC_READ 0x03D80018 1 0>,
				<DCC_READ 0x03D8001C 1 0>,
				<DCC_READ 0x03D80020 1 0>,
				<DCC_READ 0x03D80024 1 0>,
				<DCC_READ 0x03D80028 1 0>,
				<DCC_READ 0x03D8002C 1 0>,
				<DCC_READ 0x03D80030 1 0>,
				<DCC_READ 0x03D80034 1 0>,
				<DCC_READ 0x03D80038 1 0>,
				<DCC_READ 0x03D8003C 1 0>,
				<DCC_READ 0x03D80040 1 0>,
				<DCC_READ 0x03D80044 1 0>,
				<DCC_READ 0x03D80048 1 0>,
				<DCC_READ 0x03D8004C 1 0>,
				<DCC_READ 0x03D80060 1 0>,
				<DCC_READ 0x03D80064 1 0>,
				<DCC_READ 0x03D80068 1 0>,
				<DCC_READ 0x03D80080 1 0>,
				<DCC_READ 0x03D80084 1 0>,
				<DCC_READ 0x03D80090 1 0>,
				<DCC_READ 0x03D80094 1 0>,
				<DCC_READ 0x03D800A8 1 0>,
				<DCC_READ 0x03D800AC 1 0>,
				<DCC_READ 0x03D800B0 1 0>,
				<DCC_READ 0x03D800C0 1 0>,
				<DCC_READ 0x03D800C4 1 0>,
				<DCC_READ 0x03D800D0 1 0>,
				<DCC_READ 0x03D800D4 1 0>,
				<DCC_READ 0x03D800D8 1 0>,
				<DCC_READ 0x03D81000 1 0>,
				<DCC_READ 0x03D81010 1 0>,
				<DCC_READ 0x03D81020 1 0>,
				<DCC_READ 0x03D81024 1 0>,
				<DCC_READ 0x03D81028 1 0>,
				<DCC_READ 0x03D8102C 1 0>,
				<DCC_READ 0x03D81030 1 0>,
				<DCC_READ 0x03D81034 1 0>,
				<DCC_READ 0x03D81038 1 0>,
				<DCC_READ 0x03D8103C 1 0>,
				<DCC_READ 0x03D81040 1 0>,
				<DCC_READ 0x03D81044 1 0>,
				<DCC_READ 0x03D81048 1 0>,
				<DCC_READ 0x03D8104C 1 0>,
				<DCC_READ 0x03D69000 1 0>,
				<DCC_READ 0x03D69004 1 0>,
				<DCC_READ 0x03D69008 1 0>,
				<DCC_READ 0x03D6900C 1 0>,
				<DCC_READ 0x03D69010 1 0>,
				<DCC_READ 0x03D69014 1 0>,
				<DCC_READ 0x03D69018 1 0>,
				<DCC_READ 0x03D6901C 1 0>,
				<DCC_READ 0x03D69020 1 0>,
				<DCC_READ 0x03D69024 1 0>,
				<DCC_READ 0x03D69028 1 0>,
				<DCC_READ 0x03D6902C 1 0>,
				<DCC_READ 0x03D69030 1 0>,
				<DCC_READ 0x03D69034 1 0>,
				<DCC_READ 0x03D69038 1 0>,
				<DCC_READ 0x03D6903C 1 0>,
				<DCC_READ 0x03D69040 1 0>,
				<DCC_READ 0x03D69044 1 0>,
				<DCC_READ 0x03D69048 1 0>,
				<DCC_READ 0x03D6904C 1 0>,
				<DCC_READ 0x03D69050 1 0>,
				<DCC_READ 0x03D69054 1 0>,
				<DCC_READ 0x03D69058 1 0>,
				<DCC_READ 0x03D6905C 1 0>,
				<DCC_READ 0x03D69060 1 0>,
				<DCC_READ 0x03D69064 1 0>,
				<DCC_READ 0x03D69068 1 0>,
				<DCC_READ 0x03D6906C 1 0>,
				<DCC_READ 0x03D69070 1 0>,
				<DCC_READ 0x03D69074 1 0>,
				<DCC_READ 0x03D69078 1 0>,
				<DCC_READ 0x03D6907C 1 0>,
				<DCC_READ 0x03D69100 1 0>,
				<DCC_READ 0x03D69104 1 0>,
				<DCC_READ 0x03D69108 1 0>,
				<DCC_READ 0x03D6910C 1 0>,
				<DCC_READ 0x03D69110 1 0>,
				<DCC_READ 0x03D69114 1 0>,
				<DCC_READ 0x03D69118 1 0>,
				<DCC_READ 0x03D6911C 1 0>,
				<DCC_READ 0x03D69120 1 0>,
				<DCC_READ 0x03D69124 1 0>,
				<DCC_READ 0x03D69128 1 0>,
				<DCC_READ 0x03D6912C 1 0>,
				<DCC_READ 0x03D69130 1 0>,
				<DCC_READ 0x03D69134 1 0>,
				<DCC_READ 0x03D69138 1 0>,
				<DCC_READ 0x03D6913C 1 0>,
				<DCC_READ 0x03D69140 1 0>,
				<DCC_READ 0x03D69144 1 0>,
				<DCC_READ 0x03D69148 1 0>,
				<DCC_READ 0x03D6914C 1 0>,
				<DCC_READ 0x03D69150 1 0>,
				<DCC_READ 0x03D69154 1 0>,
				<DCC_READ 0x03D69158 1 0>,
				<DCC_READ 0x03D6915C 1 0>,
				<DCC_READ 0x03D69160 1 0>,
				<DCC_READ 0x03D69164 1 0>,
				<DCC_READ 0x03D69168 1 0>,
				<DCC_READ 0x03D6916C 1 0>,
				<DCC_READ 0x03D69170 1 0>,
				<DCC_READ 0x03D69174 1 0>,
				<DCC_READ 0x03D69178 1 0>,
				<DCC_READ 0x03D6917C 1 0>,
				<DCC_READ 0x03D69200 1 0>,
				<DCC_READ 0x03D69204 1 0>,
				<DCC_READ 0x03D69208 1 0>,
				<DCC_READ 0x03D6920C 1 0>,
				<DCC_READ 0x03D69210 1 0>,
				<DCC_READ 0x03D69214 1 0>,
				<DCC_READ 0x03D69218 1 0>,
				<DCC_READ 0x03D6921C 1 0>,
				<DCC_READ 0x03D69220 1 0>,
				<DCC_READ 0x03D69224 1 0>,
				<DCC_READ 0x03D69228 1 0>,
				<DCC_READ 0x03D6922C 1 0>,
				<DCC_READ 0x03D69230 1 0>,
				<DCC_READ 0x03D69234 1 0>,
				<DCC_READ 0x03D69238 1 0>,
				<DCC_READ 0x03D6923C 1 0>,
				<DCC_READ 0x03D69240 1 0>,
				<DCC_READ 0x03D69244 1 0>,
				<DCC_READ 0x03D69248 1 0>,
				<DCC_READ 0x03D6924C 1 0>,
				<DCC_READ 0x03D69250 1 0>,
				<DCC_READ 0x03D69254 1 0>,
				<DCC_READ 0x03D69258 1 0>,
				<DCC_READ 0x03D6925C 1 0>,
				<DCC_READ 0x03D69260 1 0>,
				<DCC_READ 0x03D69264 1 0>,
				<DCC_READ 0x03D69268 1 0>,
				<DCC_READ 0x03D6926C 1 0>,
				<DCC_READ 0x03D69270 1 0>,
				<DCC_READ 0x03D69274 1 0>,
				<DCC_READ 0x03D69278 1 0>,
				<DCC_READ 0x03D6927C 1 0>,
				<DCC_READ 0x03D69300 1 0>,
				<DCC_READ 0x03D69304 1 0>,
				<DCC_READ 0x03D69308 1 0>,
				<DCC_READ 0x03D6930C 1 0>,
				<DCC_READ 0x03D69310 1 0>,
				<DCC_READ 0x03D69314 1 0>,
				<DCC_READ 0x03D69318 1 0>,
				<DCC_READ 0x03D6931C 1 0>,
				<DCC_READ 0x03D69320 1 0>,
				<DCC_READ 0x03D69324 1 0>,
				<DCC_READ 0x03D69328 1 0>,
				<DCC_READ 0x03D6932C 1 0>,
				<DCC_READ 0x03D69330 1 0>,
				<DCC_READ 0x03D69334 1 0>,
				<DCC_READ 0x03D69338 1 0>,
				<DCC_READ 0x03D6933C 1 0>,
				<DCC_READ 0x03D69340 1 0>,
				<DCC_READ 0x03D69344 1 0>,
				<DCC_READ 0x03D69348 1 0>,
				<DCC_READ 0x03D6934C 1 0>,
				<DCC_READ 0x03D69350 1 0>,
				<DCC_READ 0x03D69354 1 0>,
				<DCC_READ 0x03D69358 1 0>,
				<DCC_READ 0x03D6935C 1 0>,
				<DCC_READ 0x03D69360 1 0>,
				<DCC_READ 0x03D69364 1 0>,
				<DCC_READ 0x03D69368 1 0>,
				<DCC_READ 0x03D6936C 1 0>,
				<DCC_READ 0x03D69370 1 0>,
				<DCC_READ 0x03D69374 1 0>,
				<DCC_READ 0x03D69378 1 0>,
				<DCC_READ 0x03D6937C 1 0>,
				<DCC_READ 0x03D69400 1 0>,
				<DCC_READ 0x03D69404 1 0>,
				<DCC_READ 0x03D69408 1 0>,
				<DCC_READ 0x03D6940C 1 0>,
				<DCC_READ 0x03D69410 1 0>,
				<DCC_READ 0x03D69414 1 0>,
				<DCC_READ 0x03D69418 1 0>,
				<DCC_READ 0x03D6941C 1 0>,
				<DCC_READ 0x03D69420 1 0>,
				<DCC_READ 0x03D69424 1 0>,
				<DCC_READ 0x03D69428 1 0>,
				<DCC_READ 0x03D6942C 1 0>,
				<DCC_READ 0x03D69430 1 0>,
				<DCC_READ 0x03D69434 1 0>,
				<DCC_READ 0x03D69438 1 0>,
				<DCC_READ 0x03D6943C 1 0>,
				<DCC_READ 0x03D69440 1 0>,
				<DCC_READ 0x03D69444 1 0>,
				<DCC_READ 0x03D69448 1 0>,
				<DCC_READ 0x03D6944C 1 0>,
				<DCC_READ 0x03D69450 1 0>,
				<DCC_READ 0x03D69454 1 0>,
				<DCC_READ 0x03D69458 1 0>,
				<DCC_READ 0x03D6945C 1 0>,
				<DCC_READ 0x03D69460 1 0>,
				<DCC_READ 0x03D69464 1 0>,
				<DCC_READ 0x03D69468 1 0>,
				<DCC_READ 0x03D6946C 1 0>,
				<DCC_READ 0x03D69470 1 0>,
				<DCC_READ 0x03D69474 1 0>,
				<DCC_READ 0x03D69478 1 0>,
				<DCC_READ 0x03D6947C 1 0>,
				<DCC_READ 0x03D69500 1 0>,
				<DCC_READ 0x03D69504 1 0>,
				<DCC_READ 0x03D69508 1 0>,
				<DCC_READ 0x03D6950C 1 0>,
				<DCC_READ 0x03D69510 1 0>,
				<DCC_READ 0x03D69514 1 0>,
				<DCC_READ 0x03D69518 1 0>,
				<DCC_READ 0x03D6951C 1 0>,
				<DCC_READ 0x03D69520 1 0>,
				<DCC_READ 0x03D69524 1 0>,
				<DCC_READ 0x03D69528 1 0>,
				<DCC_READ 0x03D6952C 1 0>,
				<DCC_READ 0x03D69530 1 0>,
				<DCC_READ 0x03D69534 1 0>,
				<DCC_READ 0x03D69538 1 0>,
				<DCC_READ 0x03D6953C 1 0>,
				<DCC_READ 0x03D69540 1 0>,
				<DCC_READ 0x03D69544 1 0>,
				<DCC_READ 0x03D69548 1 0>,
				<DCC_READ 0x03D6954C 1 0>,
				<DCC_READ 0x03D69550 1 0>,
				<DCC_READ 0x03D69554 1 0>,
				<DCC_READ 0x03D69558 1 0>,
				<DCC_READ 0x03D6955C 1 0>,
				<DCC_READ 0x03D69560 1 0>,
				<DCC_READ 0x03D69564 1 0>,
				<DCC_READ 0x03D69568 1 0>,
				<DCC_READ 0x03D6956C 1 0>,
				<DCC_READ 0x03D69570 1 0>,
				<DCC_READ 0x03D69574 1 0>,
				<DCC_READ 0x03D69578 1 0>,
				<DCC_READ 0x03D6957C 1 0>,
				<DCC_READ 0x03D69600 1 0>,
				<DCC_READ 0x03D69604 1 0>,
				<DCC_READ 0x03D69608 1 0>,
				<DCC_READ 0x03D6960C 1 0>,
				<DCC_READ 0x03D69610 1 0>,
				<DCC_READ 0x03D69614 1 0>,
				<DCC_READ 0x03D69618 1 0>,
				<DCC_READ 0x03D6961C 1 0>,
				<DCC_READ 0x03D69620 1 0>,
				<DCC_READ 0x03D69624 1 0>,
				<DCC_READ 0x03D69628 1 0>,
				<DCC_READ 0x03D6962C 1 0>,
				<DCC_READ 0x03D69630 1 0>,
				<DCC_READ 0x03D69634 1 0>,
				<DCC_READ 0x03D69638 1 0>,
				<DCC_READ 0x03D6963C 1 0>,
				<DCC_READ 0x03D69640 1 0>,
				<DCC_READ 0x03D69644 1 0>,
				<DCC_READ 0x03D69648 1 0>,
				<DCC_READ 0x03D6964C 1 0>,
				<DCC_READ 0x03D69650 1 0>,
				<DCC_READ 0x03D69654 1 0>,
				<DCC_READ 0x03D69658 1 0>,
				<DCC_READ 0x03D6965C 1 0>,
				<DCC_READ 0x03D69660 1 0>,
				<DCC_READ 0x03D69664 1 0>,
				<DCC_READ 0x03D69668 1 0>,
				<DCC_READ 0x03D6966C 1 0>,
				<DCC_READ 0x03D69670 1 0>,
				<DCC_READ 0x03D69674 1 0>,
				<DCC_READ 0x03D69678 1 0>,
				<DCC_READ 0x03D6967C 1 0>,
				<DCC_READ 0x03D69800 1 0>,
				<DCC_READ 0x03D69804 1 0>,
				<DCC_READ 0x03D69808 1 0>,
				<DCC_READ 0x03D6980C 1 0>,
				<DCC_READ 0x03D69810 1 0>,
				<DCC_READ 0x03D69814 1 0>,
				<DCC_READ 0x03D69818 1 0>,
				<DCC_READ 0x03D6981C 1 0>,
				<DCC_READ 0x03D69820 1 0>,
				<DCC_READ 0x03D69824 1 0>,
				<DCC_READ 0x03D69828 1 0>,
				<DCC_READ 0x03D6982C 1 0>,
				<DCC_READ 0x03D69830 1 0>,
				<DCC_READ 0x03D69834 1 0>,
				<DCC_READ 0x03D69838 1 0>,
				<DCC_READ 0x03D6983C 1 0>,
				<DCC_READ 0x03D69840 1 0>,
				<DCC_READ 0x03D69844 1 0>,
				<DCC_READ 0x03D69848 1 0>,
				<DCC_READ 0x03D6984C 1 0>,
				<DCC_READ 0x03D69850 1 0>,
				<DCC_READ 0x03D69854 1 0>,
				<DCC_READ 0x03D69858 1 0>,
				<DCC_READ 0x03D6985C 1 0>,
				<DCC_READ 0x03D69860 1 0>,
				<DCC_READ 0x03D69864 1 0>,
				<DCC_READ 0x03D69868 1 0>,
				<DCC_READ 0x03D6986C 1 0>,
				<DCC_READ 0x03D69870 1 0>,
				<DCC_READ 0x03D69874 1 0>,
				<DCC_READ 0x03D69878 1 0>,
				<DCC_READ 0x03D6987C 1 0>,
				<DCC_READ 0x03D69900 1 0>,
				<DCC_READ 0x03D69904 1 0>,
				<DCC_READ 0x03D69908 1 0>,
				<DCC_READ 0x03D6990C 1 0>,
				<DCC_READ 0x03D69910 1 0>,
				<DCC_READ 0x03D69914 1 0>,
				<DCC_READ 0x03D69918 1 0>,
				<DCC_READ 0x03D6991C 1 0>,
				<DCC_READ 0x03D69920 1 0>,
				<DCC_READ 0x03D69924 1 0>,
				<DCC_READ 0x03D69928 1 0>,
				<DCC_READ 0x03D6992C 1 0>,
				<DCC_READ 0x03D69930 1 0>,
				<DCC_READ 0x03D69934 1 0>,
				<DCC_READ 0x03D69938 1 0>,
				<DCC_READ 0x03D6993C 1 0>,
				<DCC_READ 0x03D69940 1 0>,
				<DCC_READ 0x03D69944 1 0>,
				<DCC_READ 0x03D69948 1 0>,
				<DCC_READ 0x03D6994C 1 0>,
				<DCC_READ 0x03D69950 1 0>,
				<DCC_READ 0x03D69954 1 0>,
				<DCC_READ 0x03D69958 1 0>,
				<DCC_READ 0x03D6995C 1 0>,
				<DCC_READ 0x03D69960 1 0>,
				<DCC_READ 0x03D69964 1 0>,
				<DCC_READ 0x03D69968 1 0>,
				<DCC_READ 0x03D6996C 1 0>,
				<DCC_READ 0x03D69970 1 0>,
				<DCC_READ 0x03D69974 1 0>,
				<DCC_READ 0x03D69978 1 0>,
				<DCC_READ 0x03D6997C 1 0>,
				<DCC_READ 0x03D69E00 1 0>,
				<DCC_READ 0x03D69E04 1 0>,
				<DCC_READ 0x03D69E0C 1 0>,
				<DCC_READ 0x03D69E10 1 0>,
				<DCC_READ 0x03D69E14 1 0>,
				<DCC_READ 0x03D69E1C 1 0>,
				<DCC_READ 0x03D69E20 1 0>,
				<DCC_READ 0x03D69E24 1 0>,
				<DCC_READ 0x03D69E2C 1 0>,
				<DCC_READ 0x03D69E30 1 0>,
				<DCC_READ 0x03D69E34 1 0>,
				<DCC_READ 0x03D69E3C 1 0>,
				<DCC_READ 0x03D69E40 1 0>,
				<DCC_READ 0x03D69E44 1 0>,
				<DCC_READ 0x03D69E4C 1 0>,
				<DCC_READ 0x03D69E50 1 0>,
				<DCC_READ 0x03D69E54 1 0>,
				<DCC_READ 0x03D69E5C 1 0>,
				<DCC_READ 0x03D69E60 1 0>,
				<DCC_READ 0x03D69E64 1 0>,
				<DCC_READ 0x03D69E6C 1 0>,
				<DCC_READ 0x03D69E70 1 0>,
				<DCC_READ 0x03D69E74 1 0>,
				<DCC_READ 0x03D69E7C 1 0>,
				<DCC_READ 0x03D69E80 1 0>,
				<DCC_READ 0x03D69E84 1 0>,
				<DCC_READ 0x03D69E8C 1 0>,
				<DCC_READ 0x03D69EA0 1 0>,
				<DCC_READ 0x03D69EA4 1 0>,
				<DCC_READ 0x03D69EA8 1 0>,
				<DCC_READ 0x03D69EAC 1 0>,
				<DCC_READ 0x03D69EB0 1 0>,
				<DCC_READ 0x03D69EB4 1 0>,
				<DCC_READ 0x03D69EB8 1 0>,
				<DCC_READ 0x03D69EBC 1 0>,
				<DCC_READ 0x03D69EC0 1 0>,
				<DCC_READ 0x03D69EC4 1 0>,
				<DCC_READ 0x03D69EC8 1 0>,
				<DCC_READ 0x03D69ECC 1 0>,
				<DCC_READ 0x03D69ED0 1 0>,
				<DCC_READ 0x03D69ED4 1 0>,
				<DCC_READ 0x03D69ED8 1 0>,
				<DCC_READ 0x03D69EDC 1 0>,
				<DCC_READ 0x03D69EE0 1 0>,
				<DCC_READ 0x03D69EE4 1 0>,
				<DCC_READ 0x03D69F00 1 0>,
				<DCC_READ 0x03D69F04 1 0>,
				<DCC_READ 0x03D69F10 1 0>,
				<DCC_READ 0x03D69F14 1 0>,
				<DCC_READ 0x03D69F20 1 0>,
				<DCC_READ 0x03D69F24 1 0>,
				<DCC_READ 0x03D69F30 1 0>,
				<DCC_READ 0x03D69F34 1 0>,
				<DCC_READ 0x03D69F40 1 0>,
				<DCC_READ 0x03D69F44 1 0>,
				<DCC_READ 0x03D69F50 1 0>,
				<DCC_READ 0x03D69F54 1 0>,
				<DCC_READ 0x03D69F60 1 0>,
				<DCC_READ 0x03D69F64 1 0>,
				<DCC_READ 0x03D69F70 1 0>,
				<DCC_READ 0x03D69F74 1 0>,
				<DCC_READ 0x03D69F80 1 0>,
				<DCC_READ 0x03D69F84 1 0>,
				<DCC_READ 0x03D69FF0 1 0>,
				<DCC_READ 0x03D69FF4 1 0>,
				<DCC_READ 0x03D6A000 1 0>,
				<DCC_READ 0x03D6A004 1 0>,
				<DCC_READ 0x03D6A008 1 0>,
				<DCC_READ 0x03D6A00C 1 0>,
				<DCC_READ 0x03D6A010 1 0>,
				<DCC_READ 0x03D6A014 1 0>,
				<DCC_READ 0x03D6A018 1 0>,
				<DCC_READ 0x03D6A01C 1 0>,
				<DCC_READ 0x03D6A020 1 0>,
				<DCC_READ 0x03D6A058 1 0>,
				<DCC_READ 0x03D6A078 1 0>,
				<DCC_READ 0x03D6A098 1 0>,
				<DCC_READ 0x03D6A0B8 1 0>,
				<DCC_READ 0x03D6A0D8 1 0>,
				<DCC_READ 0x03D6A0F8 1 0>,
				<DCC_READ 0x03D6A118 1 0>,
				<DCC_READ 0x03D6A138 1 0>,
				<DCC_READ 0x03D6A158 1 0>,
				<DCC_READ 0x03D6A20C 1 0>,
				<DCC_READ 0x03D6A210 1 0>,
				<DCC_READ 0x03D6A240 1 0>,
				<DCC_READ 0x03D6A244 1 0>,
				<DCC_READ 0x03D6A248 1 0>,
				<DCC_READ 0x03D6A24C 1 0>,
				<DCC_READ 0x03D6A250 1 0>,
				<DCC_READ 0x03D6A254 1 0>,
				<DCC_READ 0x03D6A258 1 0>,
				<DCC_READ 0x03D6A25C 1 0>,
				<DCC_READ 0x03D6A260 1 0>,
				<DCC_READ 0x03D6A264 1 0>,
				<DCC_READ 0x03D6A268 1 0>,
				<DCC_READ 0x03D6A26C 1 0>,
				<DCC_READ 0x03D6A270 1 0>,
				<DCC_READ 0x03D6A274 1 0>,
				<DCC_READ 0x03D6A278 1 0>,
				<DCC_READ 0x03D6A27C 1 0>,
				<DCC_READ 0x03D6A280 1 0>,
				<DCC_READ 0x03D6A284 1 0>,
				<DCC_READ 0x03D6A288 1 0>,
				<DCC_READ 0x03D6A28C 1 0>,
				<DCC_READ 0x03D6A290 1 0>,
				<DCC_READ 0x03D6A294 1 0>,
				<DCC_READ 0x03D6A298 1 0>,
				<DCC_READ 0x03D6A29C 1 0>,
				<DCC_READ 0x03D6A2A0 1 0>,
				<DCC_READ 0x03D6A2A4 1 0>,
				<DCC_READ 0x03D6A2A8 1 0>,
				<DCC_READ 0x03D6A2AC 1 0>,
				<DCC_READ 0x03D6A2B0 1 0>,
				<DCC_READ 0x03D6A2B4 1 0>,
				<DCC_READ 0x03D6A2B8 1 0>,
				<DCC_READ 0x03D6A2BC 1 0>,
				<DCC_READ 0x03D6A2C0 1 0>,
				<DCC_READ 0x03D6A2C4 1 0>,
				<DCC_READ 0x03D6A2C8 1 0>,
				<DCC_READ 0x03D6A2CC 1 0>,
				<DCC_READ 0x03D6A400 1 0>,
				<DCC_READ 0x03D6A404 1 0>,
				<DCC_READ 0x03D6A408 1 0>,
				<DCC_READ 0x03D6A40C 1 0>,
				<DCC_READ 0x03D6A410 1 0>,
				<DCC_READ 0x03D6A414 1 0>,
				<DCC_READ 0x03D6A418 1 0>,
				<DCC_READ 0x03D6A41C 1 0>,
				<DCC_READ 0x03D6A420 1 0>,
				<DCC_READ 0x03D6A424 1 0>,
				<DCC_READ 0x03D6A428 1 0>,
				<DCC_READ 0x03D6A42C 1 0>,
				<DCC_READ 0x03D6A430 1 0>,
				<DCC_READ 0x03D6A434 1 0>,
				<DCC_READ 0x03D6A438 1 0>,
				<DCC_READ 0x03D6A43C 1 0>,
				<DCC_READ 0x03D6A440 1 0>,
				<DCC_READ 0x03D6A444 1 0>,
				<DCC_READ 0x03D6A448 1 0>,
				<DCC_READ 0x03D6A44C 1 0>,
				<DCC_READ 0x03D6A450 1 0>,
				<DCC_READ 0x03D6A454 1 0>,
				<DCC_READ 0x03D6A458 1 0>,
				<DCC_READ 0x03D6A45C 1 0>,
				<DCC_READ 0x03D6A460 1 0>,
				<DCC_READ 0x03D6A464 1 0>,
				<DCC_READ 0x03D6A468 1 0>,
				<DCC_READ 0x03D6A46C 1 0>,
				<DCC_READ 0x03D6A470 1 0>,
				<DCC_READ 0x03D6A474 1 0>,
				<DCC_READ 0x03D6A478 1 0>,
				<DCC_READ 0x03D6A47C 1 0>,
				<DCC_READ 0x03D6A480 1 0>,
				<DCC_READ 0x03D6A484 1 0>,
				<DCC_READ 0x03D6A488 1 0>,
				<DCC_READ 0x03D6A48C 1 0>,
				<DCC_READ 0x03D6A490 1 0>,
				<DCC_READ 0x03D6A494 1 0>,
				<DCC_READ 0x03D6A498 1 0>,
				<DCC_READ 0x03D6A49C 1 0>,
				<DCC_READ 0x03D6A4A0 1 0>,
				<DCC_READ 0x03D6A4A4 1 0>,
				<DCC_READ 0x03D6A4A8 1 0>,
				<DCC_READ 0x03D6A4AC 1 0>,
				<DCC_READ 0x03D6A500 1 0>,
				<DCC_READ 0x03D90000 1 0>,
				<DCC_READ 0x03D90004 1 0>,
				<DCC_READ 0x03D90008 1 0>,
				<DCC_READ 0x03D9000C 1 0>,
				<DCC_READ 0x03D90010 1 0>,
				<DCC_READ 0x03D90014 1 0>,
				<DCC_READ 0x03D90018 1 0>,
				<DCC_READ 0x03D9001C 1 0>,
				<DCC_READ 0x03D90020 1 0>,
				<DCC_READ 0x03D90024 1 0>,
				<DCC_READ 0x03D90028 1 0>,
				<DCC_READ 0x03D9002C 1 0>,
				<DCC_READ 0x03D90030 1 0>,
				<DCC_READ 0x03D90034 1 0>,
				<DCC_READ 0x03D90038 1 0>,
				<DCC_READ 0x03D9003C 1 0>,
				<DCC_READ 0x03D91000 1 0>,
				<DCC_READ 0x03D91004 1 0>,
				<DCC_READ 0x03D91008 1 0>,
				<DCC_READ 0x03D9100C 1 0>,
				<DCC_READ 0x03D91010 1 0>,
				<DCC_READ 0x03D91014 1 0>,
				<DCC_READ 0x03D91018 1 0>,
				<DCC_READ 0x03D9101C 1 0>,
				<DCC_READ 0x03D91020 1 0>,
				<DCC_READ 0x03D91024 1 0>,
				<DCC_READ 0x03D91028 1 0>,
				<DCC_READ 0x03D9102C 1 0>,
				<DCC_READ 0x03D91030 1 0>,
				<DCC_READ 0x03D91034 1 0>,
				<DCC_READ 0x03D91038 1 0>,
				<DCC_READ 0x03D9103C 1 0>,
				<DCC_READ 0x03D9E0C8 1 0>,
				<DCC_READ 0x221C8118 1 0>,
				<DCC_READ 0x221C2148 1 0>;
		};

		link_list_1 {
			qcom,curr-link-list = <4>;
			qcom,data-sink = "sram";
			qcom,link-list = <DCC_READ 0x240e0010 1 0>,
				<DCC_READ 0x240e0020 8 0>,
				<DCC_READ 0x240e0248 1 0>,
				<DCC_READ 0x245f0010 1 0>,
				<DCC_READ 0x245f0020 8 0>,
				<DCC_READ 0x245f0248 1 0>,
				<DCC_READ 0x247f0010 1 0>,
				<DCC_READ 0x247f0020 8 0>,
				<DCC_READ 0x247f0248 1 0>,
				<DCC_READ 0x24330010 1 0>,
				<DCC_READ 0x24330020 8 0>,
				<DCC_READ 0x24330248 1 0>,
				<DCC_READ 0x240e1018 1 0>,
				<DCC_READ 0x240e1008 1 0>,
				<DCC_LOOP 0x9 0 0>,
				<DCC_READ 0x240e1010 2 0>,
				<DCC_LOOP 0x1 0 0>,
				<DCC_READ 0x245f2018 1 0>,
				<DCC_READ 0x245f2008 1 0>,
				<DCC_LOOP 0x3 0 0>,
				<DCC_READ 0x245f2010 2 0>,
				<DCC_LOOP 0x1 0 0>,
				<DCC_READ 0x247f2018 1 0>,
				<DCC_READ 0x247f2008 1 0>,
				<DCC_LOOP 0x3 0 0>,
				<DCC_READ 0x247f2010 2 0>,
				<DCC_LOOP 0x1 0 0>,
				<DCC_READ 0x24331018 1 0>,
				<DCC_READ 0x24331008 1 0>,
				<DCC_LOOP 0x8 0 0>,
				<DCC_READ 0x24331010 2 0>,
				<DCC_LOOP 0x1 0 0>,
				<DCC_READ 0x6802028 1 0>,
				<DCC_READ 0x7200408 1 0>,
				<DCC_READ 0x7200404 1 0>,
				<DCC_READ 0x6800000 1 0>,
				<DCC_READ 0x68C0404 1 0>,
				<DCC_READ 0x68C0408 1 0>,
				<DCC_READ 0x01780010 1 0>,
				<DCC_READ 0x01780020 8 0>,
				<DCC_READ 0x01780248 1 0>,
				<DCC_READ 0x01782018 1 0>,
				<DCC_READ 0x01782008 1 0>,
				<DCC_LOOP 0xc 0 0>,
				<DCC_READ 0x01782010 2 0>,
				<DCC_LOOP 0x1 0 0>,
				<DCC_READ 0x01783018 1 0>,
				<DCC_READ 0x01783008 1 0>,
				<DCC_LOOP 0x11 0 0>,
				<DCC_READ 0x01783010 2 0>,
				<DCC_LOOP 0x1 0 0>,
				<DCC_READ 0x01680010 1 0>,
				<DCC_READ 0x01680020 8 0>,
				<DCC_READ 0x01681048 1 0>,
				<DCC_READ 0x01682018 1 0>,
				<DCC_READ 0x01682008 1 0>,
				<DCC_LOOP 0x6 0 0>,
				<DCC_READ 0x01682010 2 0>,
				<DCC_LOOP 0x1 0 0>,
				<DCC_READ 0x016e0010 1 0>,
				<DCC_READ 0x016e0020 8 0>,
				<DCC_READ 0x016e0248 1 0>,
				<DCC_READ 0x016e1018 1 0>,
				<DCC_READ 0x016e1008 1 0>,
				<DCC_LOOP 0x4 0 0>,
				<DCC_READ 0x016e1010 2 0>,
				<DCC_LOOP 0x1 0 0>,
				<DCC_READ 0x016e1098 1 0>,
				<DCC_READ 0x016e1088 1 0>,
				<DCC_LOOP 0x3 0 0>,
				<DCC_READ 0x016e1090 2 0>,
				<DCC_LOOP 0x1 0 0>,
				<DCC_READ 0x016e1118 1 0>,
				<DCC_READ 0x016e1108 1 0>,
				<DCC_LOOP 0x7 0 0>,
				<DCC_READ 0x016e1110 2 0>,
				<DCC_LOOP 0x1 0 0>,
				<DCC_READ 0x01700010 1 0>,
				<DCC_READ 0x01700020 8 0>,
				<DCC_READ 0x01700248 1 0>,
				<DCC_READ 0x01701018 1 0>,
				<DCC_READ 0x01701008 1 0>,
				<DCC_LOOP 0x4 0 0>,
				<DCC_READ 0x01701010 2 0>,
				<DCC_LOOP 0x1 0 0>,
				<DCC_READ 0x01701098 1 0>,
				<DCC_READ 0x01701088 1 0>,
				<DCC_LOOP 0x2 0 0>,
				<DCC_READ 0x01701090 2 0>,
				<DCC_LOOP 0x1 0 0>,
				<DCC_READ 0x01701118 1 0>,
				<DCC_READ 0x01701108 1 0>,
				<DCC_LOOP 0x3 0 0>,
				<DCC_READ 0x01701110 2 0>,
				<DCC_LOOP 0x1 0 0>,
				<DCC_READ 0x01600010 1 0>,
				<DCC_READ 0x01600020 8 0>,
				<DCC_READ 0x01600248 2 0>,
				<DCC_READ 0x01600258 1 0>,
				<DCC_READ 0x01602018 1 0>,
				<DCC_READ 0x01602008 1 0>,
				<DCC_LOOP 0x7 0 0>,
				<DCC_READ 0x01602010 2 0>,
				<DCC_LOOP 0x1 0 0>,
				<DCC_READ 0x01602098 1 0>,
				<DCC_READ 0x01602088 1 0>,
				<DCC_LOOP 0x2 0 0>,
				<DCC_READ 0x01602090 2 0>,
				<DCC_LOOP 0x1 0 0>,
				<DCC_READ 0x01602118 1 0>,
				<DCC_READ 0x01602108 1 0>,
				<DCC_LOOP 0x3 0 0>,
				<DCC_READ 0x01602110 2 0>,
				<DCC_LOOP 0x1 0 0>,
				<DCC_READ 0x01602198 1 0>,
				<DCC_READ 0x01602188 1 0>,
				<DCC_LOOP 0x3 0 0>,
				<DCC_READ 0x01602190 2 0>,
				<DCC_LOOP 0x1 0 0>,
				<DCC_READ 0x01602218 1 0>,
				<DCC_READ 0x01602208 1 0>,
				<DCC_LOOP 0x2 0 0>,
				<DCC_READ 0x01602210 2 0>,
				<DCC_LOOP 0x1 0 0>,
				<DCC_READ 0x01602298 1 0>,
				<DCC_READ 0x01602288 1 0>,
				<DCC_LOOP 0x2 0 0>,
				<DCC_READ 0x01602290 2 0>,
				<DCC_LOOP 0x1 0 0>,
				<DCC_READ 0x01500010 1 0>,
				<DCC_READ 0x01500020 8 0>,
				<DCC_READ 0x01500248 1 0>,
				<DCC_READ 0x01500448 1 0>,
				<DCC_READ 0x01502018 1 0>,
				<DCC_READ 0x01502008 1 0>,
				<DCC_LOOP 0x7 0 0>,
				<DCC_READ 0x01502010 2 0>,
				<DCC_LOOP 0x1 0 0>,
				<DCC_READ 0x01502098 1 0>,
				<DCC_READ 0x01502088 1 0>,
				<DCC_LOOP 0x7 0 0>,
				<DCC_READ 0x01502090 2 0>,
				<DCC_LOOP 0x1 0 0>,
				<DCC_READ 0x17610010 1 0>,
				<DCC_READ 0x17610020 8 0>,
				<DCC_READ 0x17610248 1 0>,
				<DCC_READ 0x17612018 1 0>,
				<DCC_READ 0x17612008 1 0>,
				<DCC_LOOP 0x6 0 0>,
				<DCC_READ 0x17612010 2 0>,
				<DCC_LOOP 0x1 0 0>,
				<DCC_READ 0x17100104 29 0>,
				<DCC_READ 0x17100204 29 0>,
				<DCC_READ 0x17100384 29 0>,
				<DCC_READ 0x178A0250 1 0>,
				<DCC_READ 0x178A0254 1 0>,
				<DCC_READ 0x178A025C 1 0>,
				<DCC_READ 0xB281024 1 0>,
				<DCC_READ 0xBDE1034 1 0>,
				<DCC_READ 0xB201020 2 0>,
				<DCC_READ 0xB211020 2 0>,
				<DCC_READ 0xB221020 2 0>,
				<DCC_READ 0xB231020 2 0>,
				<DCC_READ 0xB204520 1 0>,
				<DCC_READ 0x17A00010 1 0>,
				<DCC_READ 0x17A10010 1 0>,
				<DCC_READ 0x17A20010 1 0>,
				<DCC_READ 0x17A30010 1 0>,
				<DCC_READ 0x17A00030 1 0>,
				<DCC_READ 0x17A10030 1 0>,
				<DCC_READ 0x17A20030 1 0>,
				<DCC_READ 0x17A30030 1 0>,
				<DCC_READ 0x17A00038 1 0>,
				<DCC_READ 0x17A10038 1 0>,
				<DCC_READ 0x17A20038 1 0>,
				<DCC_READ 0x17A30038 1 0>,
				<DCC_READ 0x17A00040 1 0>,
				<DCC_READ 0x17A10040 1 0>,
				<DCC_READ 0x17A20040 1 0>,
				<DCC_READ 0x17A30040 1 0>,
				<DCC_READ 0x17A00048 1 0>,
				<DCC_READ 0x17A00400 3 0>,
				<DCC_READ 0x17A10400 3 0>,
				<DCC_READ 0x17A20400 3 0>,
				<DCC_READ 0x17A30400 3 0>,
				<DCC_READ 0xC234004 5 0>,
				<DCC_LOOP 0x5 0 0>,
				<DCC_READ 0x17410000 6 0>,
				<DCC_READ 0x17411000 6 0>,
				<DCC_LOOP 0x1 0 0>,
				<DCC_READ 0x17D10200 320 0>,
				<DCC_READ 0x17120000 1 0>,
				<DCC_READ 0x17120008 1 0>,
				<DCC_READ 0x17120010 1 0>,
				<DCC_READ 0x17120018 1 0>,
				<DCC_READ 0x17120020 1 0>,
				<DCC_READ 0x17120028 1 0>,
				<DCC_READ 0x17120040 1 0>,
				<DCC_READ 0x17120048 1 0>,
				<DCC_READ 0x17120050 1 0>,
				<DCC_READ 0x17120058 1 0>,
				<DCC_READ 0x17120060 1 0>,
				<DCC_READ 0x17120068 1 0>,
				<DCC_READ 0x17120080 1 0>,
				<DCC_READ 0x17120088 1 0>,
				<DCC_READ 0x17120090 1 0>,
				<DCC_READ 0x17120098 1 0>,
				<DCC_READ 0x171200a0 1 0>,
				<DCC_READ 0x171200a8 1 0>,
				<DCC_READ 0x171200c0 1 0>,
				<DCC_READ 0x171200c8 1 0>,
				<DCC_READ 0x171200d0 1 0>,
				<DCC_READ 0x171200d8 1 0>,
				<DCC_READ 0x171200e0 1 0>,
				<DCC_READ 0x171200e8 1 0>,
				<DCC_READ 0x17120100 1 0>,
				<DCC_READ 0x17120108 1 0>,
				<DCC_READ 0x17120110 1 0>,
				<DCC_READ 0x17120118 1 0>,
				<DCC_READ 0x17120120 1 0>,
				<DCC_READ 0x17120128 1 0>,
				<DCC_READ 0x17120140 1 0>,
				<DCC_READ 0x17120148 1 0>,
				<DCC_READ 0x17120150 1 0>,
				<DCC_READ 0x17120158 1 0>,
				<DCC_READ 0x17120160 1 0>,
				<DCC_READ 0x17120168 1 0>,
				<DCC_READ 0x17120180 1 0>,
				<DCC_READ 0x17120188 1 0>,
				<DCC_READ 0x17120190 1 0>,
				<DCC_READ 0x17120198 1 0>,
				<DCC_READ 0x171201a0 1 0>,
				<DCC_READ 0x171201a8 1 0>,
				<DCC_READ 0x171201c0 1 0>,
				<DCC_READ 0x171201c8 1 0>,
				<DCC_READ 0x171201d0 1 0>,
				<DCC_READ 0x171201d8 1 0>,
				<DCC_READ 0x171201e0 1 0>,
				<DCC_READ 0x171201e8 1 0>,
				<DCC_READ 0x17120200 1 0>,
				<DCC_READ 0x17120208 1 0>,
				<DCC_READ 0x17120210 1 0>,
				<DCC_READ 0x17120218 1 0>,
				<DCC_READ 0x17120220 1 0>,
				<DCC_READ 0x17120228 1 0>,
				<DCC_READ 0x17120240 1 0>,
				<DCC_READ 0x17120248 1 0>,
				<DCC_READ 0x17120250 1 0>,
				<DCC_READ 0x17120258 1 0>,
				<DCC_READ 0x17120260 1 0>,
				<DCC_READ 0x17120268 1 0>,
				<DCC_READ 0x17120280 1 0>,
				<DCC_READ 0x17120288 1 0>,
				<DCC_READ 0x17120290 1 0>,
				<DCC_READ 0x17120298 1 0>,
				<DCC_READ 0x171202a0 1 0>,
				<DCC_READ 0x171202a8 1 0>,
				<DCC_READ 0x171202c0 1 0>,
				<DCC_READ 0x171202c8 1 0>,
				<DCC_READ 0x171202d0 1 0>,
				<DCC_READ 0x171202d8 1 0>,
				<DCC_READ 0x171202e0 1 0>,
				<DCC_READ 0x171202e8 1 0>,
				<DCC_READ 0x17120300 1 0>,
				<DCC_READ 0x17120308 1 0>,
				<DCC_READ 0x17120310 1 0>,
				<DCC_READ 0x17120318 1 0>,
				<DCC_READ 0x17120320 1 0>,
				<DCC_READ 0x17120328 1 0>,
				<DCC_READ 0x17120340 1 0>,
				<DCC_READ 0x17120348 1 0>,
				<DCC_READ 0x17120350 1 0>,
				<DCC_READ 0x17120358 1 0>,
				<DCC_READ 0x17120360 1 0>,
				<DCC_READ 0x17120368 1 0>,
				<DCC_READ 0x17120380 1 0>,
				<DCC_READ 0x17120388 1 0>,
				<DCC_READ 0x17120390 1 0>,
				<DCC_READ 0x17120398 1 0>,
				<DCC_READ 0x171203a0 1 0>,
				<DCC_READ 0x171203a8 1 0>,
				<DCC_READ 0x171203c0 1 0>,
				<DCC_READ 0x171203c8 1 0>,
				<DCC_READ 0x171203d0 1 0>,
				<DCC_READ 0x171203d8 1 0>,
				<DCC_READ 0x171203e0 1 0>,
				<DCC_READ 0x171203e8 1 0>,
				<DCC_READ 0x17120400 1 0>,
				<DCC_READ 0x17120408 1 0>,
				<DCC_READ 0x17120410 1 0>,
				<DCC_READ 0x17120418 1 0>,
				<DCC_READ 0x17120420 1 0>,
				<DCC_READ 0x17120428 1 0>,
				<DCC_READ 0x17120440 1 0>,
				<DCC_READ 0x17120448 1 0>,
				<DCC_READ 0x17120450 1 0>,
				<DCC_READ 0x17120458 1 0>,
				<DCC_READ 0x17120460 1 0>,
				<DCC_READ 0x17120468 1 0>,
				<DCC_READ 0x17120480 1 0>,
				<DCC_READ 0x17120488 1 0>,
				<DCC_READ 0x17120490 1 0>,
				<DCC_READ 0x17120498 1 0>,
				<DCC_READ 0x171204a0 1 0>,
				<DCC_READ 0x171204a8 1 0>,
				<DCC_READ 0x171204c0 1 0>,
				<DCC_READ 0x171204c8 1 0>,
				<DCC_READ 0x171204d0 1 0>,
				<DCC_READ 0x171204d8 1 0>,
				<DCC_READ 0x171204e0 1 0>,
				<DCC_READ 0x171204e8 1 0>,
				<DCC_READ 0x17120500 1 0>,
				<DCC_READ 0x17120508 1 0>,
				<DCC_READ 0x17120510 1 0>,
				<DCC_READ 0x17120518 1 0>,
				<DCC_READ 0x17120520 1 0>,
				<DCC_READ 0x17120528 1 0>,
				<DCC_READ 0x17120540 1 0>,
				<DCC_READ 0x17120548 1 0>,
				<DCC_READ 0x17120550 1 0>,
				<DCC_READ 0x17120558 1 0>,
				<DCC_READ 0x17120560 1 0>,
				<DCC_READ 0x17120568 1 0>,
				<DCC_READ 0x17120580 1 0>,
				<DCC_READ 0x17120588 1 0>,
				<DCC_READ 0x17120590 1 0>,
				<DCC_READ 0x17120598 1 0>,
				<DCC_READ 0x171205a0 1 0>,
				<DCC_READ 0x171205a8 1 0>,
				<DCC_READ 0x171205c0 1 0>,
				<DCC_READ 0x171205c8 1 0>,
				<DCC_READ 0x171205d0 1 0>,
				<DCC_READ 0x171205d8 1 0>,
				<DCC_READ 0x171205e0 1 0>,
				<DCC_READ 0x171205e8 1 0>,
				<DCC_READ 0x17120600 1 0>,
				<DCC_READ 0x17120608 1 0>,
				<DCC_READ 0x17120610 1 0>,
				<DCC_READ 0x17120618 1 0>,
				<DCC_READ 0x17120620 1 0>,
				<DCC_READ 0x17120628 1 0>,
				<DCC_READ 0x17120640 1 0>,
				<DCC_READ 0x17120648 1 0>,
				<DCC_READ 0x17120650 1 0>,
				<DCC_READ 0x17120658 1 0>,
				<DCC_READ 0x17120660 1 0>,
				<DCC_READ 0x17120668 1 0>,
				<DCC_READ 0x17120680 1 0>,
				<DCC_READ 0x17120688 1 0>,
				<DCC_READ 0x17120690 1 0>,
				<DCC_READ 0x17120698 1 0>,
				<DCC_READ 0x171206a0 1 0>,
				<DCC_READ 0x171206a8 1 0>,
				<DCC_READ 0x171206c0 1 0>,
				<DCC_READ 0x171206c8 1 0>,
				<DCC_READ 0x171206d0 1 0>,
				<DCC_READ 0x171206d8 1 0>,
				<DCC_READ 0x171206e0 1 0>,
				<DCC_READ 0x171206e8 1 0>,
				<DCC_READ 0x1712e000 1 0>,
				<DCC_READ 0x110004 1 0>,
				<DCC_READ 0x110008 1 0>,
				<DCC_READ 0x11003C 1 0>,
				<DCC_READ 0x110040 1 0>,
				<DCC_READ 0x110044 1 0>,
				<DCC_READ 0x17603C 1 0>,
				<DCC_READ 0x17890000 1 0>,
				<DCC_READ 0x17890008 1 0>,
				<DCC_READ 0x1789000c 1 0>,
				<DCC_READ 0x17890010 1 0>,
				<DCC_READ 0x17890014 1 0>,
				<DCC_READ 0x17890018 1 0>,
				<DCC_READ 0x1789001c 1 0>,
				<DCC_READ 0x17890020 1 0>,
				<DCC_READ 0x17890024 1 0>,
				<DCC_READ 0x17890028 1 0>,
				<DCC_READ 0x1789002c 1 0>,
				<DCC_READ 0x17890030 1 0>,
				<DCC_READ 0x17890034 1 0>,
				<DCC_READ 0x17890038 1 0>,
				<DCC_READ 0x1789003c 1 0>,
				<DCC_READ 0x17890040 1 0>,
				<DCC_READ 0x17890044 1 0>,
				<DCC_READ 0x17890048 1 0>,
				<DCC_READ 0x1789004c 1 0>,
				<DCC_READ 0x17890068 1 0>,
				<DCC_READ 0x1789006c 1 0>,
				<DCC_READ 0x178900f0 1 0>,
				<DCC_READ 0x178900f4 1 0>,
				<DCC_READ 0x178900f8 1 0>,
				<DCC_READ 0x178900fc 1 0>,
				<DCC_READ 0x17890100 1 0>,
				<DCC_READ 0x17890104 1 0>,
				<DCC_READ 0x17891000 1 0>,
				<DCC_READ 0x17892000 1 0>,
				<DCC_READ 0x17893000 1 0>,
				<DCC_READ 0x17893004 1 0>,
				<DCC_READ 0x17898000 1 0>,
				<DCC_READ 0x17898004 1 0>,
				<DCC_READ 0x17898008 1 0>,
				<DCC_READ 0x1789800c 1 0>,
				<DCC_READ 0x17898010 1 0>,
				<DCC_READ 0x17898014 1 0>,
				<DCC_WRITE 0x17891000 0x0 0>,
				<DCC_WRITE 0x17892000 0x0 0>,
				<DCC_WRITE 0x17893000 0x0 0>,
				<DCC_WRITE 0x17893004 0x0 0>,
				<DCC_READ 0x17891000 1 0>,
				<DCC_READ 0x17892000 1 0>,
				<DCC_READ 0x17893000 1 0>,
				<DCC_READ 0x17893004 1 0>,
				<DCC_READ 0x17980000 256 0>,
				<DCC_READ 0x17980800 256 0>,
				<DCC_READ 0x17981000 16 0>,
				<DCC_READ 0x17981060 8 0>,
				<DCC_READ 0x179810a0 1 0>,
				<DCC_READ 0x179810a4 1 0>,
				<DCC_READ 0x179810b0 1 0>,
				<DCC_READ 0x179810c0 1 0>,
				<DCC_READ 0x179810c4 1 0>,
				<DCC_READ 0x179810c8 1 0>,
				<DCC_READ 0x179810cc 1 0>,
				<DCC_READ 0x17981100 1 0>,
				<DCC_READ 0x17981104 1 0>,
				<DCC_READ 0x17981108 1 0>,
				<DCC_READ 0x1798110c 1 0>,
				<DCC_READ 0x17981110 1 0>,
				<DCC_READ 0x17981114 1 0>,
				<DCC_READ 0x17981118 1 0>,
				<DCC_READ 0x1798111c 1 0>,
				<DCC_READ 0x17981120 1 0>,
				<DCC_READ 0x17981124 1 0>,
				<DCC_READ 0x17981128 1 0>,
				<DCC_READ 0x1798112c 1 0>,
				<DCC_READ 0x17981130 1 0>,
				<DCC_READ 0x17981134 1 0>,
				<DCC_READ 0x17981138 1 0>,
				<DCC_READ 0x1798113c 1 0>,
				<DCC_READ 0x17981140 1 0>,
				<DCC_READ 0x17981144 1 0>,
				<DCC_READ 0x17981148 1 0>,
				<DCC_READ 0x1798114c 1 0>,
				<DCC_READ 0x17981150 1 0>,
				<DCC_READ 0x17981154 1 0>,
				<DCC_READ 0x17981158 1 0>,
				<DCC_READ 0x1798115c 1 0>,
				<DCC_READ 0x17981160 1 0>,
				<DCC_READ 0x17981164 1 0>,
				<DCC_READ 0x17981168 1 0>,
				<DCC_READ 0x1798116c 1 0>,
				<DCC_READ 0x17981170 1 0>,
				<DCC_READ 0x17981174 1 0>,
				<DCC_READ 0x17981178 1 0>,
				<DCC_READ 0x1798117c 1 0>,
				<DCC_READ 0x17981180 1 0>,
				<DCC_READ 0x17981184 1 0>,
				<DCC_READ 0x17981188 1 0>,
				<DCC_READ 0x1798118c 1 0>,
				<DCC_READ 0x17981190 1 0>,
				<DCC_READ 0x17981194 1 0>,
				<DCC_READ 0x17981198 1 0>,
				<DCC_READ 0x1798119c 1 0>,
				<DCC_READ 0x179811a0 1 0>,
				<DCC_READ 0x179811a4 1 0>,
				<DCC_READ 0x179811a8 1 0>,
				<DCC_READ 0x179811ac 1 0>,
				<DCC_READ 0x179811b0 1 0>,
				<DCC_READ 0x179811b4 1 0>,
				<DCC_READ 0x179811b8 1 0>,
				<DCC_READ 0x179811bc 1 0>,
				<DCC_READ 0x179811c0 1 0>,
				<DCC_READ 0x179811c4 1 0>,
				<DCC_READ 0x179811c8 1 0>,
				<DCC_READ 0x179811cc 1 0>,
				<DCC_READ 0x179811d0 1 0>,
				<DCC_READ 0x179811d4 1 0>,
				<DCC_READ 0x179811d8 1 0>,
				<DCC_READ 0x17981ffc 1 0>,
				<DCC_WRITE 0x179811d4 0x0 0>,
				<DCC_READ 0x179811d4 1 0>,
				<DCC_READ 0x179811d8 1 0>,
				<DCC_WRITE 0x179811d4 0x1 0>,
				<DCC_READ 0x179811d4 1 0>,
				<DCC_READ 0x179811d8 1 0>,
				<DCC_WRITE 0x179811d4 0x2 0>,
				<DCC_READ 0x179811d4 1 0>,
				<DCC_READ 0x179811d8 1 0>,
				<DCC_WRITE 0x179811d4 0x3 0>,
				<DCC_READ 0x179811d4 1 0>,
				<DCC_READ 0x179811d8 1 0>,
				<DCC_WRITE 0x179811d4 0x4 0>,
				<DCC_READ 0x179811d4 1 0>,
				<DCC_READ 0x179811d8 1 0>,
				<DCC_WRITE 0x179811d4 0x5 0>,
				<DCC_READ 0x179811d4 1 0>,
				<DCC_READ 0x179811d8 1 0>,
				<DCC_WRITE 0x179811d4 0x6 0>,
				<DCC_READ 0x179811d4 1 0>,
				<DCC_READ 0x179811d8 1 0>,
				<DCC_WRITE 0x179811d4 0x7 0>,
				<DCC_READ 0x179811d4 1 0>,
				<DCC_READ 0x179811d8 1 0>,
				<DCC_WRITE 0x179811d4 0x8 0>,
				<DCC_READ 0x179811d4 1 0>,
				<DCC_READ 0x179811d8 1 0>,
				<DCC_WRITE 0x179811d4 0x9 0>,
				<DCC_READ 0x179811d4 1 0>,
				<DCC_READ 0x179811d8 1 0>,
				<DCC_WRITE 0x179811d4 0xa 0>,
				<DCC_READ 0x179811d4 1 0>,
				<DCC_READ 0x179811d8 1 0>,
				<DCC_WRITE 0x179811d4 0xb 0>,
				<DCC_READ 0x179811d4 1 0>,
				<DCC_READ 0x179811d8 1 0>,
				<DCC_WRITE 0x179811d4 0xc 0>,
				<DCC_READ 0x179811d4 1 0>,
				<DCC_READ 0x179811d8 1 0>,
				<DCC_WRITE 0x179811d4 0xd 0>,
				<DCC_READ 0x179811d4 1 0>,
				<DCC_READ 0x179811d8 1 0>,
				<DCC_WRITE 0x179811d4 0xe 0>,
				<DCC_READ 0x179811d4 1 0>,
				<DCC_READ 0x179811d8 1 0>,
				<DCC_WRITE 0x179811d4 0xf 0>,
				<DCC_READ 0x179811d4 1 0>,
				<DCC_READ 0x179811d8 1 0>,
				<DCC_WRITE 0x179811d4 0x10 0>,
				<DCC_READ 0x179811d4 1 0>,
				<DCC_READ 0x179811d8 1 0>,
				<DCC_WRITE 0x179811d4 0x11 0>,
				<DCC_READ 0x179811d4 1 0>,
				<DCC_READ 0x179811d8 1 0>,
				<DCC_WRITE 0x179811d4 0x12 0>,
				<DCC_READ 0x179811d4 1 0>,
				<DCC_READ 0x179811d8 1 0>,
				<DCC_WRITE 0x179811d4 0x13 0>,
				<DCC_READ 0x179811d4 1 0>,
				<DCC_READ 0x179811d8 1 0>,
				<DCC_READ 0x1740003C 1 0>,
				<DCC_READ 0x17600238 1 0>,
				<DCC_READ 0x1760043C 1 0>,
				<DCC_READ 0x17600440 1 0>,
				<DCC_READ 0x17600240 1 0>,
				<DCC_READ 0x17600244 1 0>,
				<DCC_READ 0x17600248 1 0>,
				<DCC_READ 0x1760024c 1 0>,
				<DCC_READ 0x17600250 1 0>,
				<DCC_READ 0x17600254 1 0>,
				<DCC_READ 0x17600258 1 0>,
				<DCC_READ 0x1760025C 1 0>,
				<DCC_READ 0x17600260 1 0>,
				<DCC_READ 0x17600264 1 0>,
				<DCC_READ 0x17600268 1 0>,
				<DCC_READ 0x17600270 1 0>,
				<DCC_READ 0x17600274 1 0>,
				<DCC_READ 0x17600518 1 0>,
				<DCC_READ 0x1760051C 1 0>,
				<DCC_READ 0x17600520 1 0>,
				<DCC_READ 0x17600524 1 0>,
				<DCC_READ 0x17600528 1 0>,
				<DCC_READ 0x1760052C 1 0>,
				<DCC_READ 0x17600530 1 0>;
		};
	};

	mem_dump {
		compatible = "qcom,mem-dump";
		memory-region = <&dump_mem>;

		static_dump {
			qcom,static-mem-dump;

			c0_context {
				qcom,dump-size = <0x800>;
				qcom,dump-id = <0x0>;
			};

			c100_context {
				qcom,dump-size = <0x800>;
				qcom,dump-id = <0x1>;
			};

			c200_context {
				qcom,dump-size = <0x800>;
				qcom,dump-id = <0x2>;
			};

			c300_context {
				qcom,dump-size = <0x800>;
				qcom,dump-id = <0x3>;
			};

			c400_context {
				qcom,dump-size = <0x800>;
				qcom,dump-id = <0x4>;
			};

			c500_context {
				qcom,dump-size = <0x800>;
				qcom,dump-id = <0x5>;
			};

			c600_context {
				qcom,dump-size = <0x800>;
				qcom,dump-id = <0x6>;
			};

			c700_context {
				qcom,dump-size = <0x800>;
				qcom,dump-id = <0x7>;
			};

			l1_icache0 {
				qcom,dump-size = <0x22100>;
				qcom,dump-id = <0x60>;
			};

			l1_icache100 {
				qcom,dump-size = <0x22100>;
				qcom,dump-id = <0x61>;
			};

			l1_icache200 {
				qcom,dump-size = <0x22100>;
				qcom,dump-id = <0x62>;
			};

			l1_icache300 {
				qcom,dump-size = <0x22100>;
				qcom,dump-id = <0x63>;
			};

			l1_icache400 {
				qcom,dump-size = <0x22100>;
				qcom,dump-id = <0x64>;
			};

			l1_icache500 {
				qcom,dump-size = <0x22100>;
				qcom,dump-id = <0x65>;
			};

			l1_icache600 {
				qcom,dump-size = <0x22100>;
				qcom,dump-id = <0x66>;
			};

			l1_icache700 {
				qcom,dump-size = <0x22100>;
				qcom,dump-id = <0x67>;
			};

			l1_dcache0 {
				qcom,dump-size = <0x12100>;
				qcom,dump-id = <0x80>;
			};

			l1_dcache100 {
				qcom,dump-size = <0x12100>;
				qcom,dump-id = <0x81>;
			};

			l1_dcache200 {
				qcom,dump-size = <0x1a100>;
				qcom,dump-id = <0x82>;
			};

			l1_dcache300 {
				qcom,dump-size = <0x1a100>;
				qcom,dump-id = <0x83>;
			};

			l1_dcache400 {
				qcom,dump-size = <0x1a100>;
				qcom,dump-id = <0x84>;
			};

			l1_dcache500 {
				qcom,dump-size = <0x1a100>;
				qcom,dump-id = <0x85>;
			};

			l1_dcache600 {
				qcom,dump-size = <0x1a100>;
				qcom,dump-id = <0x86>;
			};

			l1_dcache700 {
				qcom,dump-size = <0x1a100>;
				qcom,dump-id = <0x87>;
			};

			l1_itlb700 {
				qcom,dump-size = <0x600>;
				qcom,dump-id = <0x27>;
			};

			l1_dtlb700 {
				qcom,dump-size = <0xa00>;
				qcom,dump-id = <0x47>;
			};

			l2_cache0 {
				qcom,dump-size = <0x90100>;
				qcom,dump-id = <0xc0>;
			};

			l2_cache100 {
				qcom,dump-size = <0x90100>;
				qcom,dump-id = <0xc1>;
			};

			l2_cache200 {
				qcom,dump-size = <0xd0100>;
				qcom,dump-id = <0xc2>;
			};

			l2_cache300 {
				qcom,dump-size = <0xd0100>;
				qcom,dump-id = <0xc3>;
			};

			l2_cache400 {
				qcom,dump-size = <0xd0100>;
				qcom,dump-id = <0xc4>;
			};

			l2_cache500 {
				qcom,dump-size = <0xd0100>;
				qcom,dump-id = <0xc5>;
			};

			l2_cache600 {
				qcom,dump-size = <0xd0100>;
				qcom,dump-id = <0xc6>;
			};

			l2_cache700 {
				qcom,dump-size = <0x340100>;
				qcom,dump-id = <0xc7>;
			};

			l2_tlb0 {
				qcom,dump-size = <0xf700>;
				qcom,dump-id = <0x120>;
			};

			l2_tlb100 {
				qcom,dump-size = <0xf700>;
				qcom,dump-id = <0x121>;
			};

			l2_tlb700 {
				qcom,dump-size = <0xa900>;
				qcom,dump-id = <0x127>;
			};

			l1dcdirty0 {
				qcom,dump-size = <0x2100>;
				qcom,dump-id = <0x170>;
			};

			l1dcdirty100 {
				qcom,dump-size = <0x2100>;
				qcom,dump-id = <0x171>;
			};

			l1dcmte0 {
				qcom,dump-size = <0x2100>;
				qcom,dump-id = <0x180>;
			};

			l1dcmte100 {
				qcom,dump-size = <0x2100>;
				qcom,dump-id = <0x181>;
			};

			l2dcmte0 {
				qcom,dump-size = <0x10100>;
				qcom,dump-id = <0x190>;
			};

			l2dcmte100 {
				qcom,dump-size = <0x10100>;
				qcom,dump-id = <0x191>;
			};

			l0mopca700 {
				qcom,dump-size = <0x4100>;
				qcom,dump-id = <0x1a7>;
			};

			l2victim700 {
				qcom,dump-size = <0x2100>;
				qcom,dump-id = <0x1e7>;
			};

			l2tldtcsp200 {
				qcom,dump-size = <0x7900>;
				qcom,dump-id = <0x202>;
			};

			l2tldtcsp300 {
				qcom,dump-size = <0x7900>;
				qcom,dump-id = <0x203>;
			};

			l2tldtcsp400 {
				qcom,dump-size = <0x7900>;
				qcom,dump-id = <0x204>;
			};

			l2tldtcsp500 {
				qcom,dump-size = <0x7900>;
				qcom,dump-id = <0x205>;
			};

			l2tldtcsp600 {
				qcom,dump-size = <0x7900>;
				qcom,dump-id = <0x206>;
			};

			l2tldtcmp200 {
				qcom,dump-size = <0x1300>;
				qcom,dump-id = <0x212>;
			};

			l2tldtcmp300 {
				qcom,dump-size = <0x1300>;
				qcom,dump-id = <0x213>;
			};

			l2tldtcmp400 {
				qcom,dump-size = <0x1300>;
				qcom,dump-id = <0x214>;
			};

			l2tldtcmp500 {
				qcom,dump-size = <0x1300>;
				qcom,dump-id = <0x215>;
			};

			l2tldtcmp600 {
				qcom,dump-size = <0x1300>;
				qcom,dump-id = <0x216>;
			};

			cpuss_reg {
				qcom,dump-size = <0x36000>;
				qcom,dump-id = <0xef>;
			};

			rpmh {
				qcom,dump-size = <0x400000>;
				qcom,dump-id = <0xec>;
			};

			rpm_sw {
				qcom,dump-size = <0x28000>;
				qcom,dump-id = <0xea>;
			};

			pmic {
				qcom,dump-size = <0x200000>;
				qcom,dump-id = <0xe4>;
			};

			fcm {
				qcom,dump-size = <0x8400>;
				qcom,dump-id = <0xee>;
			};

			etf_swao {
				qcom,dump-size = <0x10000>;
				qcom,dump-id = <0xf1>;
			};

			etr_reg {
				qcom,dump-size = <0x1000>;
				qcom,dump-id = <0x100>;
			};

			etfswao_reg {
				qcom,dump-size = <0x1000>;
				qcom,dump-id = <0x102>;
			};

			etr1_reg {
				qcom,dump-size = <0x1000>;
				qcom,dump-id = <0x105>;
			};

			misc_data {
				qcom,dump-size = <0x1000>;
				qcom,dump-id = <0xe8>;
			};

			etf_slpi {
				qcom,dump-size = <0x4000>;
				qcom,dump-id = <0xf3>;
			};

			etfslpi_reg {
				qcom,dump-size = <0x1000>;
				qcom,dump-id = <0x103>;
			};

			etf_lpass {
				qcom,dump-size = <0x4000>;
				qcom,dump-id = <0xf4>;
			};

			etflpass_reg {
				qcom,dump-size = <0x1000>;
				qcom,dump-id = <0x104>;
			};

			osm_reg {
				qcom,dump-size = <0x400>;
				qcom,dump-id = <0x163>;
			};

			pcu_reg {
				qcom,dump-size = <0x400>;
				qcom,dump-id = <0x164>;
			};

			fsm_data {
				qcom,dump-size = <0x400>;
				qcom,dump-id = <0x165>;
			};

			spr_cpu0 {
				qcom,dump-size = <0x2000>;
				qcom,dump-id = <0x1f0>;
			};

			spr_cpu1 {
				qcom,dump-size = <0x2000>;
				qcom,dump-id = <0x1f1>;
			};

			spr_cpu2 {
				qcom,dump-size = <0x2000>;
				qcom,dump-id = <0x1f2>;
			};

			spr_cpu3 {
				qcom,dump-size = <0x2000>;
				qcom,dump-id = <0x1f3>;
			};

			spr_cpu4 {
				qcom,dump-size = <0x2000>;
				qcom,dump-id = <0x1f4>;
			};

			spr_cpu5 {
				qcom,dump-size = <0x2000>;
				qcom,dump-id = <0x1f5>;
			};

			spr_cpu6 {
				qcom,dump-size = <0x2000>;
				qcom,dump-id = <0x1f6>;
			};

			spr_cpu7 {
				qcom,dump-size = <0x2000>;
				qcom,dump-id = <0x1f7>;
			};

			scandump_smmu {
				qcom,dump-size = <0x40000>;
				qcom,dump-id = <0x220>;
			};

			scandump_gpu {
				qcom,dump-size = <0x300000>;
				qcom,dump-id = <0x221>;
			};
		};
	};
};
